VERSION ""

NS_ :

BS_:

BU_: Turbocharger OnBoardDataLogger OffBoardDiagnosticTool2 OffBoardDiagnosticTool1 FileServer ParkingBrakeController SeatControl2 FanDriveController SteeringColumnUnit CommunicationUnitRadio CommunicationUnitSatellite CommunicationUnitCellular PropulsionBatteryCharger ChassisController2 ChassisController1 EngineValveControl AuxiliaryHeater2 AuxiliaryHeater1 ClutchUnit RampControl InformationSystem1 SuspensionSystemController2 OilSensor VehicleDynamicStability ExhaustEmissionController TransmissionDisplay2 TransmissionDisplay1 ClimateControl2 WaterPumpController RearAxleSteeringController LightingOperatorControl SeatController1 IgnitionController2 IgnitionController1 TirePressureController CabController2 CabController1 PneumaticSystemController SuspensionSystemController1 HydraulicPumpController EnduranceBrakingSystem RetarderExhaustEngine2 OnBoardDiagnosticUnit HeadwayController RetarderExhaustEngine1 CabDisplay1 ManagementComputer VirtualTerminal OffVehicleGateway PowerTakeOffFront HitchControl AuxiliaryValveControl BodyController TractorTrailerBridge1 StarterSystem ElectricalSystem VehicleSecurity VehicleNavigation AerodynamicControl ElectricalChargingSystem ClimateControl1 TripRecorder InstrumentCluster SuspensionDriveAxle2 SuspensionDriveAxle1 SuspensionSteerAxle SteeringController FuelSystem CruiseControl RetarderDriveline RetarderEngine BrakesDriveAxle2 BrakesDriveAxle1 BrakesSystemController BrakesSteerAxle AxleDrive2 AxleDrive1 AxleSteering PowerTakeOff ShiftConsoleSecondary ShiftConsolePrimary Transmission2 Transmission1 Engine2 Engine1

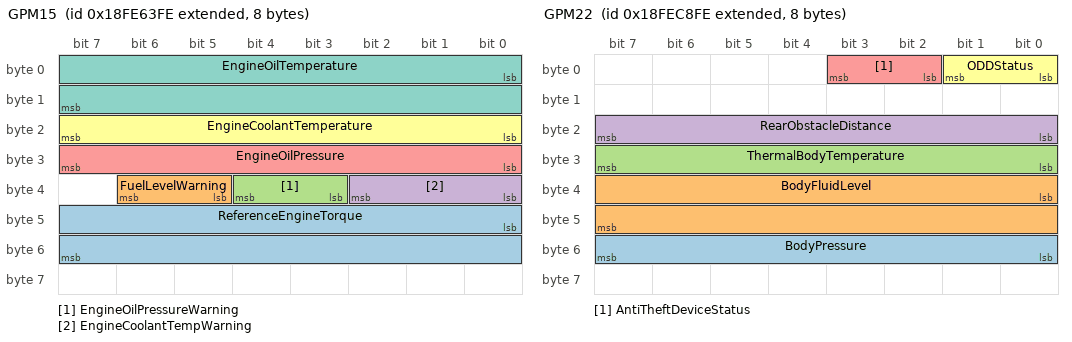
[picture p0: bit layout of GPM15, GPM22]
BO_ 2566808574 GPM15: 8 Vector__XXX
 SG_ ReferenceEngineTorque : 40|16@1+ (1,0) [0|64255] "Nm" Vector__XXX
 SG_ FuelLevelWarning : 37|2@1+ (1,0) [0|1] "" Vector__XXX
 SG_ EngineOilPressureWarning : 35|2@1+ (1,0) [0|1] "" Vector__XXX
 SG_ EngineCoolantTempWarning : 32|3@1+ (1,0) [0|2] "" Vector__XXX
 SG_ EngineOilPressure : 24|8@1+ (4,0) [0|1000] "kPa" Vector__XXX
 SG_ EngineCoolantTemperature : 16|8@1+ (1,-40) [-40|210] "�C" Vector__XXX
 SG_ EngineOilTemperature : 0|16@1+ (0.03125,-273) [-273|1735] "�C" Vector__XXX

BO_ 2566809086 GPM16: 8 Vector__XXX
 SG_ AmbientAirTemperature : 0|16@1+ (0.03125,-273) [-273|1735] "�C" Vector__XXX

BO_ 2564947710 GPM21: 8 Vector__XXX
 SG_ VehicleType : 0|2@1+ (1,0) [0|3] "" Vector__XXX

BO_ 2566834430 GPM22: 8 Vector__XXX
 SG_ BodyPressure : 48|8@1+ (0.1,0) [0|25] "bar" Vector__XXX
 SG_ BodyFluidLevel : 32|16@1+ (2,0) [0|128510] "L" Vector__XXX
 SG_ ThermalBodyTemperature : 24|8@1+ (1,-125) [-125|125] "�C" Vector__XXX
 SG_ RearObstacleDistance : 16|8@1+ (2,0) [0|500] "cm" Vector__XXX
 SG_ AntiTheftDeviceStatus : 2|2@1+ (1,0) [0|1] "" Vector__XXX
 SG_ ODDStatus : 0|2@1+ (1,0) [0|1] "" Vector__XXX

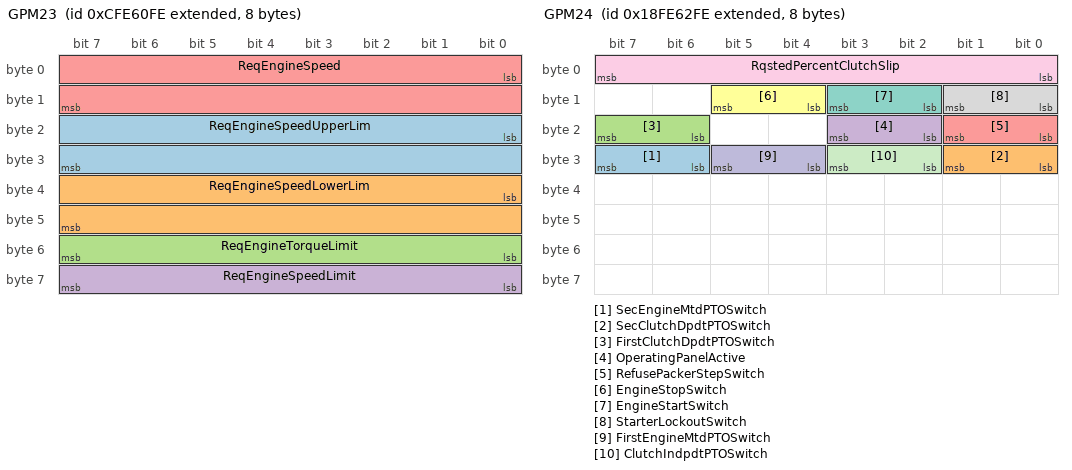
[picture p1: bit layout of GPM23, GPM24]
BO_ 2365481214 GPM23: 8 Vector__XXX
 SG_ ReqEngineSpeedUpperLim : 16|16@1+ (0.125,0) [0|8031.875] "rpm" Vector__XXX
 SG_ ReqEngineSpeedLowerLim : 32|16@1+ (0.125,0) [0|8031.875] "rpm" Vector__XXX
 SG_ ReqEngineTorqueLimit : 48|8@1+ (1,-125) [-125|125] "%" Vector__XXX
 SG_ ReqEngineSpeedLimit : 56|8@1+ (1,0) [0|250] "km/hr" Vector__XXX
 SG_ ReqEngineSpeed : 0|16@1+ (0.125,0) [0|8031.875] "rpm" Vector__XXX

BO_ 2566808318 GPM24: 8 Vector__XXX
 SG_ SecEngineMtdPTOSwitch : 30|2@1+ (1,0) [0|1] "" Vector__XXX
 SG_ SecClutchDpdtPTOSwitch : 24|2@1+ (1,0) [0|1] "" Vector__XXX
 SG_ FirstClutchDpdtPTOSwitch : 22|2@1+ (1,0) [0|1] "" Vector__XXX
 SG_ OperatingPanelActive : 18|2@1+ (1,0) [0|1] "" Vector__XXX
 SG_ RefusePackerStepSwitch : 16|2@1+ (1,0) [0|1] "" Vector__XXX
 SG_ EngineStopSwitch : 12|2@1+ (1,0) [0|1] "" Vector__XXX
 SG_ EngineStartSwitch : 10|2@1+ (1,0) [0|3] "" Vector__XXX
 SG_ StarterLockoutSwitch : 8|2@1+ (1,0) [0|1] "" Vector__XXX
 SG_ RqstedPercentClutchSlip : 0|8@1+ (0.4,0) [0|100] "%" Vector__XXX
 SG_ FirstEngineMtdPTOSwitch : 28|2@1+ (1,0) [0|1] "" Vector__XXX
 SG_ ClutchIndpdtPTOSwitch : 26|2@1+ (1,0) [0|1] "" Vector__XXX

BO_ 2566808830 GPM25: 8 Vector__XXX
 SG_ TrailerLeftSideMarkerLight : 20|2@1+ (1,0) [0|3] "" Vector__XXX
 SG_ TrailerLeftReversingLight : 16|2@1+ (1,0) [0|3] "" Vector__XXX
 SG_ TrailerLeftRearWidIndLight : 24|2@1+ (1,0) [0|3] "" Vector__XXX
 SG_ TrailerLeftRearRegPltLight : 32|2@1+ (1,0) [0|3] "" Vector__XXX
 SG_ TrailerLeftRearLight : 8|2@1+ (1,0) [0|3] "" Vector__XXX
 SG_ TrailerLeftRearFogLight : 12|2@1+ (1,0) [0|3] "" Vector__XXX
 SG_ TrailerLeftDirIndLight : 4|2@1+ (1,0) [0|3] "" Vector__XXX
 SG_ TrailerLeftCrnMarkerLight : 28|2@1+ (1,0) [0|3] "" Vector__XXX
 SG_ TrailerInteriorLight : 40|2@1+ (1,0) [0|3] "" Vector__XXX
 SG_ TrailerWorkLamp : 42|2@1+ (1,0) [0|3] "" Vector__XXX
 SG_ TrailerRotatingIdentLight : 38|2@1+ (1,0) [0|3] "" Vector__XXX
 SG_ TrailerRightStopLight : 2|2@1+ (1,0) [0|3] "" Vector__XXX
 SG_ TrailerRightSideMrkLight : 22|2@1+ (1,0) [0|3] "" Vector__XXX
 SG_ TrailerRightReversingLight : 18|2@1+ (1,0) [0|3] "" Vector__XXX
 SG_ TrailRightRearWidIndLight : 26|2@1+ (1,0) [0|3] "" Vector__XXX
 SG_ TrailerRightRearRegPltLight : 34|2@1+ (1,0) [0|3] "" Vector__XXX
 SG_ TrailerRightRearLight : 10|2@1+ (1,0) [0|3] "" Vector__XXX
 SG_ TrailerRightRearFogLight : 14|2@1+ (1,0) [0|3] "" Vector__XXX
 SG_ TrailerRightDirIndLight : 6|2@1+ (1,0) [0|3] "" Vector__XXX
 SG_ TrailerRightCrnMarkerLight : 30|2@1+ (1,0) [0|3] "" Vector__XXX
 SG_ TrailerRearWarningLight : 36|2@1+ (1,0) [0|3] "" Vector__XXX
 SG_ TrailerLeftStopLight : 0|2@1+ (1,0) [0|3] "" Vector__XXX

BO_ 2564554494 ISO15765_Funct: 8 Vector__XXX
 SG_ SN m2 : 0|4@1+ (1,0) [0|15] "" Vector__XXX
 SG_ SeparationTime m3 : 16|8@1+ (1,0) [0|255] "ms" Vector__XXX
 SG_ BlockSize m3 : 8|8@1+ (1,0) [0|255] "" Vector__XXX
 SG_ FlowStatus m3 : 0|4@1+ (1,0) [0|3] "" Vector__XXX
 SG_ FirstFrameDataLength m1 : 3|12@0+ (1,0) [0|4095] "Byte" Vector__XXX
 SG_ SingleFrameDataLength m0 : 0|4@1+ (1,0) [0|7] "Byte" Vector__XXX
 SG_ ProtocolCtrlInformation M : 4|4@1+ (1,0) [0|3] "" Vector__XXX

BO_ 2564488958 ISO15765_Phys: 8 Vector__XXX
 SG_ SN m2 : 0|4@1+ (1,0) [0|15] "" Vector__XXX
 SG_ SeparationTime m3 : 16|8@1+ (1,0) [0|255] "ms" Vector__XXX
 SG_ BlockSize m3 : 8|8@1+ (1,0) [0|255] "" Vector__XXX
 SG_ FlowStatus m3 : 0|4@1+ (1,0) [0|3] "" Vector__XXX
 SG_ FirstFrameDataLength m1 : 3|12@0+ (1,0) [0|4095] "Byte" Vector__XXX
 SG_ SingleFrameDataLength m0 : 0|4@1+ (1,0) [0|7] "Byte" Vector__XXX
 SG_ ProtocolCtrlInformation M : 4|4@1+ (1,0) [0|3] "" Vector__XXX

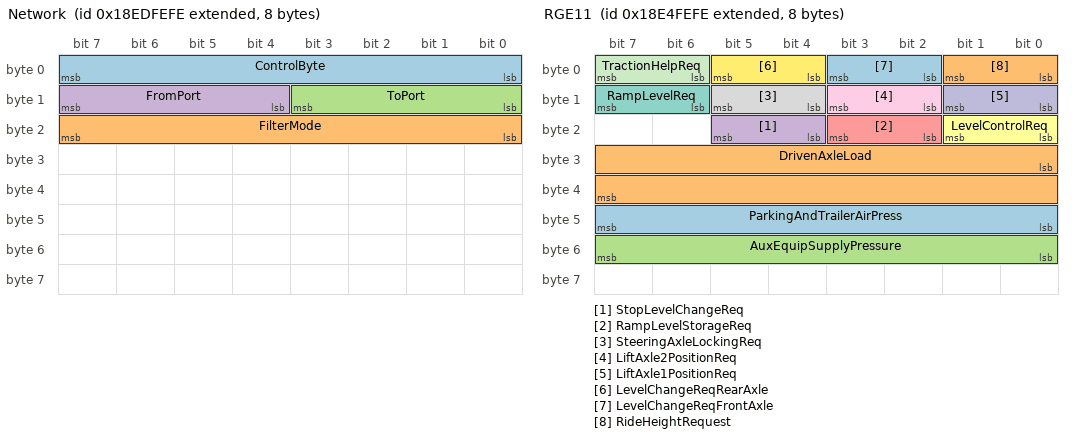
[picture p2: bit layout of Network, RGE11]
BO_ 2565734142 Network: 8 Vector__XXX
 SG_ ControlByte : 0|8@1+ (1,0) [0|255] "" Vector__XXX
 SG_ FilterMode : 16|8@1+ (1,0) [0|255] "" Vector__XXX
 SG_ ToPort : 8|4@1+ (1,0) [0|15] "" Vector__XXX
 SG_ FromPort : 12|4@1+ (1,0) [0|15] "" Vector__XXX

BO_ 2565144318 RGE11: 8 Vector__XXX
 SG_ ParkingAndTrailerAirPress : 40|8@1+ (8,0) [0|2000] "kPa" Vector__XXX
 SG_ DrivenAxleLoad : 24|16@1+ (2,0) [0|128510] "kg" Vector__XXX
 SG_ AuxEquipSupplyPressure : 48|8@1+ (8,0) [0|2000] "kPa" Vector__XXX
 SG_ StopLevelChangeReq : 20|2@1+ (1,0) [0|3] "" Vector__XXX
 SG_ RampLevelStorageReq : 18|2@1+ (1,0) [0|3] "" Vector__XXX
 SG_ LevelControlReq : 16|2@1+ (1,0) [0|3] "" Vector__XXX
 SG_ RampLevelReq : 14|2@1+ (1,0) [0|3] "" Vector__XXX
 SG_ SteeringAxleLockingReq : 12|2@1+ (1,0) [0|3] "" Vector__XXX
 SG_ LiftAxle2PositionReq : 10|2@1+ (1,0) [0|3] "" Vector__XXX
 SG_ LiftAxle1PositionReq : 8|2@1+ (1,0) [0|3] "" Vector__XXX
 SG_ TractionHelpReq : 6|2@1+ (1,0) [0|3] "" Vector__XXX
 SG_ LevelChangeReqRearAxle : 4|2@1+ (1,0) [0|3] "" Vector__XXX
 SG_ LevelChangeReqFrontAxle : 2|2@1+ (1,0) [0|3] "" Vector__XXX
 SG_ RideHeightRequest : 0|2@1+ (1,0) [0|3] "" Vector__XXX

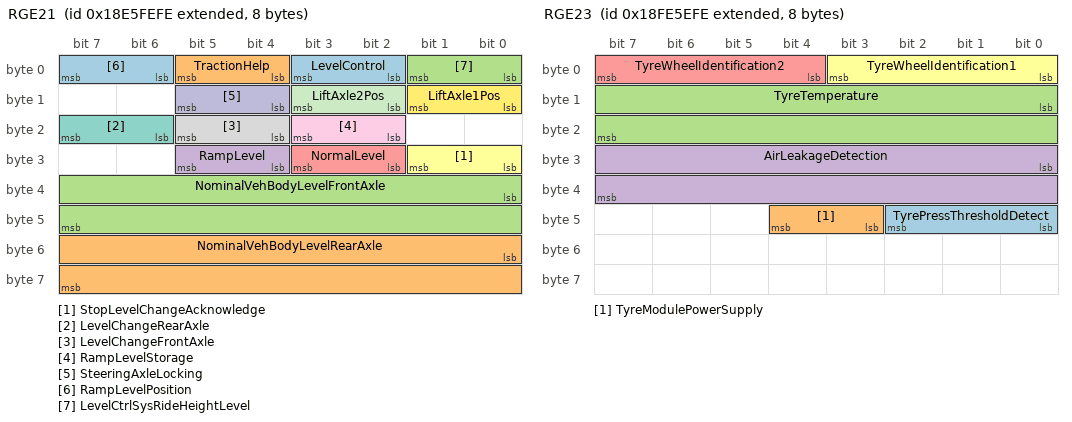
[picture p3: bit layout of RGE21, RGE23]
BO_ 2565209854 RGE21: 8 Vector__XXX
 SG_ LevelControl : 2|2@1+ (1,0) [0|1] "" Vector__XXX
 SG_ NominalVehBodyLevelRearAxle : 48|16@1+ (1,0) [0|64255] "mm" Vector__XXX
 SG_ NominalVehBodyLevelFrontAxle : 32|16@1+ (1,0) [0|64255] "mm" Vector__XXX
 SG_ RampLevel : 28|2@1+ (1,0) [0|1] "" Vector__XXX
 SG_ NormalLevel : 26|2@1+ (1,0) [0|3] "" Vector__XXX
 SG_ StopLevelChangeAcknowledge : 24|2@1+ (1,0) [0|1] "" Vector__XXX
 SG_ LevelChangeRearAxle : 22|2@1+ (1,0) [0|1] "" Vector__XXX
 SG_ LevelChangeFrontAxle : 20|2@1+ (1,0) [0|1] "" Vector__XXX
 SG_ RampLevelStorage : 18|2@1+ (1,0) [0|1] "" Vector__XXX
 SG_ SteeringAxleLocking : 12|2@1+ (1,0) [0|3] "" Vector__XXX
 SG_ LiftAxle2Pos : 10|2@1+ (1,0) [0|3] "" Vector__XXX
 SG_ LiftAxle1Pos : 8|2@1+ (1,0) [0|3] "" Vector__XXX
 SG_ RampLevelPosition : 6|2@1+ (1,0) [0|3] "" Vector__XXX
 SG_ TractionHelp : 4|2@1+ (1,0) [0|1] "" Vector__XXX
 SG_ LevelCtrlSysRideHeightLevel : 0|2@1+ (1,0) [0|1] "" Vector__XXX

BO_ 2566806782 RGE22: 8 Vector__XXX
 SG_ RelVehBodyLevelRearAxle : 16|16@1+ (1,0) [0|64255] "mm" Vector__XXX
 SG_ RelVehBodyLevelFrontAxle : 0|16@1+ (1,-32000) [-32000|32255] "mm" Vector__XXX

BO_ 2566807294 RGE23: 8 Vector__XXX
 SG_ TyrePressThresholdDetect : 40|3@1+ (1,0) [0|7] "" Vector__XXX
 SG_ TyreModulePowerSupply : 43|2@1+ (1,0) [0|1] "" Vector__XXX
 SG_ TyreTemperature : 8|16@1+ (0.03125,-273) [-273|1735] "�C" Vector__XXX
 SG_ AirLeakageDetection : 24|16@1+ (0.1,0) [0|6425.5] "Pa/s" Vector__XXX
 SG_ TyreWheelIdentification2 : 4|4@1+ (1,0) [0|15] "" Vector__XXX
 SG_ TyreWheelIdentification1 : 0|4@1+ (1,0) [0|15] "" Vector__XXX

BO_ 2566764798 DM26: 8 Vector__XXX
 SG_ NMHCConvertingCatalystCompleted : 60|1@1+ (1,0) [0|1] "" Vector__XXX
 SG_ NMHCConvertingCatalystEnabled : 44|1@1+ (1,0) [0|1] "" Vector__XXX
 SG_ NOxConvertingCatalystAdsorberCom : 59|1@1+ (1,0) [0|1] "" Vector__XXX
 SG_ NOxConvertingCatalystAdsorberEna : 43|1@1+ (1,0) [0|1] "" Vector__XXX
 SG_ DieselParticulateFilterCompleted : 58|1@1+ (1,0) [0|1] "" Vector__XXX
 SG_ DieselParticulateFilterEnabled : 42|1@1+ (1,0) [0|1] "" Vector__XXX
 SG_ BoostPressureControlSystemComple : 57|1@1+ (1,0) [0|1] "" Vector__XXX
 SG_ BoostPressureCtrlSystemEnabled : 41|1@1+ (1,0) [0|1] "" Vector__XXX
 SG_ MisfireMonitoringComplete : 28|1@1+ (1,0) [0|1] "" Vector__XXX
 SG_ MisfireMonitoringEnabled : 24|1@1+ (1,0) [0|0] "" Vector__XXX
 SG_ FuelSystemMonitoringEnabled : 25|1@1+ (1,0) [0|1] "" Vector__XXX
 SG_ ComprehensiveComptMonComplete : 30|1@1+ (1,0) [0|1] "" Vector__XXX
 SG_ ComprehensiveCompMonEnabled : 26|1@1+ (1,0) [0|1] "" Vector__XXX
 SG_ SecondAirSystemMonComplete : 51|1@1+ (1,0) [0|1] "" Vector__XXX
 SG_ SecondAirSystemMonEnabled : 35|1@1+ (1,0) [0|1] "" Vector__XXX
 SG_ OxygenSensorMonComplete : 53|1@1+ (1,0) [0|1] "" Vector__XXX
 SG_ OxygenSensorMonEnabled : 37|1@1+ (1,0) [0|1] "" Vector__XXX
 SG_ OxygenSensorHeaterMonComplete : 54|1@1+ (1,0) [0|1] "" Vector__XXX
 SG_ OxygenSensorHeaterMonEnabled : 38|1@1+ (1,0) [0|1] "" Vector__XXX
 SG_ HeatedCatalystMonComplete : 49|1@1+ (1,0) [0|1] "" Vector__XXX
 SG_ HeatedCatalystMonEnabled : 33|1@1+ (1,0) [0|1] "" Vector__XXX
 SG_ EvaporativeSystemMonComplete : 50|1@1+ (1,0) [0|1] "" Vector__XXX
 SG_ EvaporativeSystemMonEnabled : 34|1@1+ (1,0) [0|1] "" Vector__XXX
 SG_ EGRSystemMonitoringComplete : 55|1@1+ (1,0) [0|1] "" Vector__XXX
 SG_ EGRSystemMonitoringEnabled : 39|1@1+ (1,0) [0|1] "" Vector__XXX
 SG_ ColdStartAidSystemMonComplete : 56|1@1+ (1,0) [0|1] "" Vector__XXX
 SG_ ColdStartAidSystemMonEnabled : 40|1@1+ (1,0) [0|1] "" Vector__XXX
 SG_ CatalystMonComplete : 48|1@1+ (1,0) [0|1] "" Vector__XXX
 SG_ CatalystMonEnabled : 32|1@1+ (1,0) [0|1] "" Vector__XXX
 SG_ ACSystemRefrigerantMonComplete : 52|1@1+ (1,0) [0|1] "" Vector__XXX
 SG_ ACSystemRefrigerantMonEnabled : 36|1@1+ (1,0) [0|1] "" Vector__XXX
 SG_ FuelSystemMonitoringComplete : 29|1@1+ (1,0) [0|1] "" Vector__XXX
 SG_ NumOfWarmUpsSinceDTCsCleared : 16|8@1+ (1,0) [0|250] "" Vector__XXX
 SG_ TimeSinceEngineStart : 0|16@1+ (1,0) [0|64255] "sec" Vector__XXX

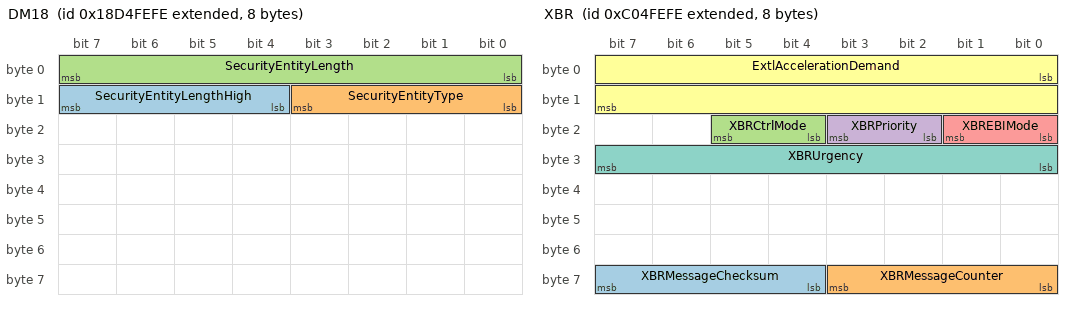
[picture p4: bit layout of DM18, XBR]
BO_ 2564095742 DM18: 8 Vector__XXX
 SG_ SecurityEntityLengthHigh : 12|4@1+ (1,0) [0|255] "Byte" Vector__XXX
 SG_ SecurityEntityType : 8|4@1+ (1,0) [0|15] "" Vector__XXX
 SG_ SecurityEntityLength : 0|8@1+ (1,0) [0|1785] "Byte" Vector__XXX

BO_ 2349137662 XBR: 8 Vector__XXX
 SG_ XBRMessageChecksum : 60|4@1+ (1,0) [0|15] "" Vector__XXX
 SG_ XBRMessageCounter : 56|4@1+ (1,0) [0|15] "" Vector__XXX
 SG_ XBRCtrlMode : 20|2@1+ (1,0) [0|3] "" Vector__XXX
 SG_ XBRPriority : 18|2@1+ (1,0) [0|3] "" Vector__XXX
 SG_ XBREBIMode : 16|2@1+ (1,0) [0|3] "" Vector__XXX
 SG_ ExtlAccelerationDemand : 0|16@1+ (0.00048828125,-15.687) [-15.687|15.687] "m/s�" Vector__XXX
 SG_ XBRUrgency : 24|8@1+ (0.4,0) [0|100] "%" Vector__XXX

BO_ 2566848510 WFI: 8 Vector__XXX
 SG_ WaterInFuelIndicator : 0|2@1+ (1,0) [0|3] "" Vector__XXX

BO_ 2566843134 VW: 8 Vector__XXX
 SG_ AxleLocation M : 0|8@1+ (1,0) [0|255] "" Vector__XXX
 SG_ CargoWeight_30 m48 : 40|16@1+ (2,0) [0|128510] "kg" Vector__XXX
 SG_ CargoWeight_20 m32 : 40|16@1+ (2,0) [0|128510] "kg" Vector__XXX
 SG_ CargoWeight_10 m16 : 40|16@1+ (2,0) [0|128510] "kg" Vector__XXX
 SG_ CargoWeight_00 m0 : 40|16@1+ (2,0) [0|128510] "kg" Vector__XXX
 SG_ TrailerWeight_30 m48 : 24|16@1+ (2,0) [0|128510] "kg" Vector__XXX
 SG_ TrailerWeight_20 m32 : 24|16@1+ (2,0) [0|128510] "kg" Vector__XXX
 SG_ TrailerWeight_10 m16 : 24|16@1+ (2,0) [0|128510] "kg" Vector__XXX
 SG_ TrailerWeight_00 m0 : 24|16@1+ (2,0) [0|128510] "kg" Vector__XXX
 SG_ AxleWeight_30 m48 : 8|16@1+ (0.5,0) [0|32127.5] "kg" Vector__XXX
 SG_ AxleWeight_20 m32 : 8|16@1+ (0.5,0) [0|32127.5] "kg" Vector__XXX
 SG_ AxleWeight_10 m16 : 8|16@1+ (0.5,0) [0|32127.5] "kg" Vector__XXX
 SG_ AxleWeight_00 m0 : 8|16@1+ (0.5,0) [0|32127.5] "kg" Vector__XXX

BO_ 2566804222 VEP3: 8 Vector__XXX
 SG_ NetBatteryCurrentHiRes : 16|16@1+ (0.05,-1600) [-1600|1612.75] "A" Vector__XXX
 SG_ AltCurrentHiRes : 0|16@1+ (0.05,-1600) [-1600|1676.75] "A" Vector__XXX

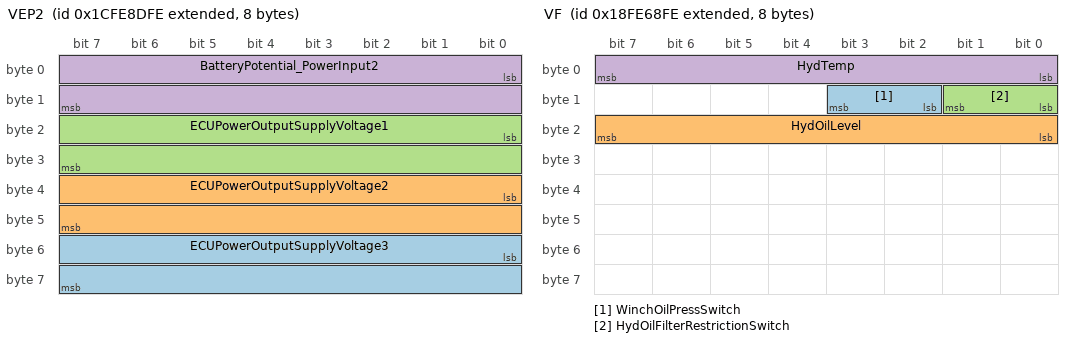
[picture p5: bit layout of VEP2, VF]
BO_ 2633928190 VEP2: 8 Vector__XXX
 SG_ ECUPowerOutputSupplyVoltage3 : 48|16@1+ (0.05,0) [0|3212.75] "V" Vector__XXX
 SG_ ECUPowerOutputSupplyVoltage2 : 32|16@1+ (0.05,0) [0|3212.75] "V" Vector__XXX
 SG_ ECUPowerOutputSupplyVoltage1 : 16|16@1+ (0.05,0) [0|3212.75] "V" Vector__XXX
 SG_ BatteryPotential_PowerInput2 : 0|16@1+ (0.05,0) [0|3212.75] "V" Vector__XXX

BO_ 2566845438 VP: 8 Vector__XXX
 SG_ Longitude : 32|32@1+ (10,-210) [-210|211.1008122] "deg" Vector__XXX
 SG_ Latitude : 0|32@1+ (10,-210) [-210|211.1008122] "deg" Vector__XXX

BO_ 2566843646 VI: 8 Vector__XXX
 SG_ VehicleIdentificationNumber : 0|8@1+ (1,0) [0|255] "" Vector__XXX

BO_ 2566842366 VH: 8 Vector__XXX
 SG_ TotalPowerTakeoffHours : 32|32@1+ (0.05,0) [0|210554060.75] "hr" Vector__XXX
 SG_ TotalVehicleHours : 0|32@1+ (0.05,0) [0|210554060.75] "hr" Vector__XXX

BO_ 2566809854 VF: 8 Vector__XXX
 SG_ WinchOilPressSwitch : 10|2@1+ (1,0) [0|3] "" Vector__XXX
 SG_ HydOilLevel : 16|8@1+ (0.4,0) [0|100] "%" Vector__XXX
 SG_ HydOilFilterRestrictionSwitch : 8|2@1+ (1,0) [0|3] "" Vector__XXX
 SG_ HydTemp : 0|8@1+ (1,-40) [-40|210] "deg C" Vector__XXX

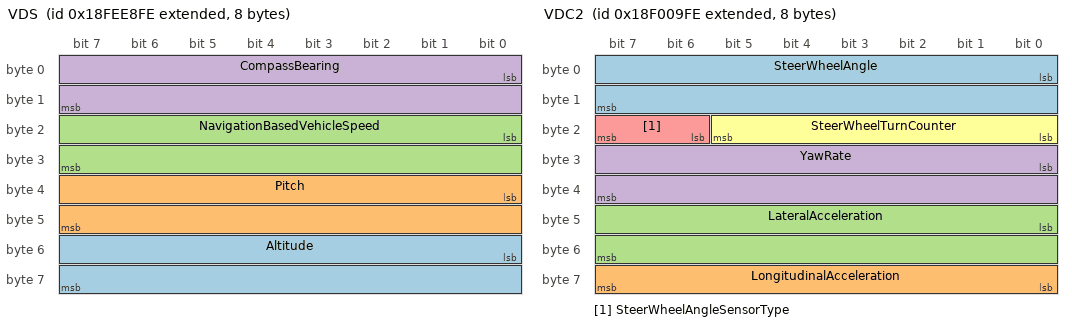
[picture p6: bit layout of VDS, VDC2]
BO_ 2566842622 VDS: 8 Vector__XXX
 SG_ Altitude : 48|16@1+ (0.125,-2500) [-2500|5531.875] "m" Vector__XXX
 SG_ Pitch : 32|16@1+ (0.0078125,-200) [-200|301.99] "deg" Vector__XXX
 SG_ NavigationBasedVehicleSpeed : 16|16@1+ (0.00390625,0) [0|250.996] "km/h" Vector__XXX
 SG_ CompassBearing : 0|16@1+ (0.0078125,0) [0|501.99] "deg" Vector__XXX

BO_ 2566832638 VDHR: 8 Vector__XXX
 SG_ HighResolutionTripDistance : 32|32@1+ (5,0) [0|21055406] "km" Vector__XXX
 SG_ HghRslutionTotalVehicleDistance : 0|32@1+ (5,0) [0|21055406] "km" Vector__XXX

BO_ 2565868030 VDC2: 8 Vector__XXX
 SG_ SteerWheelAngle : 0|16@1+ (0.0009765625,-31.374) [-31.374|31.374] "rad" Vector__XXX
 SG_ LongitudinalAcceleration : 56|8@1+ (0.1,-12.5) [-12.5|12.5] "m/s�" Vector__XXX
 SG_ LateralAcceleration : 40|16@1+ (0.00048828125,-15.687) [-15.687|15.687] "m/s�" Vector__XXX
 SG_ YawRate : 24|16@1+ (0.0001220703125,-3.92) [-3.92|3.92] "rad/s" Vector__XXX
 SG_ SteerWheelAngleSensorType : 22|2@1+ (1,0) [0|3] "" Vector__XXX
 SG_ SteerWheelTurnCounter : 16|6@1+ (1,-32) [-32|29] "turns" Vector__XXX

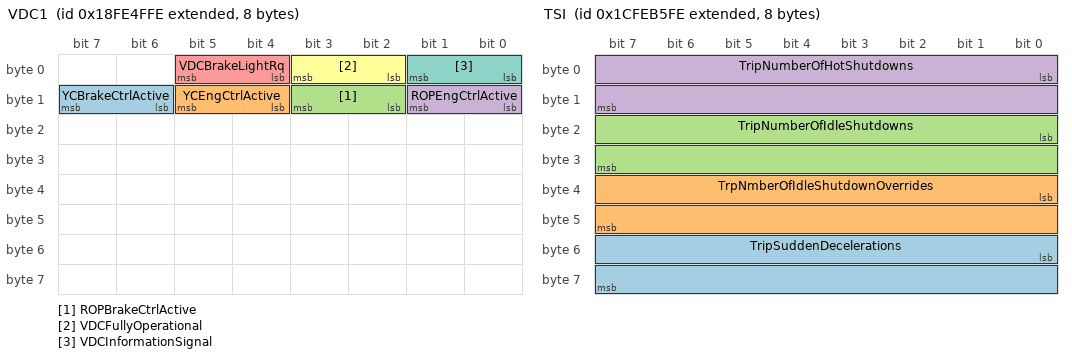
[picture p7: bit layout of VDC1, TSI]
BO_ 2566803454 VDC1: 8 Vector__XXX
 SG_ YCBrakeCtrlActive : 14|2@1+ (1,0) [0|3] "" Vector__XXX
 SG_ YCEngCtrlActive : 12|2@1+ (1,0) [0|3] "" Vector__XXX
 SG_ ROPBrakeCtrlActive : 10|2@1+ (1,0) [0|3] "" Vector__XXX
 SG_ ROPEngCtrlActive : 8|2@1+ (1,0) [0|3] "" Vector__XXX
 SG_ VDCBrakeLightRq : 4|2@1+ (1,0) [0|3] "" Vector__XXX
 SG_ VDCFullyOperational : 2|2@1+ (1,0) [0|3] "" Vector__XXX
 SG_ VDCInformationSignal : 0|2@1+ (1,0) [0|3] "" Vector__XXX

BO_ 2566840574 VD: 8 Vector__XXX
 SG_ TotalVehicleDistance : 32|32@1+ (0.125,0) [0|526385151.9] "km" Vector__XXX
 SG_ TripDistance : 0|32@1+ (0.125,0) [0|526385151.9] "km" Vector__XXX

BO_ 2633938686 TVI: 8 Vector__XXX
 SG_ TripCruiseDistance : 16|32@1+ (0.125,0) [0|526385151.9] "km" Vector__XXX
 SG_ TripMaxVehicleSpeed : 0|16@1+ (0.00390625,0) [0|250.996] "km/h" Vector__XXX

BO_ 2633937150 TTI2: 20 Vector__XXX
 SG_ TripAirCompressorOnTime : 128|32@1+ (0.05,0) [0|210554060.75] "hr" Vector__XXX
 SG_ TripIdleTime : 96|32@1+ (0.05,0) [0|210554060.75] "hr" Vector__XXX
 SG_ TripEngRunningTime : 64|32@1+ (0.05,0) [0|210554060.75] "hr" Vector__XXX
 SG_ TripCruiseTime : 0|32@1+ (0.05,0) [0|210554060.75] "hr" Vector__XXX
 SG_ TripPTOGovernorTime : 32|32@1+ (0.05,0) [0|210554060.75] "hr" Vector__XXX

BO_ 2633938174 TTI1: 16 Vector__XXX
 SG_ TripTimeInDerateByEng : 96|32@1+ (0.05,0) [0|210554060.75] "hr" Vector__XXX
 SG_ TripTimeInGearDown : 64|32@1+ (0.05,0) [0|210554060.75] "hr" Vector__XXX
 SG_ TripTimeInTopGear : 32|32@1+ (0.05,0) [0|210554060.75] "hr" Vector__XXX
 SG_ TripTimeInVSL : 0|32@1+ (0.05,0) [0|210554060.75] "hr" Vector__XXX

BO_ 2633938430 TSI: 8 Vector__XXX
 SG_ TripSuddenDecelerations : 48|16@1+ (1,0) [0|64255] "counts" Vector__XXX
 SG_ TrpNmberOfIdleShutdownOverrides : 32|16@1+ (1,0) [0|64255] "counts" Vector__XXX
 SG_ TripNumberOfIdleShutdowns : 16|16@1+ (1,0) [0|64255] "counts" Vector__XXX
 SG_ TripNumberOfHotShutdowns : 0|16@1+ (1,0) [0|64255] "counts" Vector__XXX

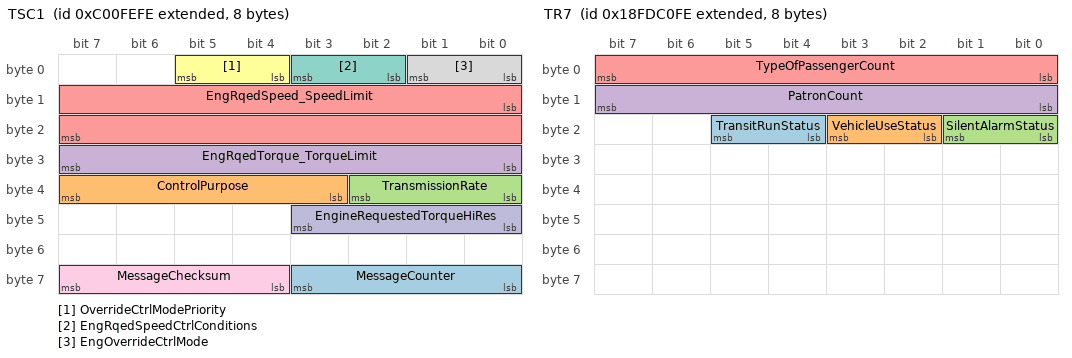
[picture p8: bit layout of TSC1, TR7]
BO_ 2348875518 TSC1: 8 Vector__XXX
 SG_ MessageCounter : 56|4@1+ (1,0) [0|15] "" Vector__XXX
 SG_ ControlPurpose : 35|5@1+ (1,0) [0|31] "" Vector__XXX
 SG_ TransmissionRate : 32|3@1+ (1,0) [0|7] "" Vector__XXX
 SG_ EngRqedTorque_TorqueLimit : 24|8@1+ (1,-125) [-125|125] "%" Vector__XXX
 SG_ EngRqedSpeed_SpeedLimit : 8|16@1+ (0.125,0) [0|8031.875] "rpm" Vector__XXX
 SG_ OverrideCtrlModePriority : 4|2@1+ (1,0) [0|3] "" Vector__XXX
 SG_ EngRqedSpeedCtrlConditions : 2|2@1+ (1,0) [0|3] "" Vector__XXX
 SG_ EngOverrideCtrlMode : 0|2@1+ (1,0) [0|3] "" Vector__XXX
 SG_ MessageChecksum : 60|4@1+ (1,0) [0|15] "" Vector__XXX
 SG_ EngineRequestedTorqueHiRes : 40|4@1+ (0.125,0) [0|0.875] "%" Vector__XXX

BO_ 2566766846 TR7: 8 Vector__XXX
 SG_ TransitRunStatus : 20|2@1+ (1,0) [0|3] "" Vector__XXX
 SG_ VehicleUseStatus : 18|2@1+ (1,0) [0|3] "" Vector__XXX
 SG_ SilentAlarmStatus : 16|2@1+ (1,0) [0|3] "" Vector__XXX
 SG_ PatronCount : 8|8@1+ (1,0) [0|250] "" Vector__XXX
 SG_ TypeOfPassengerCount : 0|8@1+ (1,0) [0|255] "" Vector__XXX

BO_ 2566765310 TR6: 8 Vector__XXX
 SG_ FareboxAlarmIdentifier : 8|7@1+ (1,0) [0|127] "" Vector__XXX
 SG_ FareboxEmergencyStatus : 0|2@1+ (1,0) [0|3] "" Vector__XXX

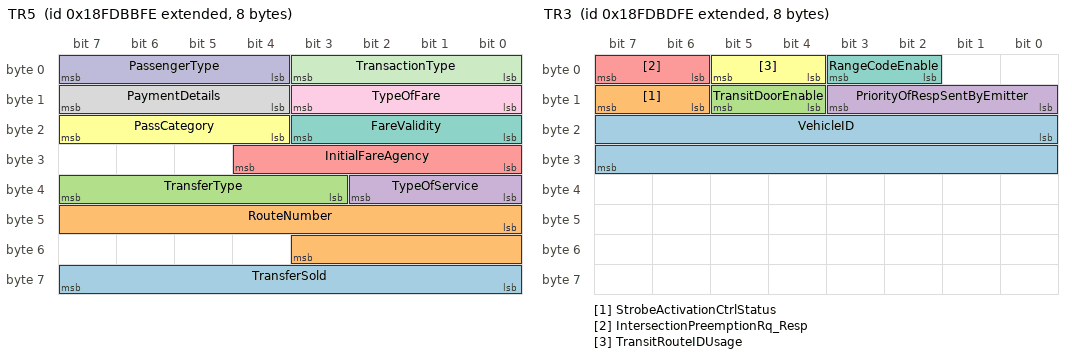
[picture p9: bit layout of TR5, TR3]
BO_ 2566765566 TR5: 8 Vector__XXX
 SG_ TransferSold : 56|8@1+ (1,0) [0|255] "" Vector__XXX
 SG_ RouteNumber : 40|12@1+ (1,0) [0|4095] "" Vector__XXX
 SG_ TransferType : 35|5@1+ (1,0) [0|31] "" Vector__XXX
 SG_ TypeOfService : 32|3@1+ (1,0) [0|7] "" Vector__XXX
 SG_ InitialFareAgency : 24|5@1+ (1,0) [0|31] "" Vector__XXX
 SG_ PassCategory : 20|4@1+ (1,0) [0|15] "" Vector__XXX
 SG_ FareValidity : 16|4@1+ (1,0) [0|15] "" Vector__XXX
 SG_ PaymentDetails : 12|4@1+ (1,0) [0|15] "" Vector__XXX
 SG_ TypeOfFare : 8|4@1+ (1,0) [0|15] "" Vector__XXX
 SG_ PassengerType : 4|4@1+ (1,0) [0|15] "" Vector__XXX
 SG_ TransactionType : 0|4@1+ (1,0) [0|15] "" Vector__XXX

BO_ 2566765822 TR4: 15 Vector__XXX
 SG_ DriversFareboxSecurityCode : 104|16@1+ (1,0) [0|65535] "counts" Vector__XXX
 SG_ AssignedBlock : 88|16@1+ (1,0) [0|65535] "counts" Vector__XXX
 SG_ AssignedRun : 72|16@1+ (1,0) [0|65535] "counts" Vector__XXX
 SG_ AssignedRoute : 56|16@1+ (1,0) [0|65535] "counts" Vector__XXX
 SG_ PatternNumber : 40|16@1+ (1,0) [0|65535] "counts" Vector__XXX
 SG_ TripNumber : 24|16@1+ (1,0) [0|65535] "counts" Vector__XXX
 SG_ FarePresets : 16|8@1+ (1,0) [0|255] "" Vector__XXX
 SG_ TripDirection : 8|4@1+ (1,0) [0|15] "" Vector__XXX
 SG_ TripStatus : 2|3@1+ (1,0) [0|7] "" Vector__XXX
 SG_ FareboxServiceStatus : 0|2@1+ (1,0) [0|3] "" Vector__XXX

BO_ 2566766078 TR3: 8 Vector__XXX
 SG_ VehicleID : 16|16@1+ (1,0) [0|65535] "counts" Vector__XXX
 SG_ StrobeActivationCtrlStatus : 14|2@1+ (1,0) [0|3] "" Vector__XXX
 SG_ TransitDoorEnable : 12|2@1+ (1,0) [0|3] "" Vector__XXX
 SG_ PriorityOfRespSentByEmitter : 8|4@1+ (1,0) [0|15] "" Vector__XXX
 SG_ IntersectionPreemptionRq_Resp : 6|2@1+ (1,0) [0|3] "" Vector__XXX
 SG_ TransitRouteIDUsage : 4|2@1+ (1,0) [0|3] "" Vector__XXX
 SG_ RangeCodeEnable : 2|2@1+ (1,0) [0|3] "" Vector__XXX

BO_ 2566766590 TR2: 8 Vector__XXX
 SG_ NmbrOfBytsInMlpstIdentification : 0|8@1+ (1,0) [0|250] "" Vector__XXX

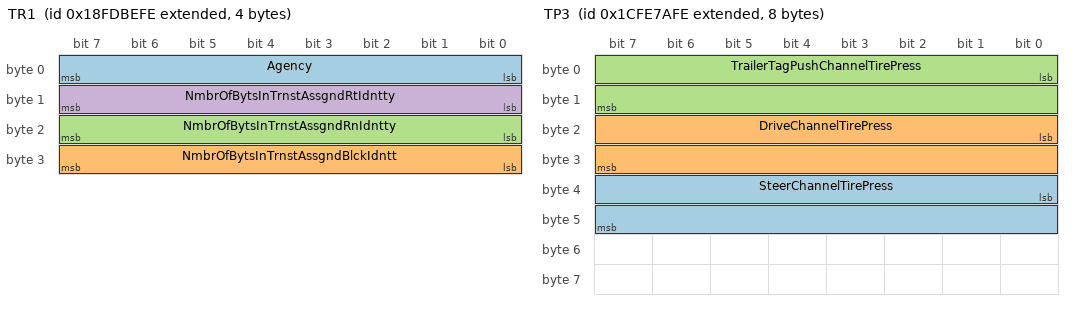
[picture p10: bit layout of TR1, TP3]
BO_ 2566766334 TR1: 4 Vector__XXX
 SG_ Agency : 0|8@1+ (1,0) [0|255] "" Vector__XXX
 SG_ NmbrOfBytsInTrnstAssgndBlckIdntt : 24|8@1+ (1,0) [0|250] "" Vector__XXX
 SG_ NmbrOfBytsInTrnstAssgndRnIdntty : 16|8@1+ (1,0) [0|250] "" Vector__XXX
 SG_ NmbrOfBytsInTrnstAssgndRtIdntty : 8|8@1+ (1,0) [0|250] "" Vector__XXX

BO_ 2561605374 TPRS: 8 Vector__XXX
 SG_ ReferenceTirePressSetting_33 m51 : 8|8@1+ (8,0) [0|2000] "kPa" Vector__XXX
 SG_ ReferenceTirePressSetting_32 m50 : 8|8@1+ (8,0) [0|2000] "kPa" Vector__XXX
 SG_ ReferenceTirePressSetting_31 m49 : 8|8@1+ (8,0) [0|2000] "kPa" Vector__XXX
 SG_ ReferenceTirePressSetting_30 m48 : 8|8@1+ (8,0) [0|2000] "kPa" Vector__XXX
 SG_ ReferenceTirePressSetting_23 m35 : 8|8@1+ (8,0) [0|2000] "kPa" Vector__XXX
 SG_ ReferenceTirePressSetting_22 m34 : 8|8@1+ (8,0) [0|2000] "kPa" Vector__XXX
 SG_ ReferenceTirePressSetting_21 m33 : 8|8@1+ (8,0) [0|2000] "kPa" Vector__XXX
 SG_ ReferenceTirePressSetting_20 m32 : 8|8@1+ (8,0) [0|2000] "kPa" Vector__XXX
 SG_ ReferenceTirePressSetting_13 m19 : 8|8@1+ (8,0) [0|2000] "kPa" Vector__XXX
 SG_ ReferenceTirePressSetting_12 m18 : 8|8@1+ (8,0) [0|2000] "kPa" Vector__XXX
 SG_ ReferenceTirePressSetting_11 m17 : 8|8@1+ (8,0) [0|2000] "kPa" Vector__XXX
 SG_ ReferenceTirePressSetting_10 m16 : 8|8@1+ (8,0) [0|2000] "kPa" Vector__XXX
 SG_ ReferenceTirePressSetting_01 m1 : 8|8@1+ (8,0) [0|2000] "kPa" Vector__XXX
 SG_ ReferenceTirePressSetting_00 m0 : 8|8@1+ (8,0) [0|2000] "kPa" Vector__XXX
 SG_ TireLocation M : 0|8@1+ (1,0) [0|255] "" Vector__XXX

BO_ 2566765054 TPRI: 8 Vector__XXX
 SG_ ReferenceTirePress_33 m51 : 8|8@1+ (8,0) [0|2000] "kPa" Vector__XXX
 SG_ ReferenceTirePress_32 m50 : 8|8@1+ (8,0) [0|2000] "kPa" Vector__XXX
 SG_ ReferenceTirePress_31 m49 : 8|8@1+ (8,0) [0|2000] "kPa" Vector__XXX
 SG_ ReferenceTirePress_30 m48 : 8|8@1+ (8,0) [0|2000] "kPa" Vector__XXX
 SG_ ReferenceTirePress_23 m35 : 8|8@1+ (8,0) [0|2000] "kPa" Vector__XXX
 SG_ ReferenceTirePress_22 m34 : 8|8@1+ (8,0) [0|2000] "kPa" Vector__XXX
 SG_ ReferenceTirePress_21 m33 : 8|8@1+ (8,0) [0|2000] "kPa" Vector__XXX
 SG_ ReferenceTirePress_20 m32 : 8|8@1+ (8,0) [0|2000] "kPa" Vector__XXX
 SG_ ReferenceTirePress_13 m19 : 8|8@1+ (8,0) [0|2000] "kPa" Vector__XXX
 SG_ ReferenceTirePress_12 m18 : 8|8@1+ (8,0) [0|2000] "kPa" Vector__XXX
 SG_ ReferenceTirePress_11 m17 : 8|8@1+ (8,0) [0|2000] "kPa" Vector__XXX
 SG_ ReferenceTirePress_10 m16 : 8|8@1+ (8,0) [0|2000] "kPa" Vector__XXX
 SG_ ReferenceTirePress_01 m1 : 8|8@1+ (8,0) [0|2000] "kPa" Vector__XXX
 SG_ ReferenceTirePress_00 m0 : 8|8@1+ (8,0) [0|2000] "kPa" Vector__XXX
 SG_ TireLocation M : 0|8@1+ (1,0) [0|255] "" Vector__XXX

BO_ 2633923326 TP3: 8 Vector__XXX
 SG_ SteerChannelTirePress : 32|16@1+ (0.5,0) [0|32127.5] "kPa" Vector__XXX
 SG_ DriveChannelTirePress : 16|16@1+ (0.5,0) [0|32127.5] "kPa" Vector__XXX
 SG_ TrailerTagPushChannelTirePress : 0|16@1+ (0.5,0) [0|32127.5] "kPa" Vector__XXX

BO_ 2633923070 TP2: 8 Vector__XXX
 SG_ SteerChannelTirePressTarget : 32|16@1+ (0.5,0) [0|32127.5] "kPa" Vector__XXX
 SG_ DriveChannelTirePressTarget : 16|16@1+ (0.5,0) [0|32127.5] "kPa" Vector__XXX
 SG_ TrlrTgPshChannelTirePressTarget : 0|16@1+ (0.5,0) [0|32127.5] "kPa" Vector__XXX

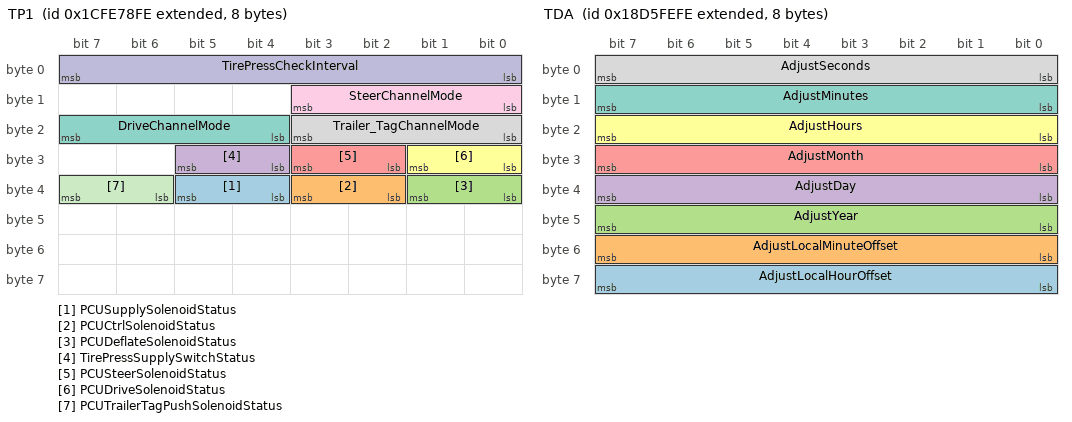
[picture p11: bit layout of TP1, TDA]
BO_ 2633922814 TP1: 8 Vector__XXX
 SG_ PCUSupplySolenoidStatus : 36|2@1+ (1,0) [0|3] "" Vector__XXX
 SG_ PCUCtrlSolenoidStatus : 34|2@1+ (1,0) [0|3] "" Vector__XXX
 SG_ PCUDeflateSolenoidStatus : 32|2@1+ (1,0) [0|3] "" Vector__XXX
 SG_ TirePressSupplySwitchStatus : 28|2@1+ (1,0) [0|3] "" Vector__XXX
 SG_ PCUSteerSolenoidStatus : 26|2@1+ (1,0) [0|3] "" Vector__XXX
 SG_ PCUDriveSolenoidStatus : 24|2@1+ (1,0) [0|3] "" Vector__XXX
 SG_ DriveChannelMode : 20|4@1+ (1,0) [0|15] "" Vector__XXX
 SG_ Trailer_TagChannelMode : 16|4@1+ (1,0) [0|15] "" Vector__XXX
 SG_ SteerChannelMode : 8|4@1+ (1,0) [0|15] "" Vector__XXX
 SG_ TirePressCheckInterval : 0|8@1+ (1,0) [0|250] "mins" Vector__XXX
 SG_ PCUTrailerTagPushSolenoidStatus : 38|2@1+ (1,0) [0|3] "" Vector__XXX

BO_ 2566845694 TIRE: 8 Vector__XXX
 SG_ TirePressThresholdDetection_13 m19 : 61|3@1+ (1,0) [0|7] "" Vector__XXX
 SG_ TirePressThresholdDetection_12 m18 : 61|3@1+ (1,0) [0|7] "" Vector__XXX
 SG_ TirePressThresholdDetection_11 m17 : 61|3@1+ (1,0) [0|7] "" Vector__XXX
 SG_ TirePressThresholdDetection_10 m16 : 61|3@1+ (1,0) [0|7] "" Vector__XXX
 SG_ TirePressThresholdDetection_01 m1 : 61|3@1+ (1,0) [0|7] "" Vector__XXX
 SG_ TirePress_33 m51 : 8|8@1+ (4,0) [0|1000] "kPa" Vector__XXX
 SG_ TirePress_32 m50 : 8|8@1+ (4,0) [0|1000] "kPa" Vector__XXX
 SG_ TirePress_31 m49 : 8|8@1+ (4,0) [0|1000] "kPa" Vector__XXX
 SG_ TirePress_30 m48 : 8|8@1+ (4,0) [0|1000] "kPa" Vector__XXX
 SG_ TirePress_23 m35 : 8|8@1+ (4,0) [0|1000] "kPa" Vector__XXX
 SG_ TirePress_22 m34 : 8|8@1+ (4,0) [0|1000] "kPa" Vector__XXX
 SG_ TirePress_21 m33 : 8|8@1+ (4,0) [0|1000] "kPa" Vector__XXX
 SG_ TirePress_20 m32 : 8|8@1+ (4,0) [0|1000] "kPa" Vector__XXX
 SG_ TirePress_13 m19 : 8|8@1+ (4,0) [0|1000] "kPa" Vector__XXX
 SG_ TirePress_12 m18 : 8|8@1+ (4,0) [0|1000] "kPa" Vector__XXX
 SG_ TirePress_11 m17 : 8|8@1+ (4,0) [0|1000] "kPa" Vector__XXX
 SG_ TirePress_10 m16 : 8|8@1+ (4,0) [0|1000] "kPa" Vector__XXX
 SG_ TireAirLeakageRate_33 m51 : 40|16@1+ (0.1,0) [0|6425.5] "Pa/s" Vector__XXX
 SG_ TireAirLeakageRate_32 m50 : 40|16@1+ (0.1,0) [0|6425.5] "Pa/s" Vector__XXX
 SG_ TireAirLeakageRate_31 m49 : 40|16@1+ (0.1,0) [0|6425.5] "Pa/s" Vector__XXX
 SG_ TireAirLeakageRate_30 m48 : 40|16@1+ (0.1,0) [0|6425.5] "Pa/s" Vector__XXX
 SG_ TireAirLeakageRate_23 m35 : 40|16@1+ (0.1,0) [0|6425.5] "Pa/s" Vector__XXX
 SG_ TireAirLeakageRate_22 m34 : 40|16@1+ (0.1,0) [0|6425.5] "Pa/s" Vector__XXX
 SG_ TireAirLeakageRate_21 m33 : 40|16@1+ (0.1,0) [0|6425.5] "Pa/s" Vector__XXX
 SG_ TireAirLeakageRate_20 m32 : 40|16@1+ (0.1,0) [0|6425.5] "Pa/s" Vector__XXX
 SG_ TireAirLeakageRate_13 m19 : 40|16@1+ (0.1,0) [0|6425.5] "Pa/s" Vector__XXX
 SG_ TireAirLeakageRate_12 m18 : 40|16@1+ (0.1,0) [0|6425.5] "Pa/s" Vector__XXX
 SG_ TireAirLeakageRate_11 m17 : 40|16@1+ (0.1,0) [0|6425.5] "Pa/s" Vector__XXX
 SG_ TireAirLeakageRate_10 m16 : 40|16@1+ (0.1,0) [0|6425.5] "Pa/s" Vector__XXX
 SG_ TireAirLeakageRate_01 m1 : 40|16@1+ (0.1,0) [0|6425.5] "Pa/s" Vector__XXX
 SG_ TireAirLeakageRate_00 m0 : 40|16@1+ (0.1,0) [0|6425.5] "Pa/s" Vector__XXX
 SG_ CTIWheelSensorStatus_33 m51 : 32|2@1+ (1,0) [0|3] "" Vector__XXX
 SG_ CTIWheelSensorStatus_32 m50 : 32|2@1+ (1,0) [0|3] "" Vector__XXX
 SG_ CTIWheelSensorStatus_31 m49 : 32|2@1+ (1,0) [0|3] "" Vector__XXX
 SG_ CTIWheelSensorStatus_30 m48 : 32|2@1+ (1,0) [0|3] "" Vector__XXX
 SG_ CTIWheelSensorStatus_23 m35 : 32|2@1+ (1,0) [0|3] "" Vector__XXX
 SG_ CTIWheelSensorStatus_22 m34 : 32|2@1+ (1,0) [0|3] "" Vector__XXX
 SG_ CTIWheelSensorStatus_21 m33 : 32|2@1+ (1,0) [0|3] "" Vector__XXX
 SG_ CTIWheelSensorStatus_20 m32 : 32|2@1+ (1,0) [0|3] "" Vector__XXX
 SG_ CTIWheelSensorStatus_13 m19 : 32|2@1+ (1,0) [0|3] "" Vector__XXX
 SG_ CTIWheelSensorStatus_12 m18 : 32|2@1+ (1,0) [0|3] "" Vector__XXX
 SG_ CTIWheelSensorStatus_11 m17 : 32|2@1+ (1,0) [0|3] "" Vector__XXX
 SG_ CTIWheelSensorStatus_10 m16 : 32|2@1+ (1,0) [0|3] "" Vector__XXX
 SG_ CTIWheelSensorStatus_01 m1 : 32|2@1+ (1,0) [0|3] "" Vector__XXX
 SG_ CTIWheelEndElectricalFault_33 m51 : 36|2@1+ (1,0) [0|3] "" Vector__XXX
 SG_ CTIWheelEndElectricalFault_32 m50 : 36|2@1+ (1,0) [0|3] "" Vector__XXX
 SG_ CTIWheelEndElectricalFault_31 m49 : 36|2@1+ (1,0) [0|3] "" Vector__XXX
 SG_ CTIWheelEndElectricalFault_30 m48 : 36|2@1+ (1,0) [0|3] "" Vector__XXX
 SG_ CTIWheelEndElectricalFault_23 m35 : 36|2@1+ (1,0) [0|3] "" Vector__XXX
 SG_ CTIWheelEndElectricalFault_22 m34 : 36|2@1+ (1,0) [0|3] "" Vector__XXX
 SG_ CTIWheelEndElectricalFault_21 m33 : 36|2@1+ (1,0) [0|3] "" Vector__XXX
 SG_ CTIWheelEndElectricalFault_20 m32 : 36|2@1+ (1,0) [0|3] "" Vector__XXX
 SG_ CTIWheelEndElectricalFault_13 m19 : 36|2@1+ (1,0) [0|3] "" Vector__XXX
 SG_ CTIWheelEndElectricalFault_12 m18 : 36|2@1+ (1,0) [0|3] "" Vector__XXX
 SG_ CTIWheelEndElectricalFault_11 m17 : 36|2@1+ (1,0) [0|3] "" Vector__XXX
 SG_ CTIWheelEndElectricalFault_10 m16 : 36|2@1+ (1,0) [0|3] "" Vector__XXX
 SG_ CTIWheelEndElectricalFault_01 m1 : 36|2@1+ (1,0) [0|3] "" Vector__XXX
 SG_ CTITireStatus_33 m51 : 34|2@1+ (1,0) [0|3] "" Vector__XXX
 SG_ CTITireStatus_32 m50 : 34|2@1+ (1,0) [0|3] "" Vector__XXX
 SG_ CTITireStatus_31 m49 : 34|2@1+ (1,0) [0|3] "" Vector__XXX
 SG_ CTITireStatus_30 m48 : 34|2@1+ (1,0) [0|3] "" Vector__XXX
 SG_ CTITireStatus_23 m35 : 34|2@1+ (1,0) [0|3] "" Vector__XXX
 SG_ CTITireStatus_22 m34 : 34|2@1+ (1,0) [0|3] "" Vector__XXX
 SG_ CTITireStatus_21 m33 : 34|2@1+ (1,0) [0|3] "" Vector__XXX
 SG_ CTITireStatus_20 m32 : 34|2@1+ (1,0) [0|3] "" Vector__XXX
 SG_ CTITireStatus_13 m19 : 34|2@1+ (1,0) [0|3] "" Vector__XXX
 SG_ CTITireStatus_12 m18 : 34|2@1+ (1,0) [0|3] "" Vector__XXX
 SG_ CTITireStatus_11 m17 : 34|2@1+ (1,0) [0|3] "" Vector__XXX
 SG_ CTITireStatus_10 m16 : 34|2@1+ (1,0) [0|3] "" Vector__XXX
 SG_ CTITireStatus_01 m1 : 34|2@1+ (1,0) [0|3] "" Vector__XXX
 SG_ TireTemp_11 m17 : 16|16@1+ (0.03125,-273) [-273|1735] "�C" Vector__XXX
 SG_ TireTemp_33 m51 : 16|16@1+ (0.03125,-273) [-273|1735] "�C" Vector__XXX
 SG_ TireTemp_32 m50 : 16|16@1+ (0.03125,-273) [-273|1735] "�C" Vector__XXX
 SG_ TireTemp_31 m49 : 16|16@1+ (0.03125,-273) [-273|1735] "�C" Vector__XXX
 SG_ TireTemp_30 m48 : 16|16@1+ (0.03125,-273) [-273|1735] "�C" Vector__XXX
 SG_ TireTemp_23 m35 : 16|16@1+ (0.03125,-273) [-273|1735] "�C" Vector__XXX
 SG_ TireTemp_22 m34 : 16|16@1+ (0.03125,-273) [-273|1735] "�C" Vector__XXX
 SG_ TireTemp_21 m33 : 16|16@1+ (0.03125,-273) [-273|1735] "�C" Vector__XXX
 SG_ TireTemp_20 m32 : 16|16@1+ (0.03125,-273) [-273|1735] "�C" Vector__XXX
 SG_ TireTemp_13 m19 : 16|16@1+ (0.03125,-273) [-273|1735] "�C" Vector__XXX
 SG_ TireTemp_12 m18 : 16|16@1+ (0.03125,-273) [-273|1735] "�C" Vector__XXX
 SG_ TireTemp_10 m16 : 16|16@1+ (0.03125,-273) [-273|1735] "�C" Vector__XXX
 SG_ TireTemp_01 m1 : 16|16@1+ (0.03125,-273) [-273|1735] "�C" Vector__XXX
 SG_ TireTemp_00 m0 : 16|16@1+ (0.03125,-273) [-273|1735] "�C" Vector__XXX
 SG_ TirePressThresholdDetection_33 m51 : 61|3@1+ (1,0) [0|7] "" Vector__XXX
 SG_ TirePressThresholdDetection_32 m50 : 61|3@1+ (1,0) [0|7] "" Vector__XXX
 SG_ TirePressThresholdDetection_31 m49 : 61|3@1+ (1,0) [0|7] "" Vector__XXX
 SG_ TirePressThresholdDetection_30 m48 : 61|3@1+ (1,0) [0|7] "" Vector__XXX
 SG_ TirePressThresholdDetection_23 m35 : 61|3@1+ (1,0) [0|7] "" Vector__XXX
 SG_ TirePressThresholdDetection_22 m34 : 61|3@1+ (1,0) [0|7] "" Vector__XXX
 SG_ TirePressThresholdDetection_21 m33 : 61|3@1+ (1,0) [0|7] "" Vector__XXX
 SG_ TirePressThresholdDetection_20 m32 : 61|3@1+ (1,0) [0|7] "" Vector__XXX
 SG_ TirePressThresholdDetection_00 m0 : 61|3@1+ (1,0) [0|7] "" Vector__XXX
 SG_ TirePress_01 m1 : 8|8@1+ (4,0) [0|1000] "kPa" Vector__XXX
 SG_ TirePress_00 m0 : 8|8@1+ (4,0) [0|1000] "kPa" Vector__XXX
 SG_ CTIWheelSensorStatus_00 m0 : 32|2@1+ (1,0) [0|3] "" Vector__XXX
 SG_ CTIWheelEndElectricalFault_00 m0 : 36|2@1+ (1,0) [0|3] "" Vector__XXX
 SG_ CTITireStatus_00 m0 : 34|2@1+ (1,0) [0|3] "" Vector__XXX
 SG_ TireLocation M : 0|8@1+ (1,0) [0|255] "" Vector__XXX

BO_ 2633939966 TFI: 16 Vector__XXX
 SG_ TripFanOnTimeDueToAManualSwitch : 64|32@1+ (0.05,0) [0|210554060.75] "hr" Vector__XXX
 SG_ TripFanOnTime : 0|32@1+ (0.05,0) [0|210554060.75] "hr" Vector__XXX
 SG_ TripFanOnTimeDueToA_CSystem : 96|32@1+ (0.05,0) [0|210554060.75] "hr" Vector__XXX
 SG_ TripFanOnTimeDueToEngSystem : 32|32@1+ (0.05,0) [0|210554060.75] "hr" Vector__XXX

BO_ 2633939710 TDI: 12 Vector__XXX
 SG_ TripDistanceInTopGear : 64|32@1+ (0.125,0) [0|526385151.9] "km" Vector__XXX
 SG_ TripGearDownDistance : 32|32@1+ (0.125,0) [0|526385151.9] "km" Vector__XXX
 SG_ TripDistanceOnVSL : 0|32@1+ (0.125,0) [0|526385151.9] "km" Vector__XXX

BO_ 2564161278 TDA: 8 Vector__XXX
 SG_ AdjustLocalHourOffset : 56|8@1+ (1,-125) [-125|125] "hr" Vector__XXX
 SG_ AdjustLocalMinuteOffset : 48|8@1+ (1,-125) [-125|125] "mins" Vector__XXX
 SG_ AdjustYear : 40|8@1+ (1,1985) [1985|2235] "years" Vector__XXX
 SG_ AdjustDay : 32|8@1+ (0.25,0) [0|62.5] "days" Vector__XXX
 SG_ AdjustMonth : 24|8@1+ (1,0) [0|250] "months" Vector__XXX
 SG_ AdjustHours : 16|8@1+ (1,0) [0|250] "hr" Vector__XXX
 SG_ AdjustMinutes : 8|8@1+ (1,0) [0|250] "mins" Vector__XXX
 SG_ AdjustSeconds : 0|8@1+ (0.25,0) [0|62.5] "s" Vector__XXX

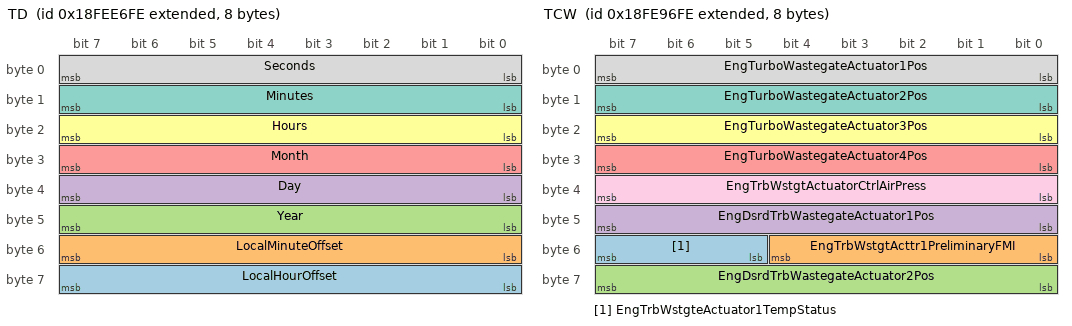
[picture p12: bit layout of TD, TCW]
BO_ 2566842110 TD: 8 Vector__XXX
 SG_ LocalHourOffset : 56|8@1+ (1,-125) [-125|125] "hr" Vector__XXX
 SG_ LocalMinuteOffset : 48|8@1+ (1,-125) [-125|125] "mins" Vector__XXX
 SG_ Year : 40|8@1+ (1,1985) [1985|2235] "years" Vector__XXX
 SG_ Day : 32|8@1+ (0.25,0) [0|62.5] "days" Vector__XXX
 SG_ Month : 24|8@1+ (1,0) [0|250] "months" Vector__XXX
 SG_ Hours : 16|8@1+ (1,0) [0|250] "hr" Vector__XXX
 SG_ Minutes : 8|8@1+ (1,0) [0|250] "mins" Vector__XXX
 SG_ Seconds : 0|8@1+ (0.25,0) [0|62.5] "s" Vector__XXX

BO_ 2566821630 TCW: 8 Vector__XXX
 SG_ EngTrbWstgteActuator1TempStatus : 53|3@1+ (1,0) [0|7] "" Vector__XXX
 SG_ EngTrbWstgtActtr1PreliminaryFMI : 48|5@1+ (1,0) [0|31] "" Vector__XXX
 SG_ EngDsrdTrbWastegateActuator2Pos : 56|8@1+ (0.4,0) [0|100] "%" Vector__XXX
 SG_ EngDsrdTrbWastegateActuator1Pos : 40|8@1+ (0.4,0) [0|100] "%" Vector__XXX
 SG_ EngTurboWastegateActuator4Pos : 24|8@1+ (0.4,0) [0|100] "%" Vector__XXX
 SG_ EngTurboWastegateActuator3Pos : 16|8@1+ (0.4,0) [0|100] "%" Vector__XXX
 SG_ EngTurboWastegateActuator2Pos : 8|8@1+ (0.4,0) [0|100] "%" Vector__XXX
 SG_ EngTurboWastegateActuator1Pos : 0|8@1+ (0.4,0) [0|100] "%" Vector__XXX
 SG_ EngTrbWstgtActuatorCtrlAirPress : 32|8@1+ (4,0) [0|1000] "kPa" Vector__XXX

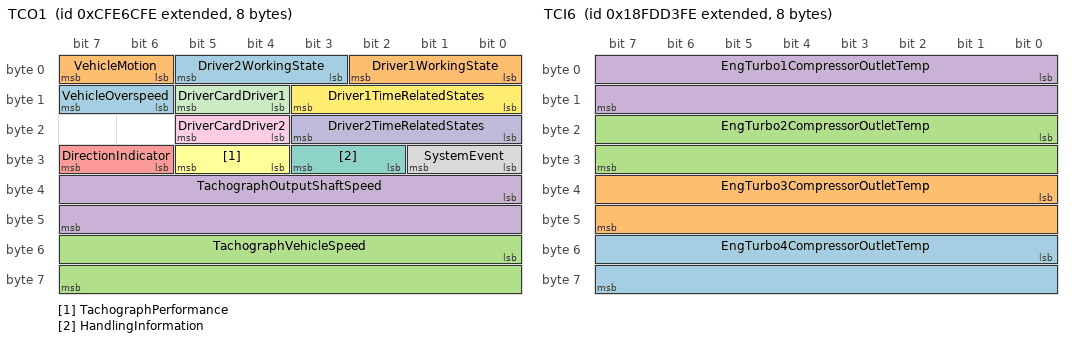
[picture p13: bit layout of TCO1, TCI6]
BO_ 2365484286 TCO1: 8 Vector__XXX
 SG_ VehicleOverspeed : 14|2@1+ (1,0) [0|3] "" Vector__XXX
 SG_ VehicleMotion : 6|2@1+ (1,0) [0|3] "" Vector__XXX
 SG_ TachographVehicleSpeed : 48|16@1+ (0.00390625,0) [0|250.996] "km/h" Vector__XXX
 SG_ TachographOutputShaftSpeed : 32|16@1+ (0.125,0) [0|8031.875] "rpm" Vector__XXX
 SG_ DirectionIndicator : 30|2@1+ (1,0) [0|3] "" Vector__XXX
 SG_ TachographPerformance : 28|2@1+ (1,0) [0|3] "" Vector__XXX
 SG_ HandlingInformation : 26|2@1+ (1,0) [0|3] "" Vector__XXX
 SG_ SystemEvent : 24|2@1+ (1,0) [0|3] "" Vector__XXX
 SG_ DriverCardDriver2 : 20|2@1+ (1,0) [0|3] "" Vector__XXX
 SG_ Driver2TimeRelatedStates : 16|4@1+ (1,0) [0|15] "" Vector__XXX
 SG_ DriverCardDriver1 : 12|2@1+ (1,0) [0|3] "" Vector__XXX
 SG_ Driver1TimeRelatedStates : 8|4@1+ (1,0) [0|15] "" Vector__XXX
 SG_ Driver2WorkingState : 3|3@1+ (1,0) [0|7] "" Vector__XXX
 SG_ Driver1WorkingState : 0|3@1+ (1,0) [0|7] "" Vector__XXX

BO_ 2566771710 TCI6: 8 Vector__XXX
 SG_ EngTurbo4CompressorOutletTemp : 48|16@1+ (0.03125,-273) [-273|1734.96875] "deg C" Vector__XXX
 SG_ EngTurbo3CompressorOutletTemp : 32|16@1+ (0.03125,-273) [-273|1734.96875] "deg C" Vector__XXX
 SG_ EngTurbo2CompressorOutletTemp : 16|16@1+ (0.03125,-273) [-273|1734.96875] "deg C" Vector__XXX
 SG_ EngTurbo1CompressorOutletTemp : 0|16@1+ (0.03125,-273) [-273|1734.96875] "deg C" Vector__XXX

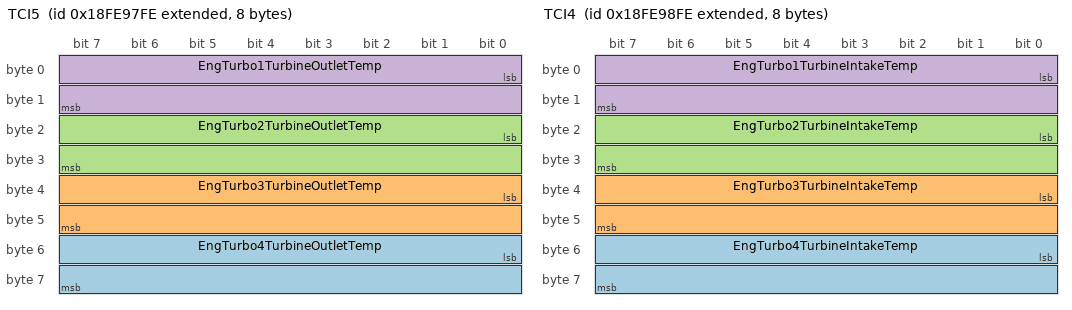
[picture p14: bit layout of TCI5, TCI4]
BO_ 2566821886 TCI5: 8 Vector__XXX
 SG_ EngTurbo4TurbineOutletTemp : 48|16@1+ (0.03125,-273) [-273|1734.96875] "deg C" Vector__XXX
 SG_ EngTurbo3TurbineOutletTemp : 32|16@1+ (0.03125,-273) [-273|1734.96875] "deg C" Vector__XXX
 SG_ EngTurbo2TurbineOutletTemp : 16|16@1+ (0.03125,-273) [-273|1734.96875] "deg C" Vector__XXX
 SG_ EngTurbo1TurbineOutletTemp : 0|16@1+ (0.03125,-273) [-273|1734.96875] "deg C" Vector__XXX

BO_ 2566822142 TCI4: 8 Vector__XXX
 SG_ EngTurbo4TurbineIntakeTemp : 48|16@1+ (0.03125,-273) [-273|1734.96875] "deg C" Vector__XXX
 SG_ EngTurbo3TurbineIntakeTemp : 32|16@1+ (0.03125,-273) [-273|1734.96875] "deg C" Vector__XXX
 SG_ EngTurbo2TurbineIntakeTemp : 16|16@1+ (0.03125,-273) [-273|1734.96875] "deg C" Vector__XXX
 SG_ EngTurbo1TurbineIntakeTemp : 0|16@1+ (0.03125,-273) [-273|1734.96875] "deg C" Vector__XXX

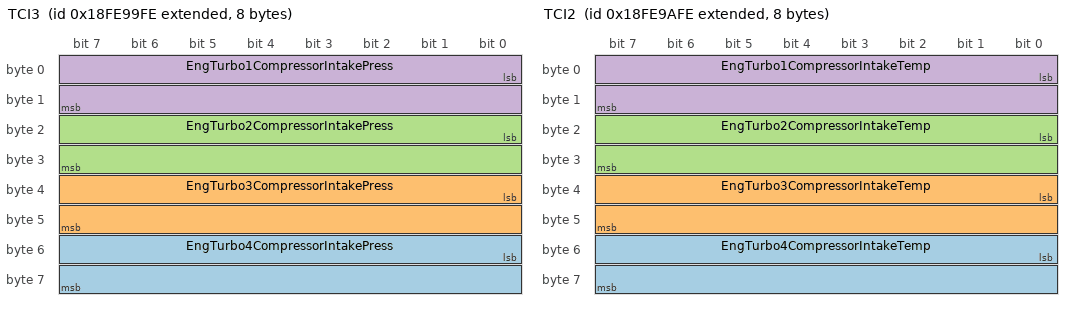
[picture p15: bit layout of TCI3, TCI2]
BO_ 2566822398 TCI3: 8 Vector__XXX
 SG_ EngTurbo4CompressorIntakePress : 48|16@1+ (0.0078125,-250) [-250|251.99] "kPa" Vector__XXX
 SG_ EngTurbo3CompressorIntakePress : 32|16@1+ (0.0078125,-250) [-250|251.99] "kPa" Vector__XXX
 SG_ EngTurbo2CompressorIntakePress : 16|16@1+ (0.0078125,-250) [-250|251.99] "kPa" Vector__XXX
 SG_ EngTurbo1CompressorIntakePress : 0|16@1+ (0.0078125,-250) [-250|251.99] "kPa" Vector__XXX

BO_ 2566822654 TCI2: 8 Vector__XXX
 SG_ EngTurbo4CompressorIntakeTemp : 48|16@1+ (0.03125,-273) [-273|1734.96875] "deg C" Vector__XXX
 SG_ EngTurbo3CompressorIntakeTemp : 32|16@1+ (0.03125,-273) [-273|1734.96875] "deg C" Vector__XXX
 SG_ EngTurbo2CompressorIntakeTemp : 16|16@1+ (0.03125,-273) [-273|1734.96875] "deg C" Vector__XXX
 SG_ EngTurbo1CompressorIntakeTemp : 0|16@1+ (0.03125,-273) [-273|1734.96875] "deg C" Vector__XXX

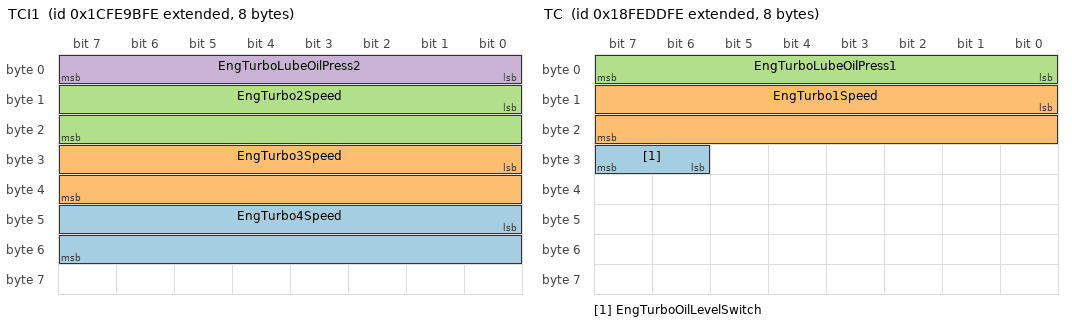
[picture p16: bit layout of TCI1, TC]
BO_ 2633931774 TCI1: 8 Vector__XXX
 SG_ EngTurbo4Speed : 40|16@1+ (4,0) [0|257020] "rpm" Vector__XXX
 SG_ EngTurbo3Speed : 24|16@1+ (4,0) [0|257020] "rpm" Vector__XXX
 SG_ EngTurbo2Speed : 8|16@1+ (4,0) [0|257020] "rpm" Vector__XXX
 SG_ EngTurboLubeOilPress2 : 0|8@1+ (4,0) [0|1000] "kPa" Vector__XXX

BO_ 2566802430 TCFG2: 8 Vector__XXX
 SG_ TransTorqueLimit : 0|16@1+ (1,0) [0|64255] "Nm" Vector__XXX

BO_ 2566841086 TCFG: 8 Vector__XXX
 SG_ TransGearRatio : 16|16@1+ (0.001,0) [0|64.255] "" Vector__XXX
 SG_ NumberOfForwardGearRatios : 8|8@1+ (1,0) [0|250] "" Vector__XXX
 SG_ NumberOfReverseGearRatios : 0|8@1+ (1,0) [0|250] "" Vector__XXX

BO_ 2348941054 TC1: 8 Vector__XXX
 SG_ TrnsShftSlctorDisplayModeSwitch : 54|2@1+ (1,0) [0|3] "" Vector__XXX
 SG_ TransMode4 : 46|2@1+ (1,0) [0|3] "" Vector__XXX
 SG_ TransMode3 : 44|2@1+ (1,0) [0|3] "" Vector__XXX
 SG_ TransMode2 : 42|2@1+ (1,0) [0|3] "" Vector__XXX
 SG_ TransMode1 : 40|2@1+ (1,0) [0|3] "" Vector__XXX
 SG_ DisengageDiffLockRqCentralRear : 36|2@1+ (1,0) [0|3] "" Vector__XXX
 SG_ DisengageDiffLockRqCentralFront : 34|2@1+ (1,0) [0|3] "" Vector__XXX
 SG_ DisengageDiffLockRqCentral : 32|2@1+ (1,0) [0|3] "" Vector__XXX
 SG_ DisengageDiffLockRqRearAxle2 : 30|2@1+ (1,0) [0|3] "" Vector__XXX
 SG_ DisengageDiffLockRqRearAxle1 : 28|2@1+ (1,0) [0|3] "" Vector__XXX
 SG_ DisengageDiffLockRqFrontAxle2 : 26|2@1+ (1,0) [0|3] "" Vector__XXX
 SG_ DisengageDiffLockRqFrontAxle1 : 24|2@1+ (1,0) [0|3] "" Vector__XXX
 SG_ TransRqedGear : 16|8@1+ (1,-125) [-125|125] "" Vector__XXX
 SG_ RqedPercentClutchSlip : 8|8@1+ (0.4,0) [0|100] "%" Vector__XXX
 SG_ DisengageDrivelineRq : 4|2@1+ (1,0) [0|3] "" Vector__XXX
 SG_ TransGearShiftInhibitRq : 0|2@1+ (1,0) [0|3] "" Vector__XXX
 SG_ TrnsTrqConverterLockupDisableRq : 2|2@1+ (1,0) [0|3] "" Vector__XXX
 SG_ TransRqedLaunchGear : 50|4@1+ (1,0) [0|15] "" Vector__XXX
 SG_ TransReverseGearShiftInhibitRq : 6|2@1+ (1,0) [0|3] "" Vector__XXX
 SG_ TransMode8 : 62|2@1+ (1,0) [0|3] "" Vector__XXX
 SG_ TransMode7 : 60|2@1+ (1,0) [0|3] "" Vector__XXX
 SG_ TransMode6 : 58|2@1+ (1,0) [0|3] "" Vector__XXX
 SG_ TransMode5 : 56|2@1+ (1,0) [0|3] "" Vector__XXX

BO_ 2566839806 TC: 8 Vector__XXX
 SG_ EngTurboOilLevelSwitch : 30|2@1+ (1,0) [0|3] "" Vector__XXX
 SG_ EngTurbo1Speed : 8|16@1+ (4,0) [0|257020] "rpm" Vector__XXX
 SG_ EngTurboLubeOilPress1 : 0|8@1+ (4,0) [0|1000] "kPa" Vector__XXX

BO_ 2633911806 TAVG: 8 Vector__XXX
 SG_ EngTotalAverageFuelEconomy : 16|16@1+ (0.001953125,0) [0|125.5] "km/L" Vector__XXX
 SG_ EngTotalAverageFuelRate : 0|16@1+ (0.05,0) [0|3212.75] "L/h" Vector__XXX

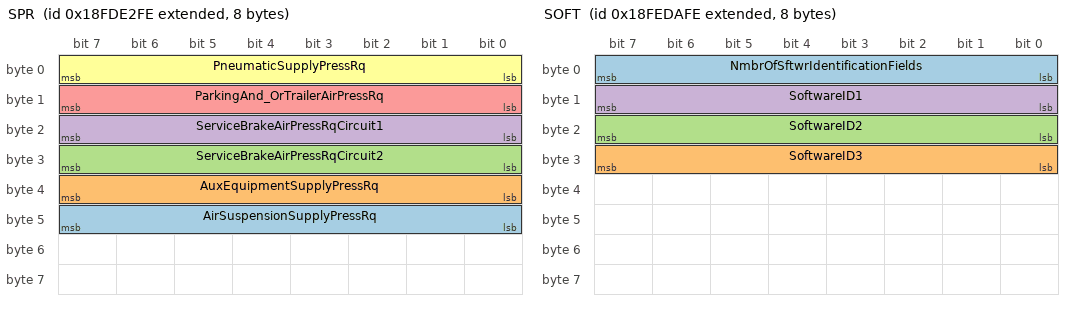
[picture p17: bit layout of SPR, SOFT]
BO_ 2566775550 SPR: 8 Vector__XXX
 SG_ AirSuspensionSupplyPressRq : 40|8@1+ (8,0) [0|2000] "kPa" Vector__XXX
 SG_ AuxEquipmentSupplyPressRq : 32|8@1+ (8,0) [0|2000] "kPa" Vector__XXX
 SG_ ServiceBrakeAirPressRqCircuit2 : 24|8@1+ (8,0) [0|2000] "kPa" Vector__XXX
 SG_ ServiceBrakeAirPressRqCircuit1 : 16|8@1+ (8,0) [0|2000] "kPa" Vector__XXX
 SG_ ParkingAnd_OrTrailerAirPressRq : 8|8@1+ (8,0) [0|2000] "kPa" Vector__XXX
 SG_ PneumaticSupplyPressRq : 0|8@1+ (8,0) [0|2000] "kPa" Vector__XXX

BO_ 2566819838 SP2: 8 Vector__XXX
 SG_ EngExtlShutdownAirSupplyPress : 0|16@1+ (0.5,0) [0|32127.5] "kPa" Vector__XXX

BO_ 2566839038 SOFT: 8 Vector__XXX
 SG_ NmbrOfSftwrIdentificationFields : 0|8@1+ (1,0) [0|250] "steps" Vector__XXX
 SG_ SoftwareID3 : 24|8@1+ (1,0) [0|255] "" Vector__XXX
 SG_ SoftwareID2 : 16|8@1+ (1,0) [0|255] "" Vector__XXX
 SG_ SoftwareID1 : 8|8@1+ (1,0) [0|255] "" Vector__XXX

BO_ 2566841598 SHUTDN: 8 Vector__XXX
 SG_ EngOverspeedTest : 54|2@1+ (1,0) [0|3] "" Vector__XXX
 SG_ EngAirShutoffCmdStatus : 52|2@1+ (1,0) [0|3] "" Vector__XXX
 SG_ EngAlarmOutputCmdStatus : 50|2@1+ (1,0) [0|3] "" Vector__XXX
 SG_ EngAlarmAcknowledge : 48|2@1+ (1,0) [0|3] "" Vector__XXX
 SG_ EngProtectionSystemConfig : 46|2@1+ (1,0) [0|3] "" Vector__XXX
 SG_ EngProtectionSystemTimerState : 38|2@1+ (1,0) [0|3] "" Vector__XXX
 SG_ EngPrtectionSystemTimerOverride : 36|2@1+ (1,0) [0|3] "" Vector__XXX
 SG_ EngPrtctnSystmApprchingShutdown : 34|2@1+ (1,0) [0|3] "" Vector__XXX
 SG_ EngWaitToStartLamp : 24|2@1+ (1,0) [0|3] "" Vector__XXX
 SG_ RefrigerantHighPressSwitch : 20|2@1+ (1,0) [0|3] "" Vector__XXX
 SG_ RefrigerantLowPressSwitch : 18|2@1+ (1,0) [0|3] "" Vector__XXX
 SG_ A_CHighPressFanSwitch : 16|2@1+ (1,0) [0|3] "" Vector__XXX
 SG_ EngIdleShutdownTimerFunction : 14|2@1+ (1,0) [0|3] "" Vector__XXX
 SG_ EngIdleShutdownTimerState : 6|2@1+ (1,0) [0|3] "" Vector__XXX
 SG_ EngIdleShutdownTimerOverride : 4|2@1+ (1,0) [0|3] "" Vector__XXX
 SG_ EngIdleShutdownDriverAlertMode : 2|2@1+ (1,0) [0|3] "" Vector__XXX
 SG_ PTOShutdownHasShutdownEng : 58|2@1+ (1,0) [0|3] "" Vector__XXX
 SG_ EngPrtctnSystmHasShutdownEngine : 32|2@1+ (1,0) [0|3] "" Vector__XXX
 SG_ EngIdlShutdownHasShutdownEngine : 0|2@1+ (1,0) [0|3] "" Vector__XXX
 SG_ EngAirShutoffStatus : 56|2@1+ (1,0) [0|3] "" Vector__XXX

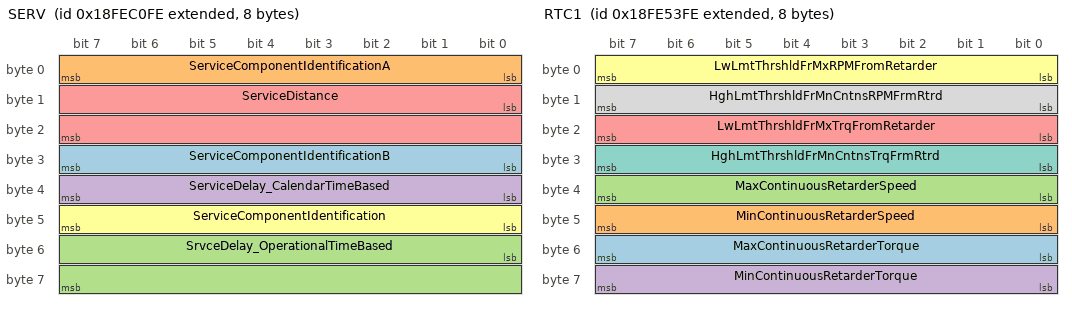
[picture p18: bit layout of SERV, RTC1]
BO_ 2566832382 SERV: 8 Vector__XXX
 SG_ ServiceComponentIdentificationB : 24|8@1+ (1,0) [0|250] "ID" Vector__XXX
 SG_ ServiceComponentIdentificationA : 0|8@1+ (1,0) [0|250] "ID" Vector__XXX
 SG_ SrvceDelay_OperationalTimeBased : 48|16@1+ (1,-32127) [-32127|32128] "hr" Vector__XXX
 SG_ ServiceDelay_CalendarTimeBased : 32|8@1+ (1,-125) [-125|125] "weeks" Vector__XXX
 SG_ ServiceDistance : 8|16@1+ (5,-160635) [-160635|160640] "km" Vector__XXX
 SG_ ServiceComponentIdentification : 40|8@1+ (1,0) [0|250] "ID" Vector__XXX

BO_ 2633928446 S2: 8 Vector__XXX
 SG_ TimeSinceLastService : 8|16@1+ (1,-32127) [-32127|32128] "hr" Vector__XXX
 SG_ ServiceComponentIdentification : 0|8@1+ (1,0) [0|250] "ID" Vector__XXX

BO_ 2566804478 RTC1: 8 Vector__XXX
 SG_ MaxContinuousRetarderTorque : 48|8@1+ (1,-125) [-125|125] "%" Vector__XXX
 SG_ MinContinuousRetarderSpeed : 40|8@1+ (32,0) [0|8000] "rpm" Vector__XXX
 SG_ MaxContinuousRetarderSpeed : 32|8@1+ (32,0) [0|8000] "rpm" Vector__XXX
 SG_ MinContinuousRetarderTorque : 56|8@1+ (1,-125) [-125|125] "%" Vector__XXX
 SG_ LwLmtThrshldFrMxTrqFromRetarder : 16|8@1+ (1,-125) [-125|125] "%" Vector__XXX
 SG_ LwLmtThrshldFrMxRPMFromRetarder : 0|8@1+ (32,0) [0|8000] "rpm" Vector__XXX
 SG_ HghLmtThrshldFrMnCntnsTrqFrmRtrd : 24|8@1+ (1,-125) [-125|125] "%" Vector__XXX
 SG_ HghLmtThrshldFrMnCntnsRPMFrmRtrd : 8|8@1+ (32,0) [0|8000] "rpm" Vector__XXX

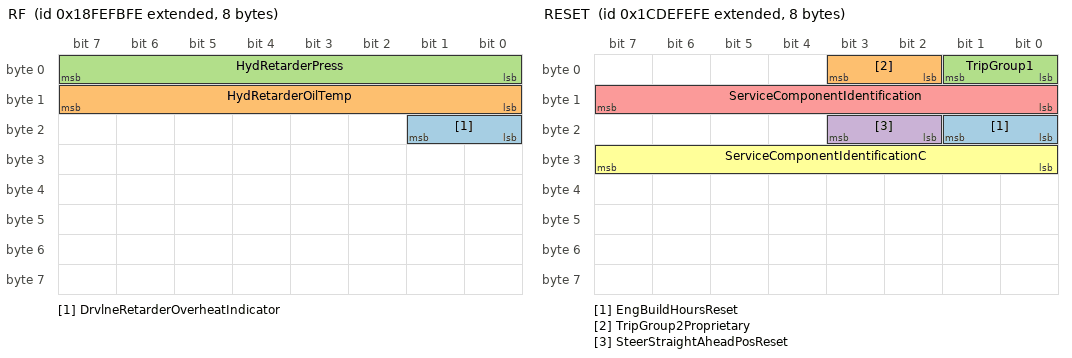
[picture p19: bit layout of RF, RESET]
BO_ 2566847486 RF: 8 Vector__XXX
 SG_ DrvlneRetarderOverheatIndicator : 16|2@1+ (1,0) [0|3] "" Vector__XXX
 SG_ HydRetarderOilTemp : 8|8@1+ (1,-40) [-40|210] "deg C" Vector__XXX
 SG_ HydRetarderPress : 0|8@1+ (16,0) [0|4000] "kPa" Vector__XXX

BO_ 2631859966 RESET: 8 Vector__XXX
 SG_ EngBuildHoursReset : 16|2@1+ (1,0) [0|3] "" Vector__XXX
 SG_ TripGroup2Proprietary : 2|2@1+ (1,0) [0|3] "" Vector__XXX
 SG_ TripGroup1 : 0|2@1+ (1,0) [0|3] "" Vector__XXX
 SG_ SteerStraightAheadPosReset : 18|2@1+ (1,0) [0|3] "" Vector__XXX
 SG_ ServiceComponentIdentification : 8|8@1+ (1,0) [0|250] "ID" Vector__XXX
 SG_ ServiceComponentIdentificationC : 24|8@1+ (1,0) [0|250] "ID" Vector__XXX

CM_ BO_ 2566808574 "ISO 11992: Towing vehicle message, general purpose message #1/5";
CM_ SG_ 2566808574 ReferenceEngineTorque "The 100 % reference value for all defined indicated engine torque parameters.";
CM_ SG_ 2566808574 FuelLevelWarning "This signal indicates the decrease of the fuel level to a certain minimum.";
CM_ SG_ 2566808574 EngineOilPressureWarning "Signal which indicates that the engine oil pressure has reached its warning level.";
CM_ SG_ 2566808574 EngineCoolantTempWarning "Signal which indicates that the engine coolant temperature has reached its warning level.";
CM_ SG_ 2566808574 EngineOilPressure "Gauge pressure of the oil in the engine lubrication system as provided by the oil pump.";
CM_ SG_ 2566808574 EngineOilTemperature "Temperature of the engine lubricant.";
CM_ BO_ 2566809086 "ISO 11992: Towing vehicle message, general purpose message #1/6";
CM_ SG_ 2566809086 AmbientAirTemperature "Temperature of air surrounding vehicle.";
CM_ BO_ 2564947710 "ISO 11992: Towed vehicle message, general purpose message #2/1

GPM 21 replaces GFM 21 in ISO 11992:1998 part 3";
CM_ SG_ 2564947710 VehicleType "Information to identify a dolly axle within the road train.";
CM_ BO_ 2566834430 "ISO 11992: Towed vehicle message, general purpose message #2/2

GPM22 replaces GFM 24 in ISO 11992:1998 part 3";
CM_ SG_ 2566834430 BodyPressure "The actual pressure in a body on the towed vehicle.";
CM_ SG_ 2566834430 BodyFluidLevel "The actual fluid level in a body on the towed vehicle.";
CM_ SG_ 2566834430 ThermalBodyTemperature "The actual temperature in a thermal body on the towed vehicle.";
CM_ SG_ 2566834430 RearObstacleDistance "The actual distance between the back of the towed vehicle and any obstacle.";
CM_ SG_ 2566834430 AntiTheftDeviceStatus "Signal which indicates that the anti-theft device is switched on or off.";
CM_ SG_ 2566834430 ODDStatus "Signal which indicates that an obstacle detection device (ODD) is active/inactive.";
CM_ BO_ 2365481214 "ISO 11992: Towed vehicle message, general purpose message #2/3";
CM_ SG_ 2365481214 ReqEngineSpeedUpperLim "The requested engine speed which is not to be exceeded.";
CM_ SG_ 2365481214 ReqEngineSpeedLowerLim "The requested minimum engine speed which the engine is to allow.";
CM_ SG_ 2365481214 ReqEngineTorqueLimit "The requested engine torque that the engine is not allowed to exceed, indicated as a ratio of the reference engine torque.";
CM_ SG_ 2365481214 ReqEngineSpeedLimit "The requested vehicle speed which the vehicle is not allowed to exceed.";
CM_ SG_ 2365481214 ReqEngineSpeed "This is the engine speed which the engine is expected to operate at.";
CM_ BO_ 2566808318 "ISO 11992: Towed vehicle message, general purpose message #2/4";
CM_ SG_ 2566808318 SecEngineMtdPTOSwitch "Signal which indicates the state of the second engine mounted power take off switch.";
CM_ SG_ 2566808318 SecClutchDpdtPTOSwitch "Signal which indicates the state of the second clutch dependent power take off switch.";
CM_ SG_ 2566808318 FirstClutchDpdtPTOSwitch "Signal which indicates the state of the first clutch dependent power take off switch.";
CM_ SG_ 2566808318 OperatingPanelActive "Signal which indicates that the operating panel is active.";
CM_ SG_ 2566808318 RefusePackerStepSwitch "Signal which indicates the state of the refuse packer step switch.";
CM_ SG_ 2566808318 EngineStopSwitch "Signal which indicates the state of the engine stop switch.";
CM_ SG_ 2566808318 EngineStartSwitch "Signal which indicates the state of the engine start switch.";
CM_ SG_ 2566808318 StarterLockoutSwitch "Signal which indicates the state of the starter lockout switch.";
CM_ SG_ 2566808318 RqstedPercentClutchSlip "Command signal to influence the clutch.";
CM_ SG_ 2566808318 FirstEngineMtdPTOSwitch "Signal which indicates the state of the first engine mounted power take off switch.";
CM_ SG_ 2566808318 ClutchIndpdtPTOSwitch "Signal which indicates the state of the clutch independent power take off switch.";
CM_ BO_ 2566808830 "ISO 11992: Towed vehicle message, general purpose message #2/5";
CM_ SG_ 2566808830 TrailerLeftSideMarkerLight "This signal indicates the state of the trailer left-hand side marker light(s).";
CM_ SG_ 2566808830 TrailerLeftReversingLight "This signal indicates the state of the trailer left-hand reversing light(s).";
CM_ SG_ 2566808830 TrailerLeftRearWidIndLight "This signal indicates the state of the trailer left-hand rear width indicator light(s).";
CM_ SG_ 2566808830 TrailerLeftRearRegPltLight "This signal indicates the state of the trailer left-hand rear registration-plate light(s).";
CM_ SG_ 2566808830 TrailerLeftRearLight "This signal indicates the state of the trailer left-hand rear light(s).";
CM_ SG_ 2566808830 TrailerLeftRearFogLight "This signal indicates the state of the trailer left-hand rear fog light(s).";
CM_ SG_ 2566808830 TrailerLeftDirIndLight "This signal indicates the state of the trailer left-hand direction indicator light(s).";
CM_ SG_ 2566808830 TrailerLeftCrnMarkerLight "This signal indicates the state of the trailer left-hand corner marker light(s).";
CM_ SG_ 2566808830 TrailerInteriorLight "This signal indicates the state of the trailer interior light(s).";
CM_ SG_ 2566808830 TrailerWorkLamp "This signal indicates the state of the trailer work lamp(s).";
CM_ SG_ 2566808830 TrailerRotatingIdentLight "This signal indicates the state of the trailer rotating identification light(s).";
CM_ SG_ 2566808830 TrailerRightStopLight "This signal indicates the state of the trailer right-hand stop light(s).";
CM_ SG_ 2566808830 TrailerRightSideMrkLight "This signal indicates the state of the trailer right-hand side marker light(s).";
CM_ SG_ 2566808830 TrailerRightReversingLight "This signal indicates the state of the trailer right-hand reversing light(s).";
CM_ SG_ 2566808830 TrailRightRearWidIndLight "This signal indicates the state of the trailer right-hand rear width indicator light(s).";
CM_ SG_ 2566808830 TrailerRightRearRegPltLight "This signal indicates the state of the trailer right-hand rear registration-plate light(s).";
CM_ SG_ 2566808830 TrailerRightRearLight "This signal indicates the state of the trailer right-hand rear light(s).";
CM_ SG_ 2566808830 TrailerRightRearFogLight "This signal indicates the state of the trailer right-hand rear fog light(s).";
CM_ SG_ 2566808830 TrailerRightDirIndLight "This signal indicates the state of the trailer right-hand direction indicator light(s).";
CM_ SG_ 2566808830 TrailerRightCrnMarkerLight "This signal indicates the state of the trailer right-hand corner marker light(s).";
CM_ SG_ 2566808830 TrailerRearWarningLight "This signal indicates the state of the trailer rear warning light(s).";
CM_ SG_ 2566808830 TrailerLeftStopLight "This signal indicates the state of the trailer left-hand stop light(s).";
CM_ BO_ 2564554494 "Reserved for ISO 15765";
CM_ SG_ 2564554494 ProtocolCtrlInformation "Part of Network Protocol Control Information (N_PCI) of a ISO 15765 message.";
CM_ BO_ 2564488958 "Reserved for ISO 15765";
CM_ SG_ 2564488958 ProtocolCtrlInformation "Part of Network Protocol Control Information (N_PCI) of a ISO 15765 message.";
CM_ BO_ 2565734142 "Used to access network interconnection ECU parametrics and database";
CM_ SG_ 2565734142 FilterMode "Filter mode for Network PG";
CM_ SG_ 2565734142 ToPort "Destination port for network PG";
CM_ SG_ 2565734142 FromPort "Source port for Network PG";
CM_ BO_ 2565144318 "ISO 11992: Towing vehicle message, running gear equipment #1/1

RGE11 replaces GFM 12 in ISO 11992:1998 part 3";
CM_ SG_ 2565144318 ParkingAndTrailerAirPress "The pneumatic pressure in the circuit or reservoir for the parking brake and the trailer supply.";
CM_ SG_ 2565144318 DrivenAxleLoad "Actual static vertical load on driven axle of the commercial vehicle. In case of more than one driven axle the value of the axle with the highest vertical load is transmitted.";
CM_ SG_ 2565144318 AuxEquipSupplyPressure "The pneumatic pressure in the auxiliary circuit.";
CM_ SG_ 2565144318 StopLevelChangeReq "Command signal to stop immediately any change of the actual body height level.";
CM_ SG_ 2565144318 RampLevelStorageReq "Command signal to store the actual body height level as new programmed and memorised ramp levels 1 or 2 in the ECU";
CM_ SG_ 2565144318 LevelControlReq "Command signal to enable or disable the automatic level control.";
CM_ SG_ 2565144318 RampLevelReq "Command signal to control the body height to a level programmed and memorised in the ECU.";
CM_ SG_ 2565144318 SteeringAxleLockingReq "Command signal to lock the steering axle.";
CM_ SG_ 2565144318 LiftAxle2PositionReq "Command signal to control the lift axle position / tag axle load condition.";
CM_ SG_ 2565144318 LiftAxle1PositionReq "Command signal to control the lift axle position / tag axle load condition.";
CM_ SG_ 2565144318 TractionHelpReq "Command signal to control the lift axle position / tag axle load condition to transfer more load on the driven axle of the commercial vehicle.";
CM_ SG_ 2565144318 LevelChangeReqRearAxle "Command signal to control the body height [up (lifting)/down (lowering)] for the rear axle.";
CM_ SG_ 2565144318 LevelChangeReqFrontAxle "Command signal to control the body height [up (lifting)/down (lowering)] for the front axle.";
CM_ SG_ 2565144318 RideHeightRequest "Command signal to activate a normal ride body height. The normal levels 1 and 2 are trailer specific body heights.";
CM_ BO_ 2565209854 "ISO 11992: Towed vehicle message, running gear equipment #2/1

RGE21 replaces GFM 22 in ISO 11992:1998 part 3";
CM_ SG_ 2565209854 LevelControl "Signal which indicates that the automatic level control is enabled or disabled.";
CM_ SG_ 2565209854 NominalVehBodyLevelRearAxle "Actual nominal vehicle body height.";
CM_ SG_ 2565209854 NominalVehBodyLevelFrontAxle "Actual nominal vehicle body height.";
CM_ SG_ 2565209854 RampLevel "Signal which indicates the level of the body height as an anser to 'ramp level request'.";
CM_ SG_ 2565209854 NormalLevel "Signal which indicates the normal levels of the vehicle independently of a specific request.";
CM_ SG_ 2565209854 StopLevelChangeAcknowledge "Signal which indicates the stop of any level change due to a 'stop request'.";
CM_ SG_ 2565209854 LevelChangeRearAxle "Signal which indicates the level change of the body height at the rear axle due to any external requests.";
CM_ SG_ 2565209854 LevelChangeFrontAxle "Signal which indicates the level change of the body height at the front axle due to any external requests.";
CM_ SG_ 2565209854 RampLevelStorage "Signal which indicates the storage of a new ramp level in the ECU.";
CM_ SG_ 2565209854 SteeringAxleLocking "Signal which indicates the actual steering axle locking status.";
CM_ SG_ 2565209854 LiftAxle2Pos "Signal which indicates the position / load condition of lift axle / tag axle #2.";
CM_ SG_ 2565209854 LiftAxle1Pos "Signal which indicates the position / load condition of lift axle / tag axle #1.";
CM_ SG_ 2565209854 RampLevelPosition "Signal which indicates the ramp level positions of the vehicle independently of a specific request.";
CM_ SG_ 2565209854 TractionHelp "Signal which indicates that a load transfer is active.";
CM_ SG_ 2565209854 LevelCtrlSysRideHeightLevel "Signal which indicates the body height position of the vehicle as an answer to 'ride height request'.";
CM_ BO_ 2566806782 "ISO 11992: Towed vehicle message, running gear equipment #2/2";
CM_ SG_ 2566806782 RelVehBodyLevelRearAxle "Actual relative vehicle body height.";
CM_ SG_ 2566806782 RelVehBodyLevelFrontAxle "Actual relative vehicle body height.";
CM_ BO_ 2566807294 "ISO 11992: Towed vehicle message, running gear equipment #2/3";
CM_ SG_ 2566807294 TyrePressThresholdDetect "Signal indicating the pressure level of the tyre.";
CM_ SG_ 2566807294 TyreModulePowerSupply "Signal indicating the power supply of the tyre module is sufficient to achieve the specified performance of the module.";
CM_ SG_ 2566807294 TyreTemperature "The temperature measured by the tyre module.";
CM_ SG_ 2566807294 AirLeakageDetection "The pressure loss of a tyre.";
CM_ SG_ 2566807294 TyreWheelIdentification2 "First part of the identification number of the tyre or whee (number of axles).";
CM_ SG_ 2566807294 TyreWheelIdentification1 "First part of the identification number of the tyre or whee (position on each axle).";
CM_ BO_ 2566764798 "Diagnostic readiness 3";
CM_ BO_ 2564095742 "Data security";
CM_ BO_ 2349137662 "External Brake Request";
CM_ SG_ 2349137662 XBRMessageChecksum "The XBR message checksum is used to verify the signal path from the demanding device to the brake controller on";
CM_ SG_ 2349137662 XBRMessageCounter "The XBR message counter is to verify the signal path from the demanding device to the brake controller on electronic";
CM_ SG_ 2349137662 XBRCtrlMode "The XBR Control Mode is used as an input to the brake system and defines how the external acceleration demand has to";
CM_ SG_ 2349137662 XBRPriority "The XBR Priority is used as an input to the brake system to manage the priority of overlapping external and internal requests.";
CM_ SG_ 2349137662 XBREBIMode "The XBR EBI (Endurance Brake Integration) Mode is used as an input for the brake system to prescribe the use of";
CM_ SG_ 2349137662 ExtlAccelerationDemand "Parameter provided to the brake system from external sources.";
CM_ SG_ 2349137662 XBRUrgency "The idea of the urgency value is to adjust the endurance brake integration behavior in the EBS system according to the";
CM_ BO_ 2566848510 "Water in Fuel Indicator";
CM_ SG_ 2566848510 WaterInFuelIndicator "Signal which indicates the presence of water in the fuel.";
CM_ BO_ 2566843134 "Vehicle Weight";
CM_ SG_ 2566843134 AxleLocation "To identify to which of several similar devices (such as tires or fuel tanks) the information applies.";
CM_ SG_ 2566843134 CargoWeight_30 "The mass of freight carried.";
CM_ SG_ 2566843134 CargoWeight_20 "The mass of freight carried.";
CM_ SG_ 2566843134 CargoWeight_10 "The mass of freight carried.";
CM_ SG_ 2566843134 CargoWeight_00 "The mass of freight carried.";
CM_ SG_ 2566843134 TrailerWeight_30 "Total mass of freight-carrying vehicle designed to be pulled by truck, including the weight of the contents.";
CM_ SG_ 2566843134 TrailerWeight_20 "Total mass of freight-carrying vehicle designed to be pulled by truck, including the weight of the contents.";
CM_ SG_ 2566843134 TrailerWeight_10 "Total mass of freight-carrying vehicle designed to be pulled by truck, including the weight of the contents.";
CM_ SG_ 2566843134 TrailerWeight_00 "Total mass of freight-carrying vehicle designed to be pulled by truck, including the weight of the contents.";
CM_ SG_ 2566843134 AxleWeight_30 "Total mass imposed by the tires on the road surface at the specified axle.";
CM_ SG_ 2566843134 AxleWeight_20 "Total mass imposed by the tires on the road surface at the specified axle.";
CM_ SG_ 2566843134 AxleWeight_10 "Total mass imposed by the tires on the road surface at the specified axle.";
CM_ SG_ 2566843134 AxleWeight_00 "Total mass imposed by the tires on the road surface at the specified axle.";
CM_ BO_ 2566804222 "Vehicle Electrical Power #3";
CM_ SG_ 2566804222 NetBatteryCurrentHiRes "Net flow of electrical current into/out-of the battery or batteries.";
CM_ SG_ 2566804222 AltCurrentHiRes "This parameter indicates the amount of electrical current output from the alternator of the main vehicle.";
CM_ BO_ 2633928190 "Vehicle Electrical Power 2";
CM_ SG_ 2633928190 ECUPowerOutputSupplyVoltage3 "The third power output from an ECM.";
CM_ SG_ 2633928190 ECUPowerOutputSupplyVoltage2 "The second power output from an ECM.";
CM_ SG_ 2633928190 ECUPowerOutputSupplyVoltage1 "The first power output from an ECM";
CM_ SG_ 2633928190 BatteryPotential_PowerInput2 "This parameter measures the second source of battery potential as measured at the input of the ECM/actuator etc.";
CM_ BO_ 2566845438 "Vehicle Position";
CM_ SG_ 2566845438 Longitude "Longitude position of the vehicle.";
CM_ SG_ 2566845438 Latitude "Latitude position of the vehicle.";
CM_ BO_ 2566843646 "Vehicle Identification";
CM_ SG_ 2566843646 VehicleIdentificationNumber "Vehicle Identification Number";
CM_ BO_ 2566842366 "Vehicle Hours";
CM_ SG_ 2566842366 TotalPowerTakeoffHours "Accumulated time of operation of power takeoff device.";
CM_ SG_ 2566842366 TotalVehicleHours "Accumulated time of operation of vehicle.";
CM_ BO_ 2566809854 "Vehicle Fluids";
CM_ SG_ 2566809854 WinchOilPressSwitch "State of switch used to determine if Winch Oil Pressure is above desired minimum";
CM_ SG_ 2566809854 HydOilLevel "This parameter indicates the level of the hydraulic fluid in tank as a ratio of current volume to total tank volume.";
CM_ SG_ 2566809854 HydOilFilterRestrictionSwitch "This switch indicates whether hydraulic oil filter is clogged.";
CM_ SG_ 2566809854 HydTemp "Temperature of hydraulic fluid.";
CM_ BO_ 2566842622 "Vehicle Direction/Speed";
CM_ SG_ 2566842622 Altitude "Altitude of the vehicle referenced to sea level at standard atmospheric pressure and temperature.";
CM_ SG_ 2566842622 Pitch "Pitch of the vehicle as calculated by the navigation device(s).";
CM_ SG_ 2566842622 NavigationBasedVehicleSpeed "Speed of the vehicle as calculated from a device such as a Global Positioning System (GPS).";
CM_ SG_ 2566842622 CompassBearing "Present compass bearing of vehicle.";
CM_ BO_ 2566832638 "High Resolution Vehicle Distance";
CM_ SG_ 2566832638 HighResolutionTripDistance "Distance traveled during all or part of a journey.";
CM_ SG_ 2566832638 HghRslutionTotalVehicleDistance "Accumulated distance traveled by the vehicle during its operation.";
CM_ BO_ 2565868030 "Vehicle Dynamic Stability Control 2";
CM_ SG_ 2565868030 SteerWheelAngle "The main operator`s steering wheel angle (on the steering column, not the actual wheel angle).";
CM_ SG_ 2565868030 LongitudinalAcceleration "Indicates the longitudinal acceleration of the vehicle.";
CM_ SG_ 2565868030 LateralAcceleration "Indicates a lateral acceleration of the vehicle.";
CM_ SG_ 2565868030 YawRate "Indicates the rotation about the vertical axis.";
CM_ SG_ 2565868030 SteerWheelAngleSensorType "Indicates whether the steering wheel angle sensor is capable of absolute measuring of the number of steering wheel";
CM_ SG_ 2565868030 SteerWheelTurnCounter "Indicates number of steering wheel turns, absolute position or relative position at ignition on.";
CM_ BO_ 2566803454 "Vehicle Dynamic Stability Control 1";
CM_ SG_ 2566803454 YCBrakeCtrlActive "State signal which indicates that Yaw Control (YC) has activated brake control.";
CM_ SG_ 2566803454 YCEngCtrlActive "State Signal which indicates that the Yaw Control (YC) has commanded engine control to be active.";
CM_ SG_ 2566803454 ROPBrakeCtrlActive "State signal which indicates that Roll over Prevention (ROP) has activated brake control.";
CM_ SG_ 2566803454 ROPEngCtrlActive "State Signal which indicates that the Roll Over Prevention (ROP) has commanded engine control to be active.";
CM_ SG_ 2566803454 VDCBrakeLightRq "Indicates whether VDC requests to turn the vehicle brake lights on";
CM_ SG_ 2566803454 VDCFullyOperational "Signal that indicates whether VDC is fully operational or whether its functionality is reduced by a permanent or temporary";
CM_ SG_ 2566803454 VDCInformationSignal "This parameter commands the VDC information signal, for example a dash lamp.";
CM_ BO_ 2566840574 "Vehicle Distance";
CM_ SG_ 2566840574 TotalVehicleDistance "Accumulated distance traveled by vehicle during its operation.";
CM_ SG_ 2566840574 TripDistance "Distance traveled during all or part of a journey.";
CM_ BO_ 2633938686 "Trip Vehicle Speed/Cruise Distance Information";
CM_ SG_ 2633938686 TripCruiseDistance "Total distance that the engine has operated in the cruise hold state, excluding time in accelerator override, since the last";
CM_ SG_ 2633938686 TripMaxVehicleSpeed "Maximum vehicle speed achieved while the engine speed is greater than zero and the accelerator pedal position (APS) is";
CM_ BO_ 2633937150 "Trip Time Information 2";
CM_ SG_ 2633937150 TripAirCompressorOnTime "Total time that the air compressor is on and compressing air since the last trip reset.";
CM_ SG_ 2633937150 TripIdleTime "Total time accumulated while the engine speed is greater than zero, both the PTO and remote PTO governors are";
CM_ SG_ 2633937150 TripEngRunningTime "Total time accumulated while the engine speed is greater than zero since the last trip reset.";
CM_ SG_ 2633937150 TripCruiseTime "Total time accumulated while the engine is in the cruise hold state, excluding time in accelerator override, since the last trip reset.";
CM_ SG_ 2633937150 TripPTOGovernorTime "Total time accumulated while the engine is in the PTO or remote PTO governor hold state since the last trip reset.";
CM_ BO_ 2633938174 "Trip Time Information 1";
CM_ SG_ 2633938174 TripTimeInDerateByEng "Total time accumulated when the engine final fueling has been derated due to an engine protection algorithm, since the last reset.";
CM_ SG_ 2633938174 TripTimeInGearDown "Total time accumulated when the vehicle has operated in one gear down from the top gear for a calibrated minimum time,";
CM_ SG_ 2633938174 TripTimeInTopGear "Total time accumulated when the vehicle has operated in top gear for a calibrated minimum time, since the last trip reset.";
CM_ SG_ 2633938174 TripTimeInVSL "Total time accumulated when the engine has operated on the vehicle speed limiter (VSL) while not in the cruise hold";
CM_ BO_ 2633938430 "Trip Shutdown Information";
CM_ SG_ 2633938430 TripSuddenDecelerations "Total number of decelerations whenever the vehicle deceleration is more than XYZ km/h/sec (where XYZ is a calibratible";
CM_ SG_ 2633938430 TrpNmberOfIdleShutdownOverrides "Total number of times an operator disables idle shutdown to prevent an engine shutdown, since the last trip reset.";
CM_ SG_ 2633938430 TripNumberOfIdleShutdowns "Total number of times the engine has been shutdown due to idling too long (at normal idle or fast idle) since the last trip reset.";
CM_ SG_ 2633938430 TripNumberOfHotShutdowns "Total number of hot shutdowns since the last trip reset.";
CM_ BO_ 2348875518 "Torque/Speed Control 1";
CM_ SG_ 2348875518 MessageCounter "The message counter is used to detect situations where the transmitting ECU malfunction repeats the same frame all the time.";
CM_ SG_ 2348875518 ControlPurpose "State signal which indicates which control mode the sending device is using to generate the TSC1 command.";
CM_ SG_ 2348875518 TransmissionRate "This parameter indicates the transmission rate at which the sending device will transmit the TSC1 message.";
CM_ SG_ 2348875518 EngRqedTorque_TorqueLimit "Parameter provided to the engine or retarder in the torque/speed control message for controlling or limiting the output torque.";
CM_ SG_ 2348875518 EngRqedSpeed_SpeedLimit "Parameter provided to the engine from external sources in the torque/speed control message.";
CM_ SG_ 2348875518 EngRqedSpeedCtrlConditions "This mode tells the engine control system the governor characteristics that are desired during speed control.";
CM_ SG_ 2348875518 MessageChecksum "The checksum is used to verify the signal path from the transmitting device to the receiving device.";
CM_ SG_ 2348875518 EngineRequestedTorqueHiRes "This parameter displays an additional torque in percent of the reference engine torque.";
CM_ BO_ 2566766846 "Passenger Counter";
CM_ SG_ 2566766846 TransitRunStatus "Status of the run switch for the vehicle.";
CM_ SG_ 2566766846 VehicleUseStatus "Used to indicate the proper or unauthorized use of the vehicle.";
CM_ SG_ 2566766846 SilentAlarmStatus "Used to report silent alarm push button status.";
CM_ SG_ 2566766846 PatronCount "Count of the number of passengers on a transit vehicle.";
CM_ SG_ 2566766846 TypeOfPassengerCount "Used to notify transit link devices of the type of passenger counting system used in the vehicle.";
CM_ BO_ 2566765310 "Farebox Status";
CM_ SG_ 2566765310 FareboxAlarmIdentifier "Indicates the nature of the farebox alarm condition.";
CM_ SG_ 2566765310 FareboxEmergencyStatus "Indicates if a farebox emergency condition exists.";
CM_ BO_ 2566765566 "Farebox Point of Sale";
CM_ SG_ 2566765566 TransferSold "Indicates that a transfer was sold or issued on this transaction including its type and/or restrictions.";
CM_ SG_ 2566765566 RouteNumber "The route number issuing the transfer.";
CM_ SG_ 2566765566 TransferType "The kind of transfer used";
CM_ SG_ 2566765566 TypeOfService "The type of service provided";
CM_ SG_ 2566765566 InitialFareAgency "Identifies where the initial fare is paid";
CM_ SG_ 2566765566 PassCategory "Agency defined value indicating the category of the passenger associated with this fare";
CM_ SG_ 2566765566 FareValidity "Agency defined value indicating validity of this fare";
CM_ SG_ 2566765566 PaymentDetails "Payment details.";
CM_ SG_ 2566765566 TypeOfFare "Type of Fare";
CM_ SG_ 2566765566 PassengerType "Enumerated value representing the type/class of passenger, as defined by the agency.";
CM_ SG_ 2566765566 TransactionType "Enumerated value representing the type of transaction completed";
CM_ BO_ 2566765822 "Farebox Service Detail";
CM_ SG_ 2566765822 DriversFareboxSecurityCode "Security code for the farebox, numerical only.";
CM_ SG_ 2566765822 AssignedBlock "The agency defined block number for this trip";
CM_ SG_ 2566765822 AssignedRun "The agency defined run number for this trip";
CM_ SG_ 2566765822 AssignedRoute "The identity number assigned to this route.";
CM_ SG_ 2566765822 PatternNumber "The agency defined pattern number for this trip";
CM_ SG_ 2566765822 TripNumber "The identity number assigned to this trip.";
CM_ SG_ 2566765822 FarePresets "Fare Presets";
CM_ SG_ 2566765822 TripDirection "The general direction of travel for this trip.";
CM_ SG_ 2566765822 TripStatus "Trip Status";
CM_ SG_ 2566765822 FareboxServiceStatus "Indicates if the farebox is in or out of service.";
CM_ BO_ 2566766078 "Signal Preemption";
CM_ SG_ 2566766078 VehicleID "Numerical designation of the vehicle.";
CM_ SG_ 2566766078 StrobeActivationCtrlStatus "Strobe activation control status";
CM_ SG_ 2566766078 TransitDoorEnable "Transit door enable";
CM_ SG_ 2566766078 PriorityOfRespSentByEmitter "Priority of response sent by emitter";
CM_ SG_ 2566766078 IntersectionPreemptionRq_Resp "Status of the intersection signal preemption";
CM_ SG_ 2566766078 TransitRouteIDUsage "Transit route ID usage";
CM_ SG_ 2566766078 RangeCodeEnable "Range code enable";
CM_ BO_ 2566766590 "Transit Milepost";
CM_ SG_ 2566766590 NmbrOfBytsInMlpstIdentification "Number of bytes in the Milepost Identification.";
CM_ BO_ 2566766334 "Transit Route";
CM_ SG_ 2566766334 Agency "The identity of the agency involved in this transaction";
CM_ SG_ 2566766334 NmbrOfBytsInTrnstAssgndBlckIdntt "Number of bytes in the Transit Assigned Block Identity.";
CM_ SG_ 2566766334 NmbrOfBytsInTrnstAssgndRnIdntty "Number of bytes in the Transit Assigned Run Identity.";
CM_ SG_ 2566766334 NmbrOfBytsInTrnstAssgndRtIdntty "Number of bytes in the Transit Assigned Route Identity.";
CM_ BO_ 2561605374 "Tire Pressure Reference Setting";
CM_ SG_ 2561605374 TireLocation "Identifies which tire is associated with the parametric data in this PGN.";
CM_ BO_ 2566765054 "Tire Pressure Reference Information";
CM_ SG_ 2566765054 TireLocation "Identifies which tire is associated with the parametric data in this PGN.";
CM_ BO_ 2633923326 "Tire Pressure Control Unit Current Pressures";
CM_ SG_ 2633923326 SteerChannelTirePress "The latest gage pressure reading of the steer group of tires, as opposed to the pressure in each tire.";
CM_ SG_ 2633923326 DriveChannelTirePress "The latest gage pressure reading of the drive group of tires, as opposed to the pressure in each tire.";
CM_ SG_ 2633923326 TrailerTagPushChannelTirePress "The latest gage pressure reading of the trailer, tag, or push group of tires, as opposed to the pressure in each tire.";
CM_ BO_ 2633923070 "Tire Pressure Control Unit Target Pressures";
CM_ SG_ 2633923070 SteerChannelTirePressTarget "The tire pressure control system's target gage pressure for the steer group of tires.";
CM_ SG_ 2633923070 DriveChannelTirePressTarget "The tire pressure control system's target gage pressure for the drive group of tires.";
CM_ SG_ 2633923070 TrlrTgPshChannelTirePressTarget "The tire pressure control system's target gage pressure for the trailer, tag, or push group of tires.";
CM_ BO_ 2633922814 "Tire Pressure Control Unit Mode and Status";
CM_ SG_ 2633922814 PCUSupplySolenoidStatus "Current state of the supply solenoid used to implement a tire pressure control system in its pneumatic control unit (PCU).";
CM_ SG_ 2633922814 PCUCtrlSolenoidStatus "Current state of the control solenoid used to implement a tire pressure control system in its pneumatic control unit (PCU).";
CM_ SG_ 2633922814 PCUDeflateSolenoidStatus "Current state of the deflate solenoid used to implement a tire pressure control system in its pneumatic control unit (PCU).";
CM_ SG_ 2633922814 TirePressSupplySwitchStatus "Current state of an open/closed type switch used to determine if adequate pressure exists for system implementation.";
CM_ SG_ 2633922814 PCUSteerSolenoidStatus "Current state of the steer solenoid used to implement a tire pressure control system in its pneumatic control unit (PCU).";
CM_ SG_ 2633922814 PCUDriveSolenoidStatus "Current state of the drive solenoid used to implement a tire pressure control system in its pneumatic control unit (PCU).";
CM_ SG_ 2633922814 DriveChannelMode "Indicates the functional mode of trailer/tag channel of the tire pressure control system.";
CM_ SG_ 2633922814 Trailer_TagChannelMode "Indicates the functional mode of trailer/tag channel of the tire pressure control system.";
CM_ SG_ 2633922814 SteerChannelMode "Indicates the functional mode of steer channel of the tire pressure control system.";
CM_ SG_ 2633922814 TirePressCheckInterval "The interval at which the system will check the tire pressures (e.";
CM_ SG_ 2633922814 PCUTrailerTagPushSolenoidStatus "Current state of the trailer, tag, or push solenoid used to implement a tire pressure control system in its pneumatic control";
CM_ BO_ 2566845694 "Tire Condition";
CM_ SG_ 2566845694 TirePressThresholdDetection_13 "Signal indicating the pressure level of the tire.";
CM_ SG_ 2566845694 TirePressThresholdDetection_12 "Signal indicating the pressure level of the tire.";
CM_ SG_ 2566845694 TirePressThresholdDetection_11 "Signal indicating the pressure level of the tire.";
CM_ SG_ 2566845694 TirePressThresholdDetection_10 "Signal indicating the pressure level of the tire.";
CM_ SG_ 2566845694 TirePressThresholdDetection_01 "Signal indicating the pressure level of the tire.";
CM_ SG_ 2566845694 TirePress_33 "Pressure at which air is contained in cavity formed by tire and rim.";
CM_ SG_ 2566845694 TirePress_32 "Pressure at which air is contained in cavity formed by tire and rim.";
CM_ SG_ 2566845694 TirePress_31 "Pressure at which air is contained in cavity formed by tire and rim.";
CM_ SG_ 2566845694 TirePress_30 "Pressure at which air is contained in cavity formed by tire and rim.";
CM_ SG_ 2566845694 TirePress_23 "Pressure at which air is contained in cavity formed by tire and rim.";
CM_ SG_ 2566845694 TirePress_22 "Pressure at which air is contained in cavity formed by tire and rim.";
CM_ SG_ 2566845694 TirePress_21 "Pressure at which air is contained in cavity formed by tire and rim.";
CM_ SG_ 2566845694 TirePress_20 "Pressure at which air is contained in cavity formed by tire and rim.";
CM_ SG_ 2566845694 TirePress_13 "Pressure at which air is contained in cavity formed by tire and rim.";
CM_ SG_ 2566845694 TirePress_12 "Pressure at which air is contained in cavity formed by tire and rim.";
CM_ SG_ 2566845694 TirePress_11 "Pressure at which air is contained in cavity formed by tire and rim.";
CM_ SG_ 2566845694 TirePress_10 "Pressure at which air is contained in cavity formed by tire and rim.";
CM_ SG_ 2566845694 TireAirLeakageRate_33 "The pressure loss rate of a tire.";
CM_ SG_ 2566845694 TireAirLeakageRate_32 "The pressure loss rate of a tire.";
CM_ SG_ 2566845694 TireAirLeakageRate_31 "The pressure loss rate of a tire.";
CM_ SG_ 2566845694 TireAirLeakageRate_30 "The pressure loss rate of a tire.";
CM_ SG_ 2566845694 TireAirLeakageRate_23 "The pressure loss rate of a tire.";
CM_ SG_ 2566845694 TireAirLeakageRate_22 "The pressure loss rate of a tire.";
CM_ SG_ 2566845694 TireAirLeakageRate_21 "The pressure loss rate of a tire.";
CM_ SG_ 2566845694 TireAirLeakageRate_20 "The pressure loss rate of a tire.";
CM_ SG_ 2566845694 TireAirLeakageRate_13 "The pressure loss rate of a tire.";
CM_ SG_ 2566845694 TireAirLeakageRate_12 "The pressure loss rate of a tire.";
CM_ SG_ 2566845694 TireAirLeakageRate_11 "The pressure loss rate of a tire.";
CM_ SG_ 2566845694 TireAirLeakageRate_10 "The pressure loss rate of a tire.";
CM_ SG_ 2566845694 TireAirLeakageRate_01 "The pressure loss rate of a tire.";
CM_ SG_ 2566845694 TireAirLeakageRate_00 "The pressure loss rate of a tire.";
CM_ SG_ 2566845694 CTIWheelSensorStatus_33 "Indicates whether the wheel is being monitored by the CTI controller.";
CM_ SG_ 2566845694 CTIWheelSensorStatus_32 "Indicates whether the wheel is being monitored by the CTI controller.";
CM_ SG_ 2566845694 CTIWheelSensorStatus_31 "Indicates whether the wheel is being monitored by the CTI controller.";
CM_ SG_ 2566845694 CTIWheelSensorStatus_30 "Indicates whether the wheel is being monitored by the CTI controller.";
CM_ SG_ 2566845694 CTIWheelSensorStatus_23 "Indicates whether the wheel is being monitored by the CTI controller.";
CM_ SG_ 2566845694 CTIWheelSensorStatus_22 "Indicates whether the wheel is being monitored by the CTI controller.";
CM_ SG_ 2566845694 CTIWheelSensorStatus_21 "Indicates whether the wheel is being monitored by the CTI controller.";
CM_ SG_ 2566845694 CTIWheelSensorStatus_20 "Indicates whether the wheel is being monitored by the CTI controller.";
CM_ SG_ 2566845694 CTIWheelSensorStatus_13 "Indicates whether the wheel is being monitored by the CTI controller.";
CM_ SG_ 2566845694 CTIWheelSensorStatus_12 "Indicates whether the wheel is being monitored by the CTI controller.";
CM_ SG_ 2566845694 CTIWheelSensorStatus_11 "Indicates whether the wheel is being monitored by the CTI controller.";
CM_ SG_ 2566845694 CTIWheelSensorStatus_10 "Indicates whether the wheel is being monitored by the CTI controller.";
CM_ SG_ 2566845694 CTIWheelSensorStatus_01 "Indicates whether the wheel is being monitored by the CTI controller.";
CM_ SG_ 2566845694 CTIWheelEndElectricalFault_33 "Indicates the status of electrical fault on CTI wheel interface.";
CM_ SG_ 2566845694 CTIWheelEndElectricalFault_32 "Indicates the status of electrical fault on CTI wheel interface.";
CM_ SG_ 2566845694 CTIWheelEndElectricalFault_31 "Indicates the status of electrical fault on CTI wheel interface.";
CM_ SG_ 2566845694 CTIWheelEndElectricalFault_30 "Indicates the status of electrical fault on CTI wheel interface.";
CM_ SG_ 2566845694 CTIWheelEndElectricalFault_23 "Indicates the status of electrical fault on CTI wheel interface.";
CM_ SG_ 2566845694 CTIWheelEndElectricalFault_22 "Indicates the status of electrical fault on CTI wheel interface.";
CM_ SG_ 2566845694 CTIWheelEndElectricalFault_21 "Indicates the status of electrical fault on CTI wheel interface.";
CM_ SG_ 2566845694 CTIWheelEndElectricalFault_20 "Indicates the status of electrical fault on CTI wheel interface.";
CM_ SG_ 2566845694 CTIWheelEndElectricalFault_13 "Indicates the status of electrical fault on CTI wheel interface.";
CM_ SG_ 2566845694 CTIWheelEndElectricalFault_12 "Indicates the status of electrical fault on CTI wheel interface.";
CM_ SG_ 2566845694 CTIWheelEndElectricalFault_11 "Indicates the status of electrical fault on CTI wheel interface.";
CM_ SG_ 2566845694 CTIWheelEndElectricalFault_10 "Indicates the status of electrical fault on CTI wheel interface.";
CM_ SG_ 2566845694 CTIWheelEndElectricalFault_01 "Indicates the status of electrical fault on CTI wheel interface.";
CM_ SG_ 2566845694 CTITireStatus_33 "Indicates the status of the tire.";
CM_ SG_ 2566845694 CTITireStatus_32 "Indicates the status of the tire.";
CM_ SG_ 2566845694 CTITireStatus_31 "Indicates the status of the tire.";
CM_ SG_ 2566845694 CTITireStatus_30 "Indicates the status of the tire.";
CM_ SG_ 2566845694 CTITireStatus_23 "Indicates the status of the tire.";
CM_ SG_ 2566845694 CTITireStatus_22 "Indicates the status of the tire.";
CM_ SG_ 2566845694 CTITireStatus_21 "Indicates the status of the tire.";
CM_ SG_ 2566845694 CTITireStatus_20 "Indicates the status of the tire.";
CM_ SG_ 2566845694 CTITireStatus_13 "Indicates the status of the tire.";
CM_ SG_ 2566845694 CTITireStatus_12 "Indicates the status of the tire.";
CM_ SG_ 2566845694 CTITireStatus_11 "Indicates the status of the tire.";
CM_ SG_ 2566845694 CTITireStatus_10 "Indicates the status of the tire.";
CM_ SG_ 2566845694 CTITireStatus_01 "Indicates the status of the tire.";
CM_ SG_ 2566845694 TireTemp_11 "Temperature at the surface of the tire sidewall.";
CM_ SG_ 2566845694 TireTemp_33 "Temperature at the surface of the tire sidewall.";
CM_ SG_ 2566845694 TireTemp_32 "Temperature at the surface of the tire sidewall.";
CM_ SG_ 2566845694 TireTemp_31 "Temperature at the surface of the tire sidewall.";
CM_ SG_ 2566845694 TireTemp_30 "Temperature at the surface of the tire sidewall.";
CM_ SG_ 2566845694 TireTemp_23 "Temperature at the surface of the tire sidewall.";
CM_ SG_ 2566845694 TireTemp_22 "Temperature at the surface of the tire sidewall.";
CM_ SG_ 2566845694 TireTemp_21 "Temperature at the surface of the tire sidewall.";
CM_ SG_ 2566845694 TireTemp_20 "Temperature at the surface of the tire sidewall.";
CM_ SG_ 2566845694 TireTemp_13 "Temperature at the surface of the tire sidewall.";
CM_ SG_ 2566845694 TireTemp_12 "Temperature at the surface of the tire sidewall.";
CM_ SG_ 2566845694 TireTemp_10 "Temperature at the surface of the tire sidewall.";
CM_ SG_ 2566845694 TireTemp_01 "Temperature at the surface of the tire sidewall.";
CM_ SG_ 2566845694 TireTemp_00 "Temperature at the surface of the tire sidewall.";
CM_ SG_ 2566845694 TirePressThresholdDetection_33 "Signal indicating the pressure level of the tire.";
CM_ SG_ 2566845694 TirePressThresholdDetection_32 "Signal indicating the pressure level of the tire.";
CM_ SG_ 2566845694 TirePressThresholdDetection_31 "Signal indicating the pressure level of the tire.";
CM_ SG_ 2566845694 TirePressThresholdDetection_30 "Signal indicating the pressure level of the tire.";
CM_ SG_ 2566845694 TirePressThresholdDetection_23 "Signal indicating the pressure level of the tire.";
CM_ SG_ 2566845694 TirePressThresholdDetection_22 "Signal indicating the pressure level of the tire.";
CM_ SG_ 2566845694 TirePressThresholdDetection_21 "Signal indicating the pressure level of the tire.";
CM_ SG_ 2566845694 TirePressThresholdDetection_20 "Signal indicating the pressure level of the tire.";
CM_ SG_ 2566845694 TirePressThresholdDetection_00 "Signal indicating the pressure level of the tire.";
CM_ SG_ 2566845694 TirePress_01 "Pressure at which air is contained in cavity formed by tire and rim.";
CM_ SG_ 2566845694 TirePress_00 "Pressure at which air is contained in cavity formed by tire and rim.";
CM_ SG_ 2566845694 CTIWheelSensorStatus_00 "Indicates whether the wheel is being monitored by the CTI controller.";
CM_ SG_ 2566845694 CTIWheelEndElectricalFault_00 "Indicates the status of electrical fault on CTI wheel interface.";
CM_ SG_ 2566845694 CTITireStatus_00 "Indicates the status of the tire.";
CM_ SG_ 2566845694 TireLocation "Identifies which tire is associated with the parametric data in this PGN.";
CM_ BO_ 2633939966 "Trip Fan Information";
CM_ SG_ 2633939966 TripFanOnTimeDueToAManualSwitch "Total time the fan has been on due to manual activation by the operator (i.";
CM_ SG_ 2633939966 TripFanOnTime "Total time the fan has been on (due to an automatic trigger or manual trigger) since the last trip reset.";
CM_ SG_ 2633939966 TripFanOnTimeDueToA_CSystem "Total time the fan has been on due to the A/C system since the last trip reset.";
CM_ SG_ 2633939966 TripFanOnTimeDueToEngSystem "Total time the fan has been on due to engine triggers (i.";
CM_ BO_ 2633939710 "Trip Distance Information";
CM_ SG_ 2633939710 TripDistanceInTopGear "Total distance accumulated while the vehicle has operated in top gear for a calibrated minimum time since the last trip reset.";
CM_ SG_ 2633939710 TripGearDownDistance "Total distance accumulated while the vehicle has operated in the gear which is one gear down from top gear and exceeds";
CM_ SG_ 2633939710 TripDistanceOnVSL "Total distance accumulated while the engine torque mode is road speed governing since the last trip reset.";
CM_ BO_ 2564161278 "Time/Date Adjust";
CM_ SG_ 2564161278 AdjustLocalHourOffset "The hour component for setting the offset between the UTC (Universal Time Coordinate) time and date and a the local";
CM_ SG_ 2564161278 AdjustLocalMinuteOffset "The minute component for setting the offset between the UTC (Universal Time Coordinate) time and date and a the local";
CM_ SG_ 2564161278 AdjustYear "The year component for setting the current calendar date.";
CM_ SG_ 2564161278 AdjustDay "The day component for setting the current calendar date.";
CM_ SG_ 2564161278 AdjustMonth "The month component for setting the current calendar date.";
CM_ SG_ 2564161278 AdjustHours "The hours component for setting the current time of day.";
CM_ SG_ 2564161278 AdjustMinutes "The minutes component for setting the current time of day.";
CM_ SG_ 2564161278 AdjustSeconds "The seconds component for setting the current time of day.";
CM_ BO_ 2566842110 "Time/Date";
CM_ SG_ 2566842110 LocalHourOffset "The hour component of the offset between the UTC (Universal Time Coordinate) time and date and a local time zone time";
CM_ SG_ 2566842110 LocalMinuteOffset "The minute component of the offset between the UTC time and date and a local time zone time and date.";
CM_ SG_ 2566842110 Year "The year component of the current calendar date.";
CM_ SG_ 2566842110 Day "The day component of the current calendar date.";
CM_ SG_ 2566842110 Month "The month component of the current calendar date.";
CM_ SG_ 2566842110 Hours "The hour component of the current time of day.";
CM_ SG_ 2566842110 Minutes "The minutes component of the current time of day.";
CM_ SG_ 2566842110 Seconds "The seconds component of the current time of day.";
CM_ BO_ 2566821630 "Turbocharger Wastegate";
CM_ SG_ 2566821630 EngTrbWstgteActuator1TempStatus "Used to identify the status of the Engine Turbocharger Wastegate Actuator 1 drive circuitry temperature.";
CM_ SG_ 2566821630 EngTrbWstgtActtr1PreliminaryFMI "Used to identify the applicable J1939-73 FMI detected in the Engine Turbocharger Wastegate Actuator 1 by the";
CM_ SG_ 2566821630 EngDsrdTrbWastegateActuator2Pos "The Requested Valve position of the Turbocharger Wastegate Valve 2, commanded by the engine ECM.";
CM_ SG_ 2566821630 EngDsrdTrbWastegateActuator1Pos "The Requested Valve position of the Turbocharger Wastegate Valve 1, commanded by the engine ECM.";
CM_ SG_ 2566821630 EngTurboWastegateActuator4Pos "Position of the wastegate drive.";
CM_ SG_ 2566821630 EngTurboWastegateActuator3Pos "Position of the wastegate drive.";
CM_ SG_ 2566821630 EngTurboWastegateActuator2Pos "Position of the wastegate drive.";
CM_ SG_ 2566821630 EngTurboWastegateActuator1Pos "Position of the wastegate drive.";
CM_ SG_ 2566821630 EngTrbWstgtActuatorCtrlAirPress "Gage pressure of the air used to control the actuator which opens and closes the wastegate valve.";
CM_ BO_ 2365484286 "Tachograph";
CM_ SG_ 2365484286 VehicleOverspeed "Indicates whether the vehicle is exceeding the legal speed limit set in the tachograph.";
CM_ SG_ 2365484286 VehicleMotion "Indicates whether motion of the vehicle is detected or not.";
CM_ SG_ 2365484286 TachographVehicleSpeed "Speed of the vehicle registered by the tachograph.";
CM_ SG_ 2365484286 TachographOutputShaftSpeed "Calculated speed of the transmission output shaft.";
CM_ SG_ 2365484286 DirectionIndicator "Indicates the direction of the vehicle.";
CM_ SG_ 2365484286 TachographPerformance "Indicates the tachograph performance; including electronic or mechanical analysis, instrument analysis, speed sensor";
CM_ SG_ 2365484286 HandlingInformation "Indicates that handling information is present.";
CM_ SG_ 2365484286 SystemEvent "Indicates that a tachograph event has occurred.";
CM_ SG_ 2365484286 DriverCardDriver2 "Indicates the presence of a driver card";
CM_ SG_ 2365484286 Driver2TimeRelatedStates "Indicates if the driver approaches or exceeds working time limits (or other limits).";
CM_ SG_ 2365484286 DriverCardDriver1 "Indicates the presence of a driver card";
CM_ SG_ 2365484286 Driver1TimeRelatedStates "Indicates if the driver approaches or exceeds working time limits (or other limits).";
CM_ SG_ 2365484286 Driver2WorkingState "State of work of the driver.";
CM_ SG_ 2365484286 Driver1WorkingState "State of work of the driver.";
CM_ BO_ 2566771710 "Turbocharger Information 6";
CM_ SG_ 2566771710 EngTurbo4CompressorOutletTemp "Temperature of the air exiting the turbocharger 4 compressor outlet";
CM_ SG_ 2566771710 EngTurbo3CompressorOutletTemp "Temperature of the air exiting the turbocharger 3 compressor outlet";
CM_ SG_ 2566771710 EngTurbo2CompressorOutletTemp "Temperature of the air exiting the turbocharger 2 compressor outlet";
CM_ SG_ 2566771710 EngTurbo1CompressorOutletTemp "Temperature of the air exiting the turbocharger 1 compressor outlet";
CM_ BO_ 2566821886 "Turbocharger Information 5";
CM_ SG_ 2566821886 EngTurbo4TurbineOutletTemp "Temperature of the combustion by-products exiting the turbine side of the turbocharger.";
CM_ SG_ 2566821886 EngTurbo3TurbineOutletTemp "Temperature of the combustion by-products exiting the turbine side of the turbocharger.";
CM_ SG_ 2566821886 EngTurbo2TurbineOutletTemp "Temperature of the combustion by-products exiting the turbine side of the turbocharger.";
CM_ SG_ 2566821886 EngTurbo1TurbineOutletTemp "Temperature of the combustion by-products exiting the turbine side of the turbocharger.";
CM_ BO_ 2566822142 "Turbocharger Information 4";
CM_ SG_ 2566822142 EngTurbo4TurbineIntakeTemp "Temperature of the combustion by-products entering the turbine side of the turbocharger.";
CM_ SG_ 2566822142 EngTurbo3TurbineIntakeTemp "Temperature of the combustion by-products entering the turbine side of the turbocharger.";
CM_ SG_ 2566822142 EngTurbo2TurbineIntakeTemp "Temperature of the combustion by-products entering the turbine side of the turbocharger.";
CM_ SG_ 2566822142 EngTurbo1TurbineIntakeTemp "Temperature of the combustion by-products entering the turbine side of the turbocharger.";
CM_ BO_ 2566822398 "Turbocharger Information 3";
CM_ SG_ 2566822398 EngTurbo4CompressorIntakePress "Gage pressure of the air entering the compressor side of the turbocharger.";
CM_ SG_ 2566822398 EngTurbo3CompressorIntakePress "Gage pressure of the air entering the compressor side of the turbocharger.";
CM_ SG_ 2566822398 EngTurbo2CompressorIntakePress "Gage pressure of the air entering the compressor side of the turbocharger.";
CM_ SG_ 2566822398 EngTurbo1CompressorIntakePress "Gage pressure of the air entering the compressor side of the turbocharger.";
CM_ BO_ 2566822654 "Turbocharger Information 2";
CM_ SG_ 2566822654 EngTurbo4CompressorIntakeTemp "Temperature of the air entering the compressor side of the turbocharger.";
CM_ SG_ 2566822654 EngTurbo3CompressorIntakeTemp "Temperature of the air entering the compressor side of the turbocharger.";
CM_ SG_ 2566822654 EngTurbo2CompressorIntakeTemp "Temperature of the air entering the compressor side of the turbocharger.";
CM_ SG_ 2566822654 EngTurbo1CompressorIntakeTemp "Temperature of the air entering the compressor side of the turbocharger.";
CM_ BO_ 2633931774 "Turbocharger Information 1";
CM_ SG_ 2633931774 EngTurbo4Speed "Rotational velocity of rotor in the turbocharger.";
CM_ SG_ 2633931774 EngTurbo3Speed "Rotational velocity of rotor in the turbocharger.";
CM_ SG_ 2633931774 EngTurbo2Speed "Rotational velocity of rotor in the turbocharger.";
CM_ SG_ 2633931774 EngTurboLubeOilPress2 "Gage pressure of oil in turbocharger lubrication system.";
CM_ BO_ 2566802430 "Transmission Configuration 2";
CM_ SG_ 2566802430 TransTorqueLimit "Parameter provided to the engine from the transmission as a torque limit to be invoked by the engine in the event that";
CM_ BO_ 2566841086 "Transmission Configuration";
CM_ SG_ 2566841086 TransGearRatio "The transmission configuration describes the number of forward gears, the number of reverse gears, and the ratio of each";
CM_ SG_ 2566841086 NumberOfForwardGearRatios "Number of forward gear ratios in the transmission, provided as part of the configuration.";
CM_ SG_ 2566841086 NumberOfReverseGearRatios "Number of reverse gear ratios in the transmission, provided as part of the transmission configuration.";
CM_ BO_ 2348941054 "Transmission Control 1";
CM_ SG_ 2348941054 TrnsShftSlctorDisplayModeSwitch "Status of the operator's switch used to `toggle' through multiple display modes of a shift selector display.";
CM_ SG_ 2348941054 TransMode4 "Indicates whether transmission mode 4 is enabled.";
CM_ SG_ 2348941054 TransMode3 "Indicates whether transmission mode 3 is enabled.";
CM_ SG_ 2348941054 TransMode2 "Indicates whether transmission mode 2 is enabled.";
CM_ SG_ 2348941054 TransMode1 "Indicates whether transmission mode 1 is enabled.";
CM_ SG_ 2348941054 DisengageDiffLockRqCentralRear "Command signal used to disengage the various differential locks, e.";
CM_ SG_ 2348941054 DisengageDiffLockRqCentralFront "Command signal used to disengage the various differential locks, e.";
CM_ SG_ 2348941054 DisengageDiffLockRqCentral "Command signal used to disengage the various differential locks, e.";
CM_ SG_ 2348941054 DisengageDiffLockRqRearAxle2 "Command signal used to disengage the various differential locks, e.";
CM_ SG_ 2348941054 DisengageDiffLockRqRearAxle1 "Command signal used to disengage the various differential locks, e.";
CM_ SG_ 2348941054 DisengageDiffLockRqFrontAxle2 "Command signal used to disengage the various differential locks, e.";
CM_ SG_ 2348941054 DisengageDiffLockRqFrontAxle1 "Command signal used to disengage the various differential locks, e.";
CM_ SG_ 2348941054 TransRqedGear "Gear requested by the operator, ABS, or engine.";
CM_ SG_ 2348941054 RqedPercentClutchSlip "Parameter which represents the percent clutch slip requested by a device.";
CM_ SG_ 2348941054 DisengageDrivelineRq "Command signal used to simply disengage the driveline, e.";
CM_ SG_ 2348941054 TransGearShiftInhibitRq "Command signal to inhibit gear shifts.";
CM_ SG_ 2348941054 TrnsTrqConverterLockupDisableRq "Command signal to prevent torque converter lockup, which may cause problems in certain circumstances for ASR.";
CM_ SG_ 2348941054 TransRqedLaunchGear "Initial gear for the transmission to start out in when the vehicle is launched from a standing stop, as specified by the";
CM_ SG_ 2348941054 TransReverseGearShiftInhibitRq "Allows devices external to the normal transmission shift selector system to request the transmission to inhibit shifts into";
CM_ SG_ 2348941054 TransMode8 "Indicates whether transmission mode 8 is enabled.";
CM_ SG_ 2348941054 TransMode7 "Indicates whether transmission mode 7 is enabled.";
CM_ SG_ 2348941054 TransMode6 "Indicates whether transmission mode 6 is enabled.";
CM_ SG_ 2348941054 TransMode5 "Indicates whether transmission mode 5 is enabled.";
CM_ BO_ 2566839806 "Turbocharger";
CM_ SG_ 2566839806 EngTurboOilLevelSwitch "Switch signal which indicates the presence of oil at the turbocharger";
CM_ SG_ 2566839806 EngTurbo1Speed "Rotational velocity of rotor in the turbocharger.";
CM_ SG_ 2566839806 EngTurboLubeOilPress1 "Gage pressure of oil in turbocharger lubrication system.";
CM_ BO_ 2633911806 "Total Averaged Information";
CM_ SG_ 2633911806 EngTotalAverageFuelEconomy "Average fuel economy, equal to total vehicle distance divided by total fuel used, over the life of the engine";
CM_ SG_ 2633911806 EngTotalAverageFuelRate "Average fuel rate, equal to total fuel used divided by total engine hours, over the life of the engine";
CM_ BO_ 2566775550 "Supply Pressure Demand";
CM_ SG_ 2566775550 AirSuspensionSupplyPressRq "Command signal to influence the pneumatic pressure in the circuit for the electronically controlled air suspension system.";
CM_ SG_ 2566775550 AuxEquipmentSupplyPressRq "Command signal to influence the pneumatic pressure in the auxiliary circuit.";
CM_ SG_ 2566775550 ServiceBrakeAirPressRqCircuit2 "Command signal to influence the pneumatic pressure in the service brake circuit or reservoir #2.";
CM_ SG_ 2566775550 ServiceBrakeAirPressRqCircuit1 "Command signal to influence the pneumatic pressure in the service brake circuit or reservoir #1.";
CM_ SG_ 2566775550 ParkingAnd_OrTrailerAirPressRq "Command signal to influence the pneumatic pressure in the circuit or reservoir for the parking brake and/or the trailer supply.";
CM_ SG_ 2566775550 PneumaticSupplyPressRq "Command signal to influence the pneumatic pressure in the main reservoir.";
CM_ BO_ 2566819838 "Supply Pressure 2";
CM_ SG_ 2566819838 EngExtlShutdownAirSupplyPress "Pressure of the air used to shut off the fuel supply to the engine.";
CM_ BO_ 2566839038 "Software Identification";
CM_ SG_ 2566839038 NmbrOfSftwrIdentificationFields "Number of software identification designators represented in the software identification parameter group.";
CM_ SG_ 2566839038 SoftwareID3 "Software ID";
CM_ SG_ 2566839038 SoftwareID2 "Software ID";
CM_ SG_ 2566839038 SoftwareID1 "Software ID";
CM_ BO_ 2566841598 "Shutdown";
CM_ SG_ 2566841598 EngOverspeedTest "The engine overspeed test signal as measured by the reporting ECM.";
CM_ SG_ 2566841598 EngAirShutoffCmdStatus "State signal which indicates when the Air Shutoff driver output is being driven.";
CM_ SG_ 2566841598 EngAlarmOutputCmdStatus "State signal which indicates when the Alarm driver output is being driven.";
CM_ SG_ 2566841598 EngAlarmAcknowledge "The Engine Alarm Acknowledge Input signal as measured by the reporting ECM.";
CM_ SG_ 2566841598 EngProtectionSystemConfig "Parameter which indicates the configuration of the engine shutdown system.";
CM_ SG_ 2566841598 EngProtectionSystemTimerState "Status signal which indicates the current mode of the engine protection system timer system.";
CM_ SG_ 2566841598 EngPrtectionSystemTimerOverride "Status signal which indicates the status of the override feature of the engine protection system timer.";
CM_ SG_ 2566841598 EngPrtctnSystmApprchingShutdown "Status signal which indicates that engine shutdown is imminent.";
CM_ SG_ 2566841598 EngWaitToStartLamp "Lamp signal which indicates that the engine is too cold to start and the operator should wait until the signal becomes";
CM_ SG_ 2566841598 RefrigerantHighPressSwitch "Switch signal which indicates the position of the high pressure switch in the coolant circuit of an air conditioning system.";
CM_ SG_ 2566841598 RefrigerantLowPressSwitch "Switch signal which indicates the position of the low pressure switch in the coolant circuit of an air conditioning system.";
CM_ SG_ 2566841598 A_CHighPressFanSwitch "Switch signal which indicates that the pressure in the coolant circuit of an air conditioning system is high and the fan may";
CM_ SG_ 2566841598 EngIdleShutdownTimerFunction "Parameter which indicates the configuration of the idle shutdown timer system.";
CM_ SG_ 2566841598 EngIdleShutdownTimerState "Status signal which indicates the current mode of operation of the idle shutdown timer system.";
CM_ SG_ 2566841598 EngIdleShutdownTimerOverride "Status signal which indicates the status of the override feature of the idle shutdown timer system.";
CM_ SG_ 2566841598 EngIdleShutdownDriverAlertMode "Status signal which indicates the status of the driver alert mode of the idle shutdown timer system.";
CM_ SG_ 2566841598 PTOShutdownHasShutdownEng "Status signal which identifies whether or not the engine has been shutdown by the PTO shutdown system.";
CM_ SG_ 2566841598 EngPrtctnSystmHasShutdownEngine "Status signal which indicates whether or not the engine protection system has shutdown the engine.";
CM_ SG_ 2566841598 EngIdlShutdownHasShutdownEngine "Status signal which identifies whether or not the engine has been shutdown by the idle shutdown timer system.";
CM_ SG_ 2566841598 EngAirShutoffStatus "State signal which indicates the actual measured position of the Air Shutoff.";
CM_ BO_ 2566832382 "Service Information";
CM_ SG_ 2566832382 ServiceComponentIdentificationB "Identification of component needing service.";
CM_ SG_ 2566832382 ServiceComponentIdentificationA "Identification of component needing service.";
CM_ SG_ 2566832382 SrvceDelay_OperationalTimeBased "The time in vehicle operational time until the next vehicle service inspection is required.";
CM_ SG_ 2566832382 ServiceDelay_CalendarTimeBased "The time in weeks until the next vehicle service inspection is required.";
CM_ SG_ 2566832382 ServiceDistance "The distance which can be traveled by the vehicle before the next service inspection is required.";
CM_ SG_ 2566832382 ServiceComponentIdentification "Identification of component needing service.";
CM_ BO_ 2633928446 "Service 2";
CM_ SG_ 2633928446 TimeSinceLastService "The vehicle operation time since the last service was performed.";
CM_ SG_ 2633928446 ServiceComponentIdentification "Identification of component needing service.";
CM_ BO_ 2566804478 "Retarder Continuous Torque & Speed Limit";
CM_ SG_ 2566804478 MaxContinuousRetarderTorque "Applied limit for maximum continuous retarder torque.";
CM_ SG_ 2566804478 MinContinuousRetarderSpeed "Applied limit for minimum continuous retarder RPM";
CM_ SG_ 2566804478 MaxContinuousRetarderSpeed "Applied limit for maximum continuous retarder RPM";
CM_ SG_ 2566804478 MinContinuousRetarderTorque "Applied limit for minimum continuous retarder torque";
CM_ SG_ 2566804478 LwLmtThrshldFrMxTrqFromRetarder "Minimum allowable value for maximum continuous retarder torque.";
CM_ SG_ 2566804478 LwLmtThrshldFrMxRPMFromRetarder "Minimum allowable value for maximum continuous retarder speed";
CM_ SG_ 2566804478 HghLmtThrshldFrMnCntnsTrqFrmRtrd "Maximum allowable value for minimum continuous retarder torque.";
CM_ SG_ 2566804478 HghLmtThrshldFrMnCntnsRPMFrmRtrd "Maximum allowable value for minimum continuous retarder speed";
CM_ BO_ 2566847486 "Retarder fluids";
CM_ SG_ 2566847486 DrvlneRetarderOverheatIndicator "Signal from the driveline retarder indicating that its fluid temperature is above normal acceptable limits, and as a result,";
CM_ SG_ 2566847486 HydRetarderOilTemp "Temperature of oil found in a hydraulic retarder.";
CM_ SG_ 2566847486 HydRetarderPress "Gage pressure of oil in hydraulic retarder system.";
CM_ BO_ 2631859966 "Reset";
CM_ SG_ 2631859966 EngBuildHoursReset "Command signal used to reset the engine rebuild hours.";
CM_ SG_ 2631859966 TripGroup2Proprietary "Command signal used to reset proprietary parameters associated with a trip but not defined within this document.";
CM_ SG_ 2631859966 TripGroup1 "Command signal used to reset the PGNs and parameters as defined in Table SPN988_A.";
CM_ SG_ 2631859966 SteerStraightAheadPosReset "Used to reset the straight ahead position for a steering sensor in the steering column or a steering controller's straight";
CM_ SG_ 2631859966 ServiceComponentIdentification "Identification of component needing service.";
CM_ SG_ 2631859966 ServiceComponentIdentificationC "Identification of component needing service.";
BA_DEF_ SG_  "SigType" ENUM  "Default","Range","RangeSigned","ASCII","Discrete","Control","ReferencePGN","DTC","StringDelimiter","StringLength","StringLengthControl";
BA_DEF_ SG_  "GenSigStartValue" INT 0 10000;
BA_DEF_ SG_  "GenSigSendType" ENUM  "Cyclic","OnWrite","reserved","OnChange","reserved","reserved","reserved","NoSigSendType";
BA_DEF_ SG_  "GenSigILSupport" ENUM  "Yes","No";
BA_DEF_ SG_  "GenSigEVName" STRING ;
BA_DEF_ SG_  "SPN" INT 0 524287;
BA_DEF_ BO_  "GenMsgStartDelayTime" INT 0 100000;
BA_DEF_ BO_  "GenMsgILSupport" ENUM  "Yes","No";
BA_DEF_ BO_  "GenMsgRequestable" INT 0 1;
BA_DEF_ BO_  "GenMsgSendType" ENUM  "cyclic","reserved","cyclicIfActive","reserved","reserved","reserved","reserved","reserved","noMsgSendType";
BA_DEF_ BO_  "VFrameFormat" ENUM  "StandardCAN","ExtendedCAN","reserved","J1939PG";
BA_DEF_ BO_  "GenMsgCycleTime" INT 0 3600000;
BA_DEF_ SG_  "SystemSignalLongSymbol" STRING ;
BA_DEF_DEF_  "SigType" "Default";
BA_DEF_DEF_  "GenSigStartValue" 0;
BA_DEF_DEF_  "GenSigSendType" "NoSigSendType";
BA_DEF_DEF_  "GenSigILSupport" "Yes";
BA_DEF_DEF_  "GenSigEVName" "Env@Nodename_@Signame";
BA_DEF_DEF_  "SPN" 0;
BA_DEF_DEF_  "GenMsgStartDelayTime" 0;
BA_DEF_DEF_  "GenMsgILSupport" "Yes";
BA_DEF_DEF_  "GenMsgRequestable" 1;
BA_DEF_DEF_  "GenMsgSendType" "noMsgSendType";
BA_DEF_DEF_  "VFrameFormat" "J1939PG";
BA_DEF_DEF_  "GenMsgCycleTime" 0;
BA_DEF_DEF_  "SystemSignalLongSymbol" "";
BA_ "GenMsgCycleTime" BO_ 2566808574 1000;
BA_ "GenMsgSendType" BO_ 2566808574 0;
BA_ "GenMsgCycleTime" BO_ 2566809086 100;
BA_ "GenMsgSendType" BO_ 2566809086 0;
BA_ "GenMsgCycleTime" BO_ 2564947710 100;
BA_ "GenMsgSendType" BO_ 2564947710 0;
BA_ "GenMsgCycleTime" BO_ 2566834430 100;
BA_ "GenMsgSendType" BO_ 2566834430 0;
BA_ "GenMsgCycleTime" BO_ 2365481214 100;
BA_ "GenMsgSendType" BO_ 2365481214 0;
BA_ "GenMsgCycleTime" BO_ 2566808318 100;
BA_ "GenMsgSendType" BO_ 2566808318 0;
BA_ "GenMsgCycleTime" BO_ 2566808830 100;
BA_ "GenMsgSendType" BO_ 2566808830 0;
BA_ "GenMsgCycleTime" BO_ 2565144318 100;
BA_ "GenMsgSendType" BO_ 2565144318 0;
BA_ "GenMsgCycleTime" BO_ 2565209854 100;
BA_ "GenMsgSendType" BO_ 2565209854 0;
BA_ "GenMsgCycleTime" BO_ 2566806782 100;
BA_ "GenMsgSendType" BO_ 2566806782 0;
BA_ "GenMsgCycleTime" BO_ 2566807294 1000;
BA_ "GenMsgSendType" BO_ 2566807294 0;
BA_ "GenMsgCycleTime" BO_ 2349137662 20;
BA_ "GenMsgSendType" BO_ 2349137662 2;
BA_ "GenMsgCycleTime" BO_ 2566848510 10000;
BA_ "GenMsgSendType" BO_ 2566848510 0;
BA_ "GenMsgCycleTime" BO_ 2566804222 1000;
BA_ "GenMsgSendType" BO_ 2566804222 0;
BA_ "GenMsgCycleTime" BO_ 2566845438 5000;
BA_ "GenMsgSendType" BO_ 2566845438 0;
BA_ "GenMsgCycleTime" BO_ 2566809854 1000;
BA_ "GenMsgSendType" BO_ 2566809854 0;
BA_ "GenMsgCycleTime" BO_ 2566832638 1000;
BA_ "GenMsgSendType" BO_ 2566832638 0;
BA_ "GenMsgCycleTime" BO_ 2565868030 10;
BA_ "GenMsgSendType" BO_ 2565868030 0;
BA_ "GenMsgCycleTime" BO_ 2566803454 100;
BA_ "GenMsgSendType" BO_ 2566803454 0;
BA_ "GenMsgCycleTime" BO_ 2566840574 100;
BA_ "GenMsgSendType" BO_ 2566840574 0;
BA_ "GenMsgCycleTime" BO_ 2566845694 10000;
BA_ "GenMsgSendType" BO_ 2566845694 0;
BA_ "GenMsgCycleTime" BO_ 2566821630 100;
BA_ "GenMsgSendType" BO_ 2566821630 0;
BA_ "GenMsgCycleTime" BO_ 2365484286 50;
BA_ "GenMsgSendType" BO_ 2365484286 0;
BA_ "GenMsgCycleTime" BO_ 2566771710 1000;
BA_ "GenMsgSendType" BO_ 2566771710 0;
BA_ "GenMsgCycleTime" BO_ 2566821886 1000;
BA_ "GenMsgSendType" BO_ 2566821886 0;
BA_ "GenMsgCycleTime" BO_ 2566822142 1000;
BA_ "GenMsgSendType" BO_ 2566822142 0;
BA_ "GenMsgCycleTime" BO_ 2566822398 1000;
BA_ "GenMsgSendType" BO_ 2566822398 0;
BA_ "GenMsgCycleTime" BO_ 2566822654 1000;
BA_ "GenMsgSendType" BO_ 2566822654 0;
BA_ "GenMsgCycleTime" BO_ 2633931774 1000;
BA_ "GenMsgSendType" BO_ 2633931774 0;
BA_ "GenMsgCycleTime" BO_ 2566839806 1000;
BA_ "GenMsgSendType" BO_ 2566839806 0;
BA_ "GenMsgCycleTime" BO_ 2566775550 1000;
BA_ "GenMsgSendType" BO_ 2566775550 2;
BA_ "GenMsgCycleTime" BO_ 2566819838 1000;
BA_ "GenMsgSendType" BO_ 2566819838 0;
BA_ "GenMsgCycleTime" BO_ 2566841598 1000;
BA_ "GenMsgSendType" BO_ 2566841598 0;
BA_ "GenMsgCycleTime" BO_ 2566804478 5000;
BA_ "GenMsgSendType" BO_ 2566804478 0;
BA_ "GenMsgCycleTime" BO_ 2566847486 1000;
BA_ "GenMsgSendType" BO_ 2566847486 0;
BA_ "SigType" SG_ 2566808574 ReferenceEngineTorque 1;
BA_ "SigType" SG_ 2566808574 FuelLevelWarning 4;
BA_ "SigType" SG_ 2566808574 EngineOilPressureWarning 4;
BA_ "SigType" SG_ 2566808574 EngineOilPressure 1;
BA_ "SPN" SG_ 2566808574 EngineCoolantTemperature 110;
BA_ "SigType" SG_ 2566808574 EngineCoolantTemperature 1;
BA_ "SigType" SG_ 2566808574 EngineOilTemperature 1;
BA_ "SigType" SG_ 2566809086 AmbientAirTemperature 1;
BA_ "SigType" SG_ 2566834430 AntiTheftDeviceStatus 4;
BA_ "SigType" SG_ 2566834430 ODDStatus 4;
BA_ "SigType" SG_ 2566808318 SecEngineMtdPTOSwitch 4;
BA_ "SigType" SG_ 2566808318 SecClutchDpdtPTOSwitch 4;
BA_ "SigType" SG_ 2566808318 FirstClutchDpdtPTOSwitch 4;
BA_ "SigType" SG_ 2566808318 OperatingPanelActive 4;
BA_ "SigType" SG_ 2566808318 RefusePackerStepSwitch 4;
BA_ "SigType" SG_ 2566808318 EngineStopSwitch 4;
BA_ "SigType" SG_ 2566808318 EngineStartSwitch 4;
BA_ "SigType" SG_ 2566808318 StarterLockoutSwitch 4;
BA_ "SigType" SG_ 2566808318 RqstedPercentClutchSlip 1;
BA_ "SigType" SG_ 2566808318 FirstEngineMtdPTOSwitch 4;
BA_ "SigType" SG_ 2566808318 ClutchIndpdtPTOSwitch 4;
BA_ "SigType" SG_ 2566808830 TrailerLeftSideMarkerLight 4;
BA_ "SigType" SG_ 2566808830 TrailerLeftReversingLight 4;
BA_ "SigType" SG_ 2566808830 TrailerLeftRearWidIndLight 4;
BA_ "SigType" SG_ 2566808830 TrailerLeftRearRegPltLight 4;
BA_ "SigType" SG_ 2566808830 TrailerLeftRearLight 4;
BA_ "SigType" SG_ 2566808830 TrailerLeftRearFogLight 4;
BA_ "SigType" SG_ 2566808830 TrailerLeftDirIndLight 4;
BA_ "SigType" SG_ 2566808830 TrailerLeftCrnMarkerLight 4;
BA_ "SigType" SG_ 2566808830 TrailerInteriorLight 4;
BA_ "SigType" SG_ 2566808830 TrailerWorkLamp 4;
BA_ "SigType" SG_ 2566808830 TrailerRotatingIdentLight 4;
BA_ "SigType" SG_ 2566808830 TrailerRightStopLight 4;
BA_ "SigType" SG_ 2566808830 TrailerRightSideMrkLight 4;
BA_ "SigType" SG_ 2566808830 TrailerRightReversingLight 4;
BA_ "SigType" SG_ 2566808830 TrailRightRearWidIndLight 4;
BA_ "SigType" SG_ 2566808830 TrailerRightRearRegPltLight 4;
BA_ "SigType" SG_ 2566808830 TrailerRightRearLight 4;
BA_ "SigType" SG_ 2566808830 TrailerRightRearFogLight 4;
BA_ "SigType" SG_ 2566808830 TrailerRightDirIndLight 4;
BA_ "SigType" SG_ 2566808830 TrailerRightCrnMarkerLight 4;
BA_ "SigType" SG_ 2566808830 TrailerRearWarningLight 4;
BA_ "SigType" SG_ 2566808830 TrailerLeftStopLight 4;
BA_ "SigType" SG_ 2565734142 ControlByte 1;
BA_ "SigType" SG_ 2565734142 FilterMode 1;
BA_ "SigType" SG_ 2565144318 ParkingAndTrailerAirPress 1;
BA_ "SigType" SG_ 2565144318 AuxEquipSupplyPressure 1;
BA_ "SigType" SG_ 2565144318 StopLevelChangeReq 4;
BA_ "SigType" SG_ 2565144318 RampLevelStorageReq 4;
BA_ "SigType" SG_ 2565144318 LevelControlReq 4;
BA_ "SigType" SG_ 2565144318 RampLevelReq 4;
BA_ "SigType" SG_ 2565144318 SteeringAxleLockingReq 4;
BA_ "SigType" SG_ 2565144318 LiftAxle2PositionReq 4;
BA_ "SigType" SG_ 2565144318 LiftAxle1PositionReq 4;
BA_ "SigType" SG_ 2565144318 TractionHelpReq 4;
BA_ "SigType" SG_ 2565144318 LevelChangeReqRearAxle 4;
BA_ "SigType" SG_ 2565144318 LevelChangeReqFrontAxle 4;
BA_ "SigType" SG_ 2565144318 RideHeightRequest 4;
BA_ "SigType" SG_ 2565209854 LevelControl 4;
BA_ "SigType" SG_ 2565209854 RampLevel 4;
BA_ "SigType" SG_ 2565209854 NormalLevel 4;
BA_ "SigType" SG_ 2565209854 StopLevelChangeAcknowledge 4;
BA_ "SigType" SG_ 2565209854 LevelChangeRearAxle 4;
BA_ "SigType" SG_ 2565209854 LevelChangeFrontAxle 4;
BA_ "SigType" SG_ 2565209854 RampLevelStorage 4;
BA_ "SigType" SG_ 2565209854 SteeringAxleLocking 4;
BA_ "SPN" SG_ 2565209854 LiftAxle2Pos 1822;
BA_ "SigType" SG_ 2565209854 LiftAxle2Pos 4;
BA_ "SPN" SG_ 2565209854 LiftAxle1Pos 1743;
BA_ "SigType" SG_ 2565209854 LiftAxle1Pos 4;
BA_ "SigType" SG_ 2565209854 RampLevelPosition 4;
BA_ "SigType" SG_ 2565209854 TractionHelp 4;
BA_ "SigType" SG_ 2565209854 LevelCtrlSysRideHeightLevel 4;
BA_ "SigType" SG_ 2566807294 TyreModulePowerSupply 4;
BA_ "SystemSignalLongSymbol" SG_ 2566764798 NOxConvertingCatalystAdsorberCom "NOxConvertingCatalystAdsorberCompleted";
BA_ "SystemSignalLongSymbol" SG_ 2566764798 NOxConvertingCatalystAdsorberEna "NOxConvertingCatalystAdsorberEnabled";
BA_ "SystemSignalLongSymbol" SG_ 2566764798 BoostPressureControlSystemComple "BoostPressureControlSystemCompleted";
BA_ "SPN" SG_ 2566764798 MisfireMonitoringComplete 3152;
BA_ "SPN" SG_ 2566764798 MisfireMonitoringEnabled 3152;
BA_ "SPN" SG_ 2566764798 FuelSystemMonitoringEnabled 3152;
BA_ "SPN" SG_ 2566764798 ComprehensiveComptMonComplete 3152;
BA_ "SPN" SG_ 2566764798 ComprehensiveCompMonEnabled 3152;
BA_ "SPN" SG_ 2566764798 SecondAirSystemMonComplete 3153;
BA_ "SPN" SG_ 2566764798 SecondAirSystemMonEnabled 3153;
BA_ "SPN" SG_ 2566764798 OxygenSensorMonComplete 3154;
BA_ "SPN" SG_ 2566764798 OxygenSensorMonEnabled 3153;
BA_ "SPN" SG_ 2566764798 OxygenSensorHeaterMonComplete 3154;
BA_ "SPN" SG_ 2566764798 OxygenSensorHeaterMonEnabled 3153;
BA_ "SPN" SG_ 2566764798 HeatedCatalystMonComplete 3154;
BA_ "SPN" SG_ 2566764798 HeatedCatalystMonEnabled 3153;
BA_ "SPN" SG_ 2566764798 EvaporativeSystemMonComplete 3154;
BA_ "SPN" SG_ 2566764798 EvaporativeSystemMonEnabled 3153;
BA_ "SPN" SG_ 2566764798 EGRSystemMonitoringComplete 3154;
BA_ "SPN" SG_ 2566764798 EGRSystemMonitoringEnabled 3153;
BA_ "SPN" SG_ 2566764798 ColdStartAidSystemMonComplete 3154;
BA_ "SPN" SG_ 2566764798 ColdStartAidSystemMonEnabled 3153;
BA_ "SPN" SG_ 2566764798 CatalystMonComplete 3153;
BA_ "SPN" SG_ 2566764798 CatalystMonEnabled 3153;
BA_ "SPN" SG_ 2566764798 ACSystemRefrigerantMonComplete 3153;
BA_ "SPN" SG_ 2566764798 ACSystemRefrigerantMonEnabled 3153;
BA_ "SPN" SG_ 2566764798 FuelSystemMonitoringComplete 3152;
BA_ "SPN" SG_ 2566764798 NumOfWarmUpsSinceDTCsCleared 3151;
BA_ "SPN" SG_ 2566764798 TimeSinceEngineStart 3150;
BA_ "SPN" SG_ 2564095742 SecurityEntityLengthHigh 1596;
BA_ "SPN" SG_ 2564095742 SecurityEntityType 1479;
BA_ "SPN" SG_ 2564095742 SecurityEntityLength 1596;
BA_ "SPN" SG_ 2349137662 XBRMessageChecksum 3188;
BA_ "SigType" SG_ 2349137662 XBRMessageChecksum 4;
BA_ "SPN" SG_ 2349137662 XBRMessageCounter 3189;
BA_ "SigType" SG_ 2349137662 XBRMessageCounter 4;
BA_ "SPN" SG_ 2349137662 XBRCtrlMode 2916;
BA_ "SigType" SG_ 2349137662 XBRCtrlMode 4;
BA_ "SPN" SG_ 2349137662 XBRPriority 2915;
BA_ "SigType" SG_ 2349137662 XBRPriority 4;
BA_ "SPN" SG_ 2349137662 XBREBIMode 2914;
BA_ "SigType" SG_ 2349137662 XBREBIMode 4;
BA_ "SPN" SG_ 2349137662 ExtlAccelerationDemand 2920;
BA_ "SigType" SG_ 2349137662 ExtlAccelerationDemand 1;
BA_ "SPN" SG_ 2349137662 XBRUrgency 4099;
BA_ "SigType" SG_ 2349137662 XBRUrgency 1;
BA_ "SPN" SG_ 2566848510 WaterInFuelIndicator 97;
BA_ "SigType" SG_ 2566848510 WaterInFuelIndicator 4;
BA_ "SPN" SG_ 2566843134 AxleLocation 928;
BA_ "SigType" SG_ 2566843134 AxleLocation 1;
BA_ "SPN" SG_ 2566843134 CargoWeight_30 522230;
BA_ "SigType" SG_ 2566843134 CargoWeight_30 1;
BA_ "SPN" SG_ 2566843134 CargoWeight_20 522220;
BA_ "SigType" SG_ 2566843134 CargoWeight_20 1;
BA_ "SPN" SG_ 2566843134 CargoWeight_10 522210;
BA_ "SigType" SG_ 2566843134 CargoWeight_10 1;
BA_ "SPN" SG_ 2566843134 CargoWeight_00 522200;
BA_ "SigType" SG_ 2566843134 CargoWeight_00 1;
BA_ "SPN" SG_ 2566843134 TrailerWeight_30 522130;
BA_ "SigType" SG_ 2566843134 TrailerWeight_30 1;
BA_ "SPN" SG_ 2566843134 TrailerWeight_20 522120;
BA_ "SigType" SG_ 2566843134 TrailerWeight_20 1;
BA_ "SPN" SG_ 2566843134 TrailerWeight_10 522110;
BA_ "SigType" SG_ 2566843134 TrailerWeight_10 1;
BA_ "SPN" SG_ 2566843134 TrailerWeight_00 522100;
BA_ "SigType" SG_ 2566843134 TrailerWeight_00 1;
BA_ "SPN" SG_ 2566843134 AxleWeight_30 522030;
BA_ "SigType" SG_ 2566843134 AxleWeight_30 1;
BA_ "SPN" SG_ 2566843134 AxleWeight_20 522020;
BA_ "SigType" SG_ 2566843134 AxleWeight_20 1;
BA_ "SPN" SG_ 2566843134 AxleWeight_10 522010;
BA_ "SigType" SG_ 2566843134 AxleWeight_10 1;
BA_ "SPN" SG_ 2566843134 AxleWeight_00 522000;
BA_ "SigType" SG_ 2566843134 AxleWeight_00 1;
BA_ "SPN" SG_ 2566804222 NetBatteryCurrentHiRes 2579;
BA_ "SigType" SG_ 2566804222 NetBatteryCurrentHiRes 1;
BA_ "SPN" SG_ 2566804222 AltCurrentHiRes 1795;
BA_ "SigType" SG_ 2566804222 AltCurrentHiRes 1;
BA_ "SPN" SG_ 2633928190 ECUPowerOutputSupplyVoltage3 3599;
BA_ "SigType" SG_ 2633928190 ECUPowerOutputSupplyVoltage3 1;
BA_ "SPN" SG_ 2633928190 ECUPowerOutputSupplyVoltage2 3598;
BA_ "SigType" SG_ 2633928190 ECUPowerOutputSupplyVoltage2 1;
BA_ "SPN" SG_ 2633928190 ECUPowerOutputSupplyVoltage1 3597;
BA_ "SigType" SG_ 2633928190 ECUPowerOutputSupplyVoltage1 1;
BA_ "SPN" SG_ 2633928190 BatteryPotential_PowerInput2 444;
BA_ "SigType" SG_ 2633928190 BatteryPotential_PowerInput2 1;
BA_ "SPN" SG_ 2566845438 Longitude 585;
BA_ "SigType" SG_ 2566845438 Longitude 1;
BA_ "SPN" SG_ 2566845438 Latitude 584;
BA_ "SigType" SG_ 2566845438 Latitude 1;
BA_ "SPN" SG_ 2566843646 VehicleIdentificationNumber 237;
BA_ "SigType" SG_ 2566843646 VehicleIdentificationNumber 8;
BA_ "SPN" SG_ 2566842366 TotalPowerTakeoffHours 248;
BA_ "SigType" SG_ 2566842366 TotalPowerTakeoffHours 1;
BA_ "SPN" SG_ 2566842366 TotalVehicleHours 246;
BA_ "SigType" SG_ 2566842366 TotalVehicleHours 1;
BA_ "SPN" SG_ 2566809854 WinchOilPressSwitch 1857;
BA_ "SigType" SG_ 2566809854 WinchOilPressSwitch 4;
BA_ "SPN" SG_ 2566809854 HydOilLevel 2602;
BA_ "SigType" SG_ 2566809854 HydOilLevel 1;
BA_ "SPN" SG_ 2566809854 HydOilFilterRestrictionSwitch 1713;
BA_ "SigType" SG_ 2566809854 HydOilFilterRestrictionSwitch 4;
BA_ "SPN" SG_ 2566809854 HydTemp 1638;
BA_ "SigType" SG_ 2566809854 HydTemp 1;
BA_ "SPN" SG_ 2566842622 Altitude 580;
BA_ "SigType" SG_ 2566842622 Altitude 1;
BA_ "SPN" SG_ 2566842622 Pitch 583;
BA_ "SigType" SG_ 2566842622 Pitch 1;
BA_ "SPN" SG_ 2566842622 NavigationBasedVehicleSpeed 517;
BA_ "SigType" SG_ 2566842622 NavigationBasedVehicleSpeed 1;
BA_ "SPN" SG_ 2566842622 CompassBearing 165;
BA_ "SigType" SG_ 2566842622 CompassBearing 1;
BA_ "SPN" SG_ 2566832638 HighResolutionTripDistance 918;
BA_ "SigType" SG_ 2566832638 HighResolutionTripDistance 1;
BA_ "SPN" SG_ 2566832638 HghRslutionTotalVehicleDistance 917;
BA_ "SigType" SG_ 2566832638 HghRslutionTotalVehicleDistance 1;
BA_ "SPN" SG_ 2565868030 SteerWheelAngle 1807;
BA_ "SigType" SG_ 2565868030 SteerWheelAngle 1;
BA_ "SPN" SG_ 2565868030 LongitudinalAcceleration 1810;
BA_ "SigType" SG_ 2565868030 LongitudinalAcceleration 1;
BA_ "SPN" SG_ 2565868030 LateralAcceleration 1809;
BA_ "SigType" SG_ 2565868030 LateralAcceleration 1;
BA_ "SPN" SG_ 2565868030 YawRate 1808;
BA_ "SigType" SG_ 2565868030 YawRate 1;
BA_ "SPN" SG_ 2565868030 SteerWheelAngleSensorType 1812;
BA_ "SigType" SG_ 2565868030 SteerWheelAngleSensorType 4;
BA_ "SPN" SG_ 2565868030 SteerWheelTurnCounter 1811;
BA_ "SPN" SG_ 2566803454 YCBrakeCtrlActive 1819;
BA_ "SigType" SG_ 2566803454 YCBrakeCtrlActive 4;
BA_ "SPN" SG_ 2566803454 YCEngCtrlActive 1817;
BA_ "SigType" SG_ 2566803454 YCEngCtrlActive 4;
BA_ "SPN" SG_ 2566803454 ROPBrakeCtrlActive 1818;
BA_ "SigType" SG_ 2566803454 ROPBrakeCtrlActive 4;
BA_ "SPN" SG_ 2566803454 ROPEngCtrlActive 1816;
BA_ "SigType" SG_ 2566803454 ROPEngCtrlActive 4;
BA_ "SPN" SG_ 2566803454 VDCBrakeLightRq 1815;
BA_ "SigType" SG_ 2566803454 VDCBrakeLightRq 4;
BA_ "SPN" SG_ 2566803454 VDCFullyOperational 1814;
BA_ "SigType" SG_ 2566803454 VDCFullyOperational 4;
BA_ "SPN" SG_ 2566803454 VDCInformationSignal 1813;
BA_ "SigType" SG_ 2566803454 VDCInformationSignal 4;
BA_ "SPN" SG_ 2566840574 TotalVehicleDistance 245;
BA_ "SigType" SG_ 2566840574 TotalVehicleDistance 1;
BA_ "SPN" SG_ 2566840574 TripDistance 244;
BA_ "SigType" SG_ 2566840574 TripDistance 1;
BA_ "SPN" SG_ 2633938686 TripCruiseDistance 1019;
BA_ "SigType" SG_ 2633938686 TripCruiseDistance 1;
BA_ "SPN" SG_ 2633938686 TripMaxVehicleSpeed 1018;
BA_ "SigType" SG_ 2633938686 TripMaxVehicleSpeed 1;
BA_ "SPN" SG_ 2633937150 TripAirCompressorOnTime 1038;
BA_ "SigType" SG_ 2633937150 TripAirCompressorOnTime 1;
BA_ "SPN" SG_ 2633937150 TripIdleTime 1037;
BA_ "SigType" SG_ 2633937150 TripIdleTime 1;
BA_ "SPN" SG_ 2633937150 TripEngRunningTime 1036;
BA_ "SigType" SG_ 2633937150 TripEngRunningTime 1;
BA_ "SPN" SG_ 2633937150 TripCruiseTime 1034;
BA_ "SigType" SG_ 2633937150 TripCruiseTime 1;
BA_ "SPN" SG_ 2633937150 TripPTOGovernorTime 1035;
BA_ "SigType" SG_ 2633937150 TripPTOGovernorTime 1;
BA_ "SPN" SG_ 2633938174 TripTimeInDerateByEng 1027;
BA_ "SigType" SG_ 2633938174 TripTimeInDerateByEng 1;
BA_ "SPN" SG_ 2633938174 TripTimeInGearDown 1026;
BA_ "SigType" SG_ 2633938174 TripTimeInGearDown 1;
BA_ "SPN" SG_ 2633938174 TripTimeInTopGear 1025;
BA_ "SigType" SG_ 2633938174 TripTimeInTopGear 1;
BA_ "SPN" SG_ 2633938174 TripTimeInVSL 1024;
BA_ "SigType" SG_ 2633938174 TripTimeInVSL 1;
BA_ "SPN" SG_ 2633938430 TripSuddenDecelerations 1023;
BA_ "SigType" SG_ 2633938430 TripSuddenDecelerations 1;
BA_ "SPN" SG_ 2633938430 TrpNmberOfIdleShutdownOverrides 1022;
BA_ "SigType" SG_ 2633938430 TrpNmberOfIdleShutdownOverrides 1;
BA_ "SPN" SG_ 2633938430 TripNumberOfIdleShutdowns 1021;
BA_ "SigType" SG_ 2633938430 TripNumberOfIdleShutdowns 1;
BA_ "SPN" SG_ 2633938430 TripNumberOfHotShutdowns 1020;
BA_ "SigType" SG_ 2633938430 TripNumberOfHotShutdowns 1;
BA_ "SPN" SG_ 2348875518 MessageCounter 4206;
BA_ "SPN" SG_ 2348875518 ControlPurpose 3350;
BA_ "SPN" SG_ 2348875518 TransmissionRate 3349;
BA_ "SPN" SG_ 2348875518 EngRqedTorque_TorqueLimit 518;
BA_ "SigType" SG_ 2348875518 EngRqedTorque_TorqueLimit 1;
BA_ "SPN" SG_ 2348875518 EngRqedSpeed_SpeedLimit 898;
BA_ "SigType" SG_ 2348875518 EngRqedSpeed_SpeedLimit 1;
BA_ "SPN" SG_ 2348875518 OverrideCtrlModePriority 897;
BA_ "SPN" SG_ 2348875518 EngRqedSpeedCtrlConditions 696;
BA_ "SPN" SG_ 2348875518 EngOverrideCtrlMode 695;
BA_ "SPN" SG_ 2348875518 MessageChecksum 4207;
BA_ "SPN" SG_ 2348875518 EngineRequestedTorqueHiRes 4191;
BA_ "SPN" SG_ 2566766846 TransitRunStatus 3046;
BA_ "SigType" SG_ 2566766846 TransitRunStatus 4;
BA_ "SPN" SG_ 2566766846 VehicleUseStatus 3045;
BA_ "SigType" SG_ 2566766846 VehicleUseStatus 4;
BA_ "SPN" SG_ 2566766846 SilentAlarmStatus 3044;
BA_ "SigType" SG_ 2566766846 SilentAlarmStatus 4;
BA_ "SPN" SG_ 2566766846 PatronCount 3047;
BA_ "SigType" SG_ 2566766846 PatronCount 1;
BA_ "SPN" SG_ 2566766846 TypeOfPassengerCount 3043;
BA_ "SigType" SG_ 2566766846 TypeOfPassengerCount 1;
BA_ "SPN" SG_ 2566765310 FareboxAlarmIdentifier 3181;
BA_ "SPN" SG_ 2566765310 FareboxEmergencyStatus 3179;
BA_ "SigType" SG_ 2566765310 FareboxEmergencyStatus 4;
BA_ "SPN" SG_ 2566765566 TransferSold 3168;
BA_ "SigType" SG_ 2566765566 TransferSold 1;
BA_ "SPN" SG_ 2566765566 RouteNumber 3169;
BA_ "SigType" SG_ 2566765566 RouteNumber 1;
BA_ "SPN" SG_ 2566765566 TransferType 3173;
BA_ "SPN" SG_ 2566765566 TypeOfService 3172;
BA_ "SPN" SG_ 2566765566 InitialFareAgency 3167;
BA_ "SPN" SG_ 2566765566 PassCategory 3166;
BA_ "SigType" SG_ 2566765566 PassCategory 4;
BA_ "SPN" SG_ 2566765566 FareValidity 3165;
BA_ "SigType" SG_ 2566765566 FareValidity 4;
BA_ "SPN" SG_ 2566765566 PaymentDetails 3177;
BA_ "SigType" SG_ 2566765566 PaymentDetails 4;
BA_ "SPN" SG_ 2566765566 TypeOfFare 3176;
BA_ "SigType" SG_ 2566765566 TypeOfFare 4;
BA_ "SPN" SG_ 2566765566 PassengerType 3171;
BA_ "SigType" SG_ 2566765566 PassengerType 4;
BA_ "SPN" SG_ 2566765566 TransactionType 3170;
BA_ "SigType" SG_ 2566765566 TransactionType 4;
BA_ "SPN" SG_ 2566765822 DriversFareboxSecurityCode 3164;
BA_ "SigType" SG_ 2566765822 DriversFareboxSecurityCode 1;
BA_ "SPN" SG_ 2566765822 AssignedBlock 3163;
BA_ "SigType" SG_ 2566765822 AssignedBlock 1;
BA_ "SPN" SG_ 2566765822 AssignedRun 3162;
BA_ "SigType" SG_ 2566765822 AssignedRun 1;
BA_ "SPN" SG_ 2566765822 AssignedRoute 3160;
BA_ "SigType" SG_ 2566765822 AssignedRoute 1;
BA_ "SPN" SG_ 2566765822 PatternNumber 3161;
BA_ "SigType" SG_ 2566765822 PatternNumber 1;
BA_ "SPN" SG_ 2566765822 TripNumber 3159;
BA_ "SigType" SG_ 2566765822 TripNumber 1;
BA_ "SPN" SG_ 2566765822 FarePresets 3175;
BA_ "SigType" SG_ 2566765822 FarePresets 1;
BA_ "SPN" SG_ 2566765822 TripDirection 3174;
BA_ "SigType" SG_ 2566765822 TripDirection 4;
BA_ "SPN" SG_ 2566765822 TripStatus 3180;
BA_ "SPN" SG_ 2566765822 FareboxServiceStatus 3178;
BA_ "SigType" SG_ 2566765822 FareboxServiceStatus 4;
BA_ "SPN" SG_ 2566766078 VehicleID 3085;
BA_ "SigType" SG_ 2566766078 VehicleID 1;
BA_ "SPN" SG_ 2566766078 StrobeActivationCtrlStatus 3082;
BA_ "SigType" SG_ 2566766078 StrobeActivationCtrlStatus 4;
BA_ "SPN" SG_ 2566766078 TransitDoorEnable 3083;
BA_ "SigType" SG_ 2566766078 TransitDoorEnable 4;
BA_ "SPN" SG_ 2566766078 PriorityOfRespSentByEmitter 3084;
BA_ "SigType" SG_ 2566766078 PriorityOfRespSentByEmitter 4;
BA_ "SPN" SG_ 2566766078 IntersectionPreemptionRq_Resp 3079;
BA_ "SigType" SG_ 2566766078 IntersectionPreemptionRq_Resp 4;
BA_ "SPN" SG_ 2566766078 TransitRouteIDUsage 3080;
BA_ "SigType" SG_ 2566766078 TransitRouteIDUsage 4;
BA_ "SPN" SG_ 2566766078 RangeCodeEnable 3081;
BA_ "SigType" SG_ 2566766078 RangeCodeEnable 4;
BA_ "SPN" SG_ 2566766590 NmbrOfBytsInMlpstIdentification 3070;
BA_ "SigType" SG_ 2566766590 NmbrOfBytsInMlpstIdentification 1;
BA_ "SPN" SG_ 2566766334 Agency 3078;
BA_ "SigType" SG_ 2566766334 Agency 1;
BA_ "SPN" SG_ 2566766334 NmbrOfBytsInTrnstAssgndBlckIdntt 3073;
BA_ "SigType" SG_ 2566766334 NmbrOfBytsInTrnstAssgndBlckIdntt 1;
BA_ "SystemSignalLongSymbol" SG_ 2566766334 NmbrOfBytsInTrnstAssgndBlckIdntt "NmbrOfBytsInTrnstAssgndBlckIdntty";
BA_ "SPN" SG_ 2566766334 NmbrOfBytsInTrnstAssgndRnIdntty 3072;
BA_ "SigType" SG_ 2566766334 NmbrOfBytsInTrnstAssgndRnIdntty 1;
BA_ "SPN" SG_ 2566766334 NmbrOfBytsInTrnstAssgndRtIdntty 3071;
BA_ "SigType" SG_ 2566766334 NmbrOfBytsInTrnstAssgndRtIdntty 1;
BA_ "SPN" SG_ 2561605374 ReferenceTirePressSetting_33 521833;
BA_ "SigType" SG_ 2561605374 ReferenceTirePressSetting_33 1;
BA_ "SPN" SG_ 2561605374 ReferenceTirePressSetting_32 521832;
BA_ "SigType" SG_ 2561605374 ReferenceTirePressSetting_32 1;
BA_ "SPN" SG_ 2561605374 ReferenceTirePressSetting_31 521831;
BA_ "SigType" SG_ 2561605374 ReferenceTirePressSetting_31 1;
BA_ "SPN" SG_ 2561605374 ReferenceTirePressSetting_30 521830;
BA_ "SigType" SG_ 2561605374 ReferenceTirePressSetting_30 1;
BA_ "SPN" SG_ 2561605374 ReferenceTirePressSetting_23 521823;
BA_ "SigType" SG_ 2561605374 ReferenceTirePressSetting_23 1;
BA_ "SPN" SG_ 2561605374 ReferenceTirePressSetting_22 521822;
BA_ "SigType" SG_ 2561605374 ReferenceTirePressSetting_22 1;
BA_ "SPN" SG_ 2561605374 ReferenceTirePressSetting_21 521821;
BA_ "SigType" SG_ 2561605374 ReferenceTirePressSetting_21 1;
BA_ "SPN" SG_ 2561605374 ReferenceTirePressSetting_20 521820;
BA_ "SigType" SG_ 2561605374 ReferenceTirePressSetting_20 1;
BA_ "SPN" SG_ 2561605374 ReferenceTirePressSetting_13 521813;
BA_ "SigType" SG_ 2561605374 ReferenceTirePressSetting_13 1;
BA_ "SPN" SG_ 2561605374 ReferenceTirePressSetting_12 521812;
BA_ "SigType" SG_ 2561605374 ReferenceTirePressSetting_12 1;
BA_ "SPN" SG_ 2561605374 ReferenceTirePressSetting_11 521811;
BA_ "SigType" SG_ 2561605374 ReferenceTirePressSetting_11 1;
BA_ "SPN" SG_ 2561605374 ReferenceTirePressSetting_10 521810;
BA_ "SigType" SG_ 2561605374 ReferenceTirePressSetting_10 1;
BA_ "SPN" SG_ 2561605374 ReferenceTirePressSetting_01 521801;
BA_ "SigType" SG_ 2561605374 ReferenceTirePressSetting_01 1;
BA_ "SPN" SG_ 2561605374 ReferenceTirePressSetting_00 521800;
BA_ "SigType" SG_ 2561605374 ReferenceTirePressSetting_00 1;
BA_ "SPN" SG_ 2561605374 TireLocation 3190;
BA_ "SigType" SG_ 2561605374 TireLocation 1;
BA_ "SPN" SG_ 2566765054 ReferenceTirePress_33 521933;
BA_ "SigType" SG_ 2566765054 ReferenceTirePress_33 1;
BA_ "SPN" SG_ 2566765054 ReferenceTirePress_32 521932;
BA_ "SigType" SG_ 2566765054 ReferenceTirePress_32 1;
BA_ "SPN" SG_ 2566765054 ReferenceTirePress_31 521931;
BA_ "SigType" SG_ 2566765054 ReferenceTirePress_31 1;
BA_ "SPN" SG_ 2566765054 ReferenceTirePress_30 521930;
BA_ "SigType" SG_ 2566765054 ReferenceTirePress_30 1;
BA_ "SPN" SG_ 2566765054 ReferenceTirePress_23 521923;
BA_ "SigType" SG_ 2566765054 ReferenceTirePress_23 1;
BA_ "SPN" SG_ 2566765054 ReferenceTirePress_22 521922;
BA_ "SigType" SG_ 2566765054 ReferenceTirePress_22 1;
BA_ "SPN" SG_ 2566765054 ReferenceTirePress_21 521921;
BA_ "SigType" SG_ 2566765054 ReferenceTirePress_21 1;
BA_ "SPN" SG_ 2566765054 ReferenceTirePress_20 521920;
BA_ "SigType" SG_ 2566765054 ReferenceTirePress_20 1;
BA_ "SPN" SG_ 2566765054 ReferenceTirePress_13 521913;
BA_ "SigType" SG_ 2566765054 ReferenceTirePress_13 1;
BA_ "SPN" SG_ 2566765054 ReferenceTirePress_12 521912;
BA_ "SigType" SG_ 2566765054 ReferenceTirePress_12 1;
BA_ "SPN" SG_ 2566765054 ReferenceTirePress_11 521911;
BA_ "SigType" SG_ 2566765054 ReferenceTirePress_11 1;
BA_ "SPN" SG_ 2566765054 ReferenceTirePress_10 521910;
BA_ "SigType" SG_ 2566765054 ReferenceTirePress_10 1;
BA_ "SPN" SG_ 2566765054 ReferenceTirePress_01 521901;
BA_ "SigType" SG_ 2566765054 ReferenceTirePress_01 1;
BA_ "SPN" SG_ 2566765054 ReferenceTirePress_00 521900;
BA_ "SigType" SG_ 2566765054 ReferenceTirePress_00 1;
BA_ "SPN" SG_ 2566765054 TireLocation 3190;
BA_ "SigType" SG_ 2566765054 TireLocation 1;
BA_ "SPN" SG_ 2633923326 SteerChannelTirePress 146;
BA_ "SigType" SG_ 2633923326 SteerChannelTirePress 1;
BA_ "SPN" SG_ 2633923326 DriveChannelTirePress 145;
BA_ "SigType" SG_ 2633923326 DriveChannelTirePress 1;
BA_ "SPN" SG_ 2633923326 TrailerTagPushChannelTirePress 144;
BA_ "SigType" SG_ 2633923326 TrailerTagPushChannelTirePress 1;
BA_ "SPN" SG_ 2633923070 SteerChannelTirePressTarget 143;
BA_ "SigType" SG_ 2633923070 SteerChannelTirePressTarget 1;
BA_ "SPN" SG_ 2633923070 DriveChannelTirePressTarget 142;
BA_ "SigType" SG_ 2633923070 DriveChannelTirePressTarget 1;
BA_ "SPN" SG_ 2633923070 TrlrTgPshChannelTirePressTarget 141;
BA_ "SigType" SG_ 2633923070 TrlrTgPshChannelTirePressTarget 1;
BA_ "SPN" SG_ 2633922814 PCUSupplySolenoidStatus 1474;
BA_ "SigType" SG_ 2633922814 PCUSupplySolenoidStatus 4;
BA_ "SPN" SG_ 2633922814 PCUCtrlSolenoidStatus 1473;
BA_ "SigType" SG_ 2633922814 PCUCtrlSolenoidStatus 4;
BA_ "SPN" SG_ 2633922814 PCUDeflateSolenoidStatus 1472;
BA_ "SigType" SG_ 2633922814 PCUDeflateSolenoidStatus 4;
BA_ "SPN" SG_ 2633922814 TirePressSupplySwitchStatus 1471;
BA_ "SigType" SG_ 2633922814 TirePressSupplySwitchStatus 4;
BA_ "SPN" SG_ 2633922814 PCUSteerSolenoidStatus 1470;
BA_ "SigType" SG_ 2633922814 PCUSteerSolenoidStatus 4;
BA_ "SPN" SG_ 2633922814 PCUDriveSolenoidStatus 1469;
BA_ "SigType" SG_ 2633922814 PCUDriveSolenoidStatus 4;
BA_ "SPN" SG_ 2633922814 DriveChannelMode 1468;
BA_ "SigType" SG_ 2633922814 DriveChannelMode 4;
BA_ "SPN" SG_ 2633922814 Trailer_TagChannelMode 1467;
BA_ "SigType" SG_ 2633922814 Trailer_TagChannelMode 4;
BA_ "SPN" SG_ 2633922814 SteerChannelMode 1466;
BA_ "SigType" SG_ 2633922814 SteerChannelMode 4;
BA_ "SPN" SG_ 2633922814 TirePressCheckInterval 39;
BA_ "SigType" SG_ 2633922814 TirePressCheckInterval 1;
BA_ "SPN" SG_ 2633922814 PCUTrailerTagPushSolenoidStatus 1475;
BA_ "SigType" SG_ 2633922814 PCUTrailerTagPushSolenoidStatus 4;
BA_ "SPN" SG_ 2566845694 TirePressThresholdDetection_13 521613;
BA_ "SPN" SG_ 2566845694 TirePressThresholdDetection_12 521612;
BA_ "SPN" SG_ 2566845694 TirePressThresholdDetection_11 521611;
BA_ "SPN" SG_ 2566845694 TirePressThresholdDetection_10 521610;
BA_ "SPN" SG_ 2566845694 TirePressThresholdDetection_01 521601;
BA_ "SPN" SG_ 2566845694 TirePress_33 521033;
BA_ "SigType" SG_ 2566845694 TirePress_33 1;
BA_ "SPN" SG_ 2566845694 TirePress_32 521032;
BA_ "SigType" SG_ 2566845694 TirePress_32 1;
BA_ "SPN" SG_ 2566845694 TirePress_31 521031;
BA_ "SigType" SG_ 2566845694 TirePress_31 1;
BA_ "SPN" SG_ 2566845694 TirePress_30 521030;
BA_ "SigType" SG_ 2566845694 TirePress_30 1;
BA_ "SPN" SG_ 2566845694 TirePress_23 521023;
BA_ "SigType" SG_ 2566845694 TirePress_23 1;
BA_ "SPN" SG_ 2566845694 TirePress_22 521022;
BA_ "SigType" SG_ 2566845694 TirePress_22 1;
BA_ "SPN" SG_ 2566845694 TirePress_21 521021;
BA_ "SigType" SG_ 2566845694 TirePress_21 1;
BA_ "SPN" SG_ 2566845694 TirePress_20 521020;
BA_ "SigType" SG_ 2566845694 TirePress_20 1;
BA_ "SPN" SG_ 2566845694 TirePress_13 521013;
BA_ "SigType" SG_ 2566845694 TirePress_13 1;
BA_ "SPN" SG_ 2566845694 TirePress_12 521012;
BA_ "SigType" SG_ 2566845694 TirePress_12 1;
BA_ "SPN" SG_ 2566845694 TirePress_11 521011;
BA_ "SigType" SG_ 2566845694 TirePress_11 1;
BA_ "SPN" SG_ 2566845694 TirePress_10 521010;
BA_ "SigType" SG_ 2566845694 TirePress_10 1;
BA_ "SPN" SG_ 2566845694 TireAirLeakageRate_33 521533;
BA_ "SigType" SG_ 2566845694 TireAirLeakageRate_33 1;
BA_ "SPN" SG_ 2566845694 TireAirLeakageRate_32 521532;
BA_ "SigType" SG_ 2566845694 TireAirLeakageRate_32 1;
BA_ "SPN" SG_ 2566845694 TireAirLeakageRate_31 521531;
BA_ "SigType" SG_ 2566845694 TireAirLeakageRate_31 1;
BA_ "SPN" SG_ 2566845694 TireAirLeakageRate_30 521530;
BA_ "SigType" SG_ 2566845694 TireAirLeakageRate_30 1;
BA_ "SPN" SG_ 2566845694 TireAirLeakageRate_23 521523;
BA_ "SigType" SG_ 2566845694 TireAirLeakageRate_23 1;
BA_ "SPN" SG_ 2566845694 TireAirLeakageRate_22 521522;
BA_ "SigType" SG_ 2566845694 TireAirLeakageRate_22 1;
BA_ "SPN" SG_ 2566845694 TireAirLeakageRate_21 521521;
BA_ "SigType" SG_ 2566845694 TireAirLeakageRate_21 1;
BA_ "SPN" SG_ 2566845694 TireAirLeakageRate_20 521520;
BA_ "SigType" SG_ 2566845694 TireAirLeakageRate_20 1;
BA_ "SPN" SG_ 2566845694 TireAirLeakageRate_13 521513;
BA_ "SigType" SG_ 2566845694 TireAirLeakageRate_13 1;
BA_ "SPN" SG_ 2566845694 TireAirLeakageRate_12 521512;
BA_ "SigType" SG_ 2566845694 TireAirLeakageRate_12 1;
BA_ "SPN" SG_ 2566845694 TireAirLeakageRate_11 521511;
BA_ "SigType" SG_ 2566845694 TireAirLeakageRate_11 1;
BA_ "SPN" SG_ 2566845694 TireAirLeakageRate_10 521510;
BA_ "SigType" SG_ 2566845694 TireAirLeakageRate_10 1;
BA_ "SPN" SG_ 2566845694 TireAirLeakageRate_01 521501;
BA_ "SigType" SG_ 2566845694 TireAirLeakageRate_01 1;
BA_ "SPN" SG_ 2566845694 TireAirLeakageRate_00 521500;
BA_ "SigType" SG_ 2566845694 TireAirLeakageRate_00 1;
BA_ "SPN" SG_ 2566845694 CTIWheelSensorStatus_33 521433;
BA_ "SigType" SG_ 2566845694 CTIWheelSensorStatus_33 4;
BA_ "SPN" SG_ 2566845694 CTIWheelSensorStatus_32 521432;
BA_ "SigType" SG_ 2566845694 CTIWheelSensorStatus_32 4;
BA_ "SPN" SG_ 2566845694 CTIWheelSensorStatus_31 521431;
BA_ "SigType" SG_ 2566845694 CTIWheelSensorStatus_31 4;
BA_ "SPN" SG_ 2566845694 CTIWheelSensorStatus_30 521430;
BA_ "SigType" SG_ 2566845694 CTIWheelSensorStatus_30 4;
BA_ "SPN" SG_ 2566845694 CTIWheelSensorStatus_23 521423;
BA_ "SigType" SG_ 2566845694 CTIWheelSensorStatus_23 4;
BA_ "SPN" SG_ 2566845694 CTIWheelSensorStatus_22 521422;
BA_ "SigType" SG_ 2566845694 CTIWheelSensorStatus_22 4;
BA_ "SPN" SG_ 2566845694 CTIWheelSensorStatus_21 521421;
BA_ "SigType" SG_ 2566845694 CTIWheelSensorStatus_21 4;
BA_ "SPN" SG_ 2566845694 CTIWheelSensorStatus_20 521420;
BA_ "SigType" SG_ 2566845694 CTIWheelSensorStatus_20 4;
BA_ "SPN" SG_ 2566845694 CTIWheelSensorStatus_13 521413;
BA_ "SigType" SG_ 2566845694 CTIWheelSensorStatus_13 4;
BA_ "SPN" SG_ 2566845694 CTIWheelSensorStatus_12 521412;
BA_ "SigType" SG_ 2566845694 CTIWheelSensorStatus_12 4;
BA_ "SPN" SG_ 2566845694 CTIWheelSensorStatus_11 521411;
BA_ "SigType" SG_ 2566845694 CTIWheelSensorStatus_11 4;
BA_ "SPN" SG_ 2566845694 CTIWheelSensorStatus_10 521410;
BA_ "SigType" SG_ 2566845694 CTIWheelSensorStatus_10 4;
BA_ "SPN" SG_ 2566845694 CTIWheelSensorStatus_01 521401;
BA_ "SigType" SG_ 2566845694 CTIWheelSensorStatus_01 4;
BA_ "SPN" SG_ 2566845694 CTIWheelEndElectricalFault_33 521233;
BA_ "SigType" SG_ 2566845694 CTIWheelEndElectricalFault_33 4;
BA_ "SPN" SG_ 2566845694 CTIWheelEndElectricalFault_32 521232;
BA_ "SigType" SG_ 2566845694 CTIWheelEndElectricalFault_32 4;
BA_ "SPN" SG_ 2566845694 CTIWheelEndElectricalFault_31 521231;
BA_ "SigType" SG_ 2566845694 CTIWheelEndElectricalFault_31 4;
BA_ "SPN" SG_ 2566845694 CTIWheelEndElectricalFault_30 521230;
BA_ "SigType" SG_ 2566845694 CTIWheelEndElectricalFault_30 4;
BA_ "SPN" SG_ 2566845694 CTIWheelEndElectricalFault_23 521223;
BA_ "SigType" SG_ 2566845694 CTIWheelEndElectricalFault_23 4;
BA_ "SPN" SG_ 2566845694 CTIWheelEndElectricalFault_22 521222;
BA_ "SigType" SG_ 2566845694 CTIWheelEndElectricalFault_22 4;
BA_ "SPN" SG_ 2566845694 CTIWheelEndElectricalFault_21 521221;
BA_ "SigType" SG_ 2566845694 CTIWheelEndElectricalFault_21 4;
BA_ "SPN" SG_ 2566845694 CTIWheelEndElectricalFault_20 521220;
BA_ "SigType" SG_ 2566845694 CTIWheelEndElectricalFault_20 4;
BA_ "SPN" SG_ 2566845694 CTIWheelEndElectricalFault_13 521213;
BA_ "SigType" SG_ 2566845694 CTIWheelEndElectricalFault_13 4;
BA_ "SPN" SG_ 2566845694 CTIWheelEndElectricalFault_12 521212;
BA_ "SigType" SG_ 2566845694 CTIWheelEndElectricalFault_12 4;
BA_ "SPN" SG_ 2566845694 CTIWheelEndElectricalFault_11 521211;
BA_ "SigType" SG_ 2566845694 CTIWheelEndElectricalFault_11 4;
BA_ "SPN" SG_ 2566845694 CTIWheelEndElectricalFault_10 521210;
BA_ "SigType" SG_ 2566845694 CTIWheelEndElectricalFault_10 4;
BA_ "SPN" SG_ 2566845694 CTIWheelEndElectricalFault_01 521201;
BA_ "SigType" SG_ 2566845694 CTIWheelEndElectricalFault_01 4;
BA_ "SPN" SG_ 2566845694 CTITireStatus_33 521333;
BA_ "SigType" SG_ 2566845694 CTITireStatus_33 4;
BA_ "SPN" SG_ 2566845694 CTITireStatus_32 521332;
BA_ "SigType" SG_ 2566845694 CTITireStatus_32 4;
BA_ "SPN" SG_ 2566845694 CTITireStatus_31 521331;
BA_ "SigType" SG_ 2566845694 CTITireStatus_31 4;
BA_ "SPN" SG_ 2566845694 CTITireStatus_30 521330;
BA_ "SigType" SG_ 2566845694 CTITireStatus_30 4;
BA_ "SPN" SG_ 2566845694 CTITireStatus_23 521323;
BA_ "SigType" SG_ 2566845694 CTITireStatus_23 4;
BA_ "SPN" SG_ 2566845694 CTITireStatus_22 521322;
BA_ "SigType" SG_ 2566845694 CTITireStatus_22 4;
BA_ "SPN" SG_ 2566845694 CTITireStatus_21 521321;
BA_ "SigType" SG_ 2566845694 CTITireStatus_21 4;
BA_ "SPN" SG_ 2566845694 CTITireStatus_20 521320;
BA_ "SigType" SG_ 2566845694 CTITireStatus_20 4;
BA_ "SPN" SG_ 2566845694 CTITireStatus_13 521313;
BA_ "SigType" SG_ 2566845694 CTITireStatus_13 4;
BA_ "SPN" SG_ 2566845694 CTITireStatus_12 521312;
BA_ "SigType" SG_ 2566845694 CTITireStatus_12 4;
BA_ "SPN" SG_ 2566845694 CTITireStatus_11 521311;
BA_ "SigType" SG_ 2566845694 CTITireStatus_11 4;
BA_ "SPN" SG_ 2566845694 CTITireStatus_10 521310;
BA_ "SigType" SG_ 2566845694 CTITireStatus_10 4;
BA_ "SPN" SG_ 2566845694 CTITireStatus_01 521301;
BA_ "SigType" SG_ 2566845694 CTITireStatus_01 4;
BA_ "SPN" SG_ 2566845694 TireTemp_11 521111;
BA_ "SigType" SG_ 2566845694 TireTemp_11 1;
BA_ "SPN" SG_ 2566845694 TireTemp_33 521133;
BA_ "SigType" SG_ 2566845694 TireTemp_33 1;
BA_ "SPN" SG_ 2566845694 TireTemp_32 521132;
BA_ "SigType" SG_ 2566845694 TireTemp_32 1;
BA_ "SPN" SG_ 2566845694 TireTemp_31 521131;
BA_ "SigType" SG_ 2566845694 TireTemp_31 1;
BA_ "SPN" SG_ 2566845694 TireTemp_30 521130;
BA_ "SigType" SG_ 2566845694 TireTemp_30 1;
BA_ "SPN" SG_ 2566845694 TireTemp_23 521123;
BA_ "SigType" SG_ 2566845694 TireTemp_23 1;
BA_ "SPN" SG_ 2566845694 TireTemp_22 521122;
BA_ "SigType" SG_ 2566845694 TireTemp_22 1;
BA_ "SPN" SG_ 2566845694 TireTemp_21 521121;
BA_ "SigType" SG_ 2566845694 TireTemp_21 1;
BA_ "SPN" SG_ 2566845694 TireTemp_20 521120;
BA_ "SigType" SG_ 2566845694 TireTemp_20 1;
BA_ "SPN" SG_ 2566845694 TireTemp_13 521113;
BA_ "SigType" SG_ 2566845694 TireTemp_13 1;
BA_ "SPN" SG_ 2566845694 TireTemp_12 521112;
BA_ "SigType" SG_ 2566845694 TireTemp_12 1;
BA_ "SPN" SG_ 2566845694 TireTemp_10 521110;
BA_ "SigType" SG_ 2566845694 TireTemp_10 1;
BA_ "SPN" SG_ 2566845694 TireTemp_01 521101;
BA_ "SigType" SG_ 2566845694 TireTemp_01 1;
BA_ "SPN" SG_ 2566845694 TireTemp_00 521100;
BA_ "SigType" SG_ 2566845694 TireTemp_00 1;
BA_ "SPN" SG_ 2566845694 TirePressThresholdDetection_33 521633;
BA_ "SPN" SG_ 2566845694 TirePressThresholdDetection_32 521632;
BA_ "SPN" SG_ 2566845694 TirePressThresholdDetection_31 521631;
BA_ "SPN" SG_ 2566845694 TirePressThresholdDetection_30 521630;
BA_ "SPN" SG_ 2566845694 TirePressThresholdDetection_23 521623;
BA_ "SPN" SG_ 2566845694 TirePressThresholdDetection_22 521622;
BA_ "SPN" SG_ 2566845694 TirePressThresholdDetection_21 521621;
BA_ "SPN" SG_ 2566845694 TirePressThresholdDetection_20 521620;
BA_ "SPN" SG_ 2566845694 TirePressThresholdDetection_00 521600;
BA_ "SPN" SG_ 2566845694 TirePress_01 521001;
BA_ "SigType" SG_ 2566845694 TirePress_01 1;
BA_ "SPN" SG_ 2566845694 TirePress_00 521000;
BA_ "SigType" SG_ 2566845694 TirePress_00 1;
BA_ "SPN" SG_ 2566845694 CTIWheelSensorStatus_00 521400;
BA_ "SigType" SG_ 2566845694 CTIWheelSensorStatus_00 4;
BA_ "SPN" SG_ 2566845694 CTIWheelEndElectricalFault_00 521200;
BA_ "SigType" SG_ 2566845694 CTIWheelEndElectricalFault_00 4;
BA_ "SPN" SG_ 2566845694 CTITireStatus_00 521300;
BA_ "SigType" SG_ 2566845694 CTITireStatus_00 4;
BA_ "SPN" SG_ 2566845694 TireLocation 929;
BA_ "SigType" SG_ 2566845694 TireLocation 1;
BA_ "SPN" SG_ 2633939966 TripFanOnTimeDueToAManualSwitch 996;
BA_ "SigType" SG_ 2633939966 TripFanOnTimeDueToAManualSwitch 1;
BA_ "SPN" SG_ 2633939966 TripFanOnTime 994;
BA_ "SigType" SG_ 2633939966 TripFanOnTime 1;
BA_ "SPN" SG_ 2633939966 TripFanOnTimeDueToA_CSystem 997;
BA_ "SigType" SG_ 2633939966 TripFanOnTimeDueToA_CSystem 1;
BA_ "SPN" SG_ 2633939966 TripFanOnTimeDueToEngSystem 995;
BA_ "SigType" SG_ 2633939966 TripFanOnTimeDueToEngSystem 1;
BA_ "SPN" SG_ 2633939710 TripDistanceInTopGear 1000;
BA_ "SigType" SG_ 2633939710 TripDistanceInTopGear 1;
BA_ "SPN" SG_ 2633939710 TripGearDownDistance 999;
BA_ "SigType" SG_ 2633939710 TripGearDownDistance 1;
BA_ "SPN" SG_ 2633939710 TripDistanceOnVSL 998;
BA_ "SigType" SG_ 2633939710 TripDistanceOnVSL 1;
BA_ "SPN" SG_ 2564161278 AdjustLocalHourOffset 1610;
BA_ "SigType" SG_ 2564161278 AdjustLocalHourOffset 1;
BA_ "SPN" SG_ 2564161278 AdjustLocalMinuteOffset 1609;
BA_ "SigType" SG_ 2564161278 AdjustLocalMinuteOffset 1;
BA_ "SPN" SG_ 2564161278 AdjustYear 1608;
BA_ "SigType" SG_ 2564161278 AdjustYear 1;
BA_ "SPN" SG_ 2564161278 AdjustDay 1607;
BA_ "SigType" SG_ 2564161278 AdjustDay 1;
BA_ "SPN" SG_ 2564161278 AdjustMonth 1606;
BA_ "SigType" SG_ 2564161278 AdjustMonth 1;
BA_ "SPN" SG_ 2564161278 AdjustHours 1605;
BA_ "SigType" SG_ 2564161278 AdjustHours 1;
BA_ "SPN" SG_ 2564161278 AdjustMinutes 1604;
BA_ "SigType" SG_ 2564161278 AdjustMinutes 1;
BA_ "SPN" SG_ 2564161278 AdjustSeconds 1603;
BA_ "SigType" SG_ 2564161278 AdjustSeconds 1;
BA_ "SPN" SG_ 2566842110 LocalHourOffset 1602;
BA_ "SigType" SG_ 2566842110 LocalHourOffset 1;
BA_ "SPN" SG_ 2566842110 LocalMinuteOffset 1601;
BA_ "SigType" SG_ 2566842110 LocalMinuteOffset 1;
BA_ "SPN" SG_ 2566842110 Year 964;
BA_ "SigType" SG_ 2566842110 Year 1;
BA_ "SPN" SG_ 2566842110 Day 962;
BA_ "SigType" SG_ 2566842110 Day 1;
BA_ "SPN" SG_ 2566842110 Month 963;
BA_ "SigType" SG_ 2566842110 Month 1;
BA_ "SPN" SG_ 2566842110 Hours 961;
BA_ "SigType" SG_ 2566842110 Hours 1;
BA_ "SPN" SG_ 2566842110 Minutes 960;
BA_ "SigType" SG_ 2566842110 Minutes 1;
BA_ "SPN" SG_ 2566842110 Seconds 959;
BA_ "SigType" SG_ 2566842110 Seconds 1;
BA_ "SPN" SG_ 2566821630 EngTrbWstgteActuator1TempStatus 5372;
BA_ "SigType" SG_ 2566821630 EngTrbWstgteActuator1TempStatus 4;
BA_ "SPN" SG_ 2566821630 EngTrbWstgtActtr1PreliminaryFMI 5371;
BA_ "SigType" SG_ 2566821630 EngTrbWstgtActtr1PreliminaryFMI 1;
BA_ "SPN" SG_ 2566821630 EngDsrdTrbWastegateActuator2Pos 5373;
BA_ "SigType" SG_ 2566821630 EngDsrdTrbWastegateActuator2Pos 1;
BA_ "SPN" SG_ 2566821630 EngDsrdTrbWastegateActuator1Pos 5370;
BA_ "SigType" SG_ 2566821630 EngDsrdTrbWastegateActuator1Pos 1;
BA_ "SPN" SG_ 2566821630 EngTurboWastegateActuator4Pos 1191;
BA_ "SigType" SG_ 2566821630 EngTurboWastegateActuator4Pos 1;
BA_ "SPN" SG_ 2566821630 EngTurboWastegateActuator3Pos 1190;
BA_ "SigType" SG_ 2566821630 EngTurboWastegateActuator3Pos 1;
BA_ "SPN" SG_ 2566821630 EngTurboWastegateActuator2Pos 1189;
BA_ "SigType" SG_ 2566821630 EngTurboWastegateActuator2Pos 1;
BA_ "SPN" SG_ 2566821630 EngTurboWastegateActuator1Pos 1188;
BA_ "SigType" SG_ 2566821630 EngTurboWastegateActuator1Pos 1;
BA_ "SPN" SG_ 2566821630 EngTrbWstgtActuatorCtrlAirPress 1192;
BA_ "SigType" SG_ 2566821630 EngTrbWstgtActuatorCtrlAirPress 1;
BA_ "SPN" SG_ 2365484286 VehicleOverspeed 1614;
BA_ "SigType" SG_ 2365484286 VehicleOverspeed 4;
BA_ "SPN" SG_ 2365484286 VehicleMotion 1611;
BA_ "SigType" SG_ 2365484286 VehicleMotion 4;
BA_ "SPN" SG_ 2365484286 TachographVehicleSpeed 1624;
BA_ "SigType" SG_ 2365484286 TachographVehicleSpeed 1;
BA_ "SPN" SG_ 2365484286 TachographOutputShaftSpeed 1623;
BA_ "SigType" SG_ 2365484286 TachographOutputShaftSpeed 1;
BA_ "SPN" SG_ 2365484286 DirectionIndicator 1619;
BA_ "SigType" SG_ 2365484286 DirectionIndicator 4;
BA_ "SPN" SG_ 2365484286 TachographPerformance 1620;
BA_ "SigType" SG_ 2365484286 TachographPerformance 4;
BA_ "SPN" SG_ 2365484286 HandlingInformation 1621;
BA_ "SigType" SG_ 2365484286 HandlingInformation 4;
BA_ "SPN" SG_ 2365484286 SystemEvent 1622;
BA_ "SigType" SG_ 2365484286 SystemEvent 4;
BA_ "SPN" SG_ 2365484286 DriverCardDriver2 1616;
BA_ "SigType" SG_ 2365484286 DriverCardDriver2 4;
BA_ "SPN" SG_ 2365484286 Driver2TimeRelatedStates 1618;
BA_ "SigType" SG_ 2365484286 Driver2TimeRelatedStates 4;
BA_ "SPN" SG_ 2365484286 DriverCardDriver1 1615;
BA_ "SigType" SG_ 2365484286 DriverCardDriver1 4;
BA_ "SPN" SG_ 2365484286 Driver1TimeRelatedStates 1617;
BA_ "SigType" SG_ 2365484286 Driver1TimeRelatedStates 4;
BA_ "SPN" SG_ 2365484286 Driver2WorkingState 1613;
BA_ "SPN" SG_ 2365484286 Driver1WorkingState 1612;
BA_ "SPN" SG_ 2566771710 EngTurbo4CompressorOutletTemp 2801;
BA_ "SigType" SG_ 2566771710 EngTurbo4CompressorOutletTemp 1;
BA_ "SPN" SG_ 2566771710 EngTurbo3CompressorOutletTemp 2800;
BA_ "SigType" SG_ 2566771710 EngTurbo3CompressorOutletTemp 1;
BA_ "SPN" SG_ 2566771710 EngTurbo2CompressorOutletTemp 2799;
BA_ "SigType" SG_ 2566771710 EngTurbo2CompressorOutletTemp 1;
BA_ "SPN" SG_ 2566771710 EngTurbo1CompressorOutletTemp 2629;
BA_ "SigType" SG_ 2566771710 EngTurbo1CompressorOutletTemp 1;
BA_ "SPN" SG_ 2566821886 EngTurbo4TurbineOutletTemp 1187;
BA_ "SigType" SG_ 2566821886 EngTurbo4TurbineOutletTemp 1;
BA_ "SPN" SG_ 2566821886 EngTurbo3TurbineOutletTemp 1186;
BA_ "SigType" SG_ 2566821886 EngTurbo3TurbineOutletTemp 1;
BA_ "SPN" SG_ 2566821886 EngTurbo2TurbineOutletTemp 1185;
BA_ "SigType" SG_ 2566821886 EngTurbo2TurbineOutletTemp 1;
BA_ "SPN" SG_ 2566821886 EngTurbo1TurbineOutletTemp 1184;
BA_ "SigType" SG_ 2566821886 EngTurbo1TurbineOutletTemp 1;
BA_ "SPN" SG_ 2566822142 EngTurbo4TurbineIntakeTemp 1183;
BA_ "SigType" SG_ 2566822142 EngTurbo4TurbineIntakeTemp 1;
BA_ "SPN" SG_ 2566822142 EngTurbo3TurbineIntakeTemp 1182;
BA_ "SigType" SG_ 2566822142 EngTurbo3TurbineIntakeTemp 1;
BA_ "SPN" SG_ 2566822142 EngTurbo2TurbineIntakeTemp 1181;
BA_ "SigType" SG_ 2566822142 EngTurbo2TurbineIntakeTemp 1;
BA_ "SPN" SG_ 2566822142 EngTurbo1TurbineIntakeTemp 1180;
BA_ "SigType" SG_ 2566822142 EngTurbo1TurbineIntakeTemp 1;
BA_ "SPN" SG_ 2566822398 EngTurbo4CompressorIntakePress 1179;
BA_ "SigType" SG_ 2566822398 EngTurbo4CompressorIntakePress 1;
BA_ "SPN" SG_ 2566822398 EngTurbo3CompressorIntakePress 1178;
BA_ "SigType" SG_ 2566822398 EngTurbo3CompressorIntakePress 1;
BA_ "SPN" SG_ 2566822398 EngTurbo2CompressorIntakePress 1177;
BA_ "SigType" SG_ 2566822398 EngTurbo2CompressorIntakePress 1;
BA_ "SPN" SG_ 2566822398 EngTurbo1CompressorIntakePress 1176;
BA_ "SigType" SG_ 2566822398 EngTurbo1CompressorIntakePress 1;
BA_ "SPN" SG_ 2566822654 EngTurbo4CompressorIntakeTemp 1175;
BA_ "SigType" SG_ 2566822654 EngTurbo4CompressorIntakeTemp 1;
BA_ "SPN" SG_ 2566822654 EngTurbo3CompressorIntakeTemp 1174;
BA_ "SigType" SG_ 2566822654 EngTurbo3CompressorIntakeTemp 1;
BA_ "SPN" SG_ 2566822654 EngTurbo2CompressorIntakeTemp 1173;
BA_ "SigType" SG_ 2566822654 EngTurbo2CompressorIntakeTemp 1;
BA_ "SPN" SG_ 2566822654 EngTurbo1CompressorIntakeTemp 1172;
BA_ "SigType" SG_ 2566822654 EngTurbo1CompressorIntakeTemp 1;
BA_ "SPN" SG_ 2633931774 EngTurbo4Speed 1171;
BA_ "SigType" SG_ 2633931774 EngTurbo4Speed 1;
BA_ "SPN" SG_ 2633931774 EngTurbo3Speed 1170;
BA_ "SigType" SG_ 2633931774 EngTurbo3Speed 1;
BA_ "SPN" SG_ 2633931774 EngTurbo2Speed 1169;
BA_ "SigType" SG_ 2633931774 EngTurbo2Speed 1;
BA_ "SPN" SG_ 2633931774 EngTurboLubeOilPress2 1168;
BA_ "SigType" SG_ 2633931774 EngTurboLubeOilPress2 1;
BA_ "SPN" SG_ 2566802430 TransTorqueLimit 1845;
BA_ "SigType" SG_ 2566802430 TransTorqueLimit 1;
BA_ "SPN" SG_ 2566841086 TransGearRatio 581;
BA_ "SigType" SG_ 2566841086 TransGearRatio 1;
BA_ "SPN" SG_ 2566841086 NumberOfForwardGearRatios 957;
BA_ "SigType" SG_ 2566841086 NumberOfForwardGearRatios 1;
BA_ "SPN" SG_ 2566841086 NumberOfReverseGearRatios 958;
BA_ "SigType" SG_ 2566841086 NumberOfReverseGearRatios 1;
BA_ "SPN" SG_ 2348941054 TrnsShftSlctorDisplayModeSwitch 2985;
BA_ "SigType" SG_ 2348941054 TrnsShftSlctorDisplayModeSwitch 4;
BA_ "SPN" SG_ 2348941054 TransMode4 1855;
BA_ "SigType" SG_ 2348941054 TransMode4 4;
BA_ "SPN" SG_ 2348941054 TransMode3 1854;
BA_ "SigType" SG_ 2348941054 TransMode3 4;
BA_ "SPN" SG_ 2348941054 TransMode2 1853;
BA_ "SigType" SG_ 2348941054 TransMode2 4;
BA_ "SPN" SG_ 2348941054 TransMode1 1852;
BA_ "SigType" SG_ 2348941054 TransMode1 4;
BA_ "SPN" SG_ 2348941054 DisengageDiffLockRqCentralRear 691;
BA_ "SigType" SG_ 2348941054 DisengageDiffLockRqCentralRear 4;
BA_ "SPN" SG_ 2348941054 DisengageDiffLockRqCentralFront 690;
BA_ "SigType" SG_ 2348941054 DisengageDiffLockRqCentralFront 4;
BA_ "SPN" SG_ 2348941054 DisengageDiffLockRqCentral 689;
BA_ "SigType" SG_ 2348941054 DisengageDiffLockRqCentral 4;
BA_ "SPN" SG_ 2348941054 DisengageDiffLockRqRearAxle2 688;
BA_ "SigType" SG_ 2348941054 DisengageDiffLockRqRearAxle2 4;
BA_ "SPN" SG_ 2348941054 DisengageDiffLockRqRearAxle1 687;
BA_ "SigType" SG_ 2348941054 DisengageDiffLockRqRearAxle1 4;
BA_ "SPN" SG_ 2348941054 DisengageDiffLockRqFrontAxle2 686;
BA_ "SigType" SG_ 2348941054 DisengageDiffLockRqFrontAxle2 4;
BA_ "SPN" SG_ 2348941054 DisengageDiffLockRqFrontAxle1 685;
BA_ "SigType" SG_ 2348941054 DisengageDiffLockRqFrontAxle1 4;
BA_ "SPN" SG_ 2348941054 TransRqedGear 525;
BA_ "SigType" SG_ 2348941054 TransRqedGear 1;
BA_ "SPN" SG_ 2348941054 RqedPercentClutchSlip 684;
BA_ "SigType" SG_ 2348941054 RqedPercentClutchSlip 1;
BA_ "SPN" SG_ 2348941054 DisengageDrivelineRq 683;
BA_ "SigType" SG_ 2348941054 DisengageDrivelineRq 4;
BA_ "SPN" SG_ 2348941054 TransGearShiftInhibitRq 681;
BA_ "SigType" SG_ 2348941054 TransGearShiftInhibitRq 4;
BA_ "SPN" SG_ 2348941054 TrnsTrqConverterLockupDisableRq 682;
BA_ "SigType" SG_ 2348941054 TrnsTrqConverterLockupDisableRq 4;
BA_ "SPN" SG_ 2348941054 TransRqedLaunchGear 4255;
BA_ "SigType" SG_ 2348941054 TransRqedLaunchGear 4;
BA_ "SPN" SG_ 2348941054 TransReverseGearShiftInhibitRq 4242;
BA_ "SigType" SG_ 2348941054 TransReverseGearShiftInhibitRq 4;
BA_ "SPN" SG_ 2348941054 TransMode8 4249;
BA_ "SigType" SG_ 2348941054 TransMode8 4;
BA_ "SPN" SG_ 2348941054 TransMode7 4248;
BA_ "SigType" SG_ 2348941054 TransMode7 4;
BA_ "SPN" SG_ 2348941054 TransMode6 4247;
BA_ "SigType" SG_ 2348941054 TransMode6 4;
BA_ "SPN" SG_ 2348941054 TransMode5 4246;
BA_ "SigType" SG_ 2348941054 TransMode5 4;
BA_ "SPN" SG_ 2566839806 EngTurboOilLevelSwitch 1665;
BA_ "SigType" SG_ 2566839806 EngTurboOilLevelSwitch 4;
BA_ "SPN" SG_ 2566839806 EngTurbo1Speed 103;
BA_ "SigType" SG_ 2566839806 EngTurbo1Speed 1;
BA_ "SPN" SG_ 2566839806 EngTurboLubeOilPress1 104;
BA_ "SigType" SG_ 2566839806 EngTurboLubeOilPress1 1;
BA_ "SPN" SG_ 2633911806 EngTotalAverageFuelEconomy 1835;
BA_ "SigType" SG_ 2633911806 EngTotalAverageFuelEconomy 1;
BA_ "SPN" SG_ 2633911806 EngTotalAverageFuelRate 1834;
BA_ "SigType" SG_ 2633911806 EngTotalAverageFuelRate 1;
BA_ "SPN" SG_ 2566775550 AirSuspensionSupplyPressRq 2608;
BA_ "SigType" SG_ 2566775550 AirSuspensionSupplyPressRq 1;
BA_ "SPN" SG_ 2566775550 AuxEquipmentSupplyPressRq 2607;
BA_ "SigType" SG_ 2566775550 AuxEquipmentSupplyPressRq 1;
BA_ "SPN" SG_ 2566775550 ServiceBrakeAirPressRqCircuit2 2606;
BA_ "SigType" SG_ 2566775550 ServiceBrakeAirPressRqCircuit2 1;
BA_ "SPN" SG_ 2566775550 ServiceBrakeAirPressRqCircuit1 2605;
BA_ "SigType" SG_ 2566775550 ServiceBrakeAirPressRqCircuit1 1;
BA_ "SPN" SG_ 2566775550 ParkingAnd_OrTrailerAirPressRq 2604;
BA_ "SigType" SG_ 2566775550 ParkingAnd_OrTrailerAirPressRq 1;
BA_ "SPN" SG_ 2566775550 PneumaticSupplyPressRq 2603;
BA_ "SigType" SG_ 2566775550 PneumaticSupplyPressRq 1;
BA_ "SPN" SG_ 2566819838 EngExtlShutdownAirSupplyPress 1320;
BA_ "SigType" SG_ 2566819838 EngExtlShutdownAirSupplyPress 1;
BA_ "SPN" SG_ 2566839038 NmbrOfSftwrIdentificationFields 965;
BA_ "SigType" SG_ 2566839038 NmbrOfSftwrIdentificationFields 1;
BA_ "SPN" SG_ 2566839038 SoftwareID3 234;
BA_ "SigType" SG_ 2566839038 SoftwareID3 8;
BA_ "SPN" SG_ 2566839038 SoftwareID2 234;
BA_ "SigType" SG_ 2566839038 SoftwareID2 8;
BA_ "SPN" SG_ 2566839038 SoftwareID1 234;
BA_ "SigType" SG_ 2566839038 SoftwareID1 8;
BA_ "SPN" SG_ 2566841598 EngOverspeedTest 2812;
BA_ "SigType" SG_ 2566841598 EngOverspeedTest 4;
BA_ "SPN" SG_ 2566841598 EngAirShutoffCmdStatus 2813;
BA_ "SigType" SG_ 2566841598 EngAirShutoffCmdStatus 4;
BA_ "SPN" SG_ 2566841598 EngAlarmOutputCmdStatus 2814;
BA_ "SigType" SG_ 2566841598 EngAlarmOutputCmdStatus 4;
BA_ "SPN" SG_ 2566841598 EngAlarmAcknowledge 2815;
BA_ "SigType" SG_ 2566841598 EngAlarmAcknowledge 4;
BA_ "SPN" SG_ 2566841598 EngProtectionSystemConfig 1111;
BA_ "SigType" SG_ 2566841598 EngProtectionSystemConfig 4;
BA_ "SPN" SG_ 2566841598 EngProtectionSystemTimerState 1107;
BA_ "SigType" SG_ 2566841598 EngProtectionSystemTimerState 4;
BA_ "SPN" SG_ 2566841598 EngPrtectionSystemTimerOverride 1108;
BA_ "SigType" SG_ 2566841598 EngPrtectionSystemTimerOverride 4;
BA_ "SPN" SG_ 2566841598 EngPrtctnSystmApprchingShutdown 1109;
BA_ "SigType" SG_ 2566841598 EngPrtctnSystmApprchingShutdown 4;
BA_ "SPN" SG_ 2566841598 EngWaitToStartLamp 1081;
BA_ "SigType" SG_ 2566841598 EngWaitToStartLamp 4;
BA_ "SPN" SG_ 2566841598 RefrigerantHighPressSwitch 605;
BA_ "SigType" SG_ 2566841598 RefrigerantHighPressSwitch 4;
BA_ "SPN" SG_ 2566841598 RefrigerantLowPressSwitch 875;
BA_ "SigType" SG_ 2566841598 RefrigerantLowPressSwitch 4;
BA_ "SPN" SG_ 2566841598 A_CHighPressFanSwitch 985;
BA_ "SigType" SG_ 2566841598 A_CHighPressFanSwitch 4;
BA_ "SPN" SG_ 2566841598 EngIdleShutdownTimerFunction 591;
BA_ "SigType" SG_ 2566841598 EngIdleShutdownTimerFunction 4;
BA_ "SPN" SG_ 2566841598 EngIdleShutdownTimerState 590;
BA_ "SigType" SG_ 2566841598 EngIdleShutdownTimerState 4;
BA_ "SPN" SG_ 2566841598 EngIdleShutdownTimerOverride 592;
BA_ "SigType" SG_ 2566841598 EngIdleShutdownTimerOverride 4;
BA_ "SPN" SG_ 2566841598 EngIdleShutdownDriverAlertMode 594;
BA_ "SigType" SG_ 2566841598 EngIdleShutdownDriverAlertMode 4;
BA_ "SPN" SG_ 2566841598 PTOShutdownHasShutdownEng 5404;
BA_ "SigType" SG_ 2566841598 PTOShutdownHasShutdownEng 4;
BA_ "SPN" SG_ 2566841598 EngPrtctnSystmHasShutdownEngine 1110;
BA_ "SigType" SG_ 2566841598 EngPrtctnSystmHasShutdownEngine 4;
BA_ "SPN" SG_ 2566841598 EngIdlShutdownHasShutdownEngine 593;
BA_ "SigType" SG_ 2566841598 EngIdlShutdownHasShutdownEngine 4;
BA_ "SPN" SG_ 2566841598 EngAirShutoffStatus 3667;
BA_ "SigType" SG_ 2566841598 EngAirShutoffStatus 4;
BA_ "SPN" SG_ 2566832382 ServiceComponentIdentificationB 912;
BA_ "SigType" SG_ 2566832382 ServiceComponentIdentificationB 1;
BA_ "SPN" SG_ 2566832382 ServiceComponentIdentificationA 911;
BA_ "SigType" SG_ 2566832382 ServiceComponentIdentificationA 1;
BA_ "SPN" SG_ 2566832382 SrvceDelay_OperationalTimeBased 916;
BA_ "SigType" SG_ 2566832382 SrvceDelay_OperationalTimeBased 1;
BA_ "SPN" SG_ 2566832382 ServiceDelay_CalendarTimeBased 915;
BA_ "SigType" SG_ 2566832382 ServiceDelay_CalendarTimeBased 1;
BA_ "SPN" SG_ 2566832382 ServiceDistance 914;
BA_ "SigType" SG_ 2566832382 ServiceDistance 1;
BA_ "SPN" SG_ 2566832382 ServiceComponentIdentification 1584;
BA_ "SigType" SG_ 2566832382 ServiceComponentIdentification 1;
BA_ "SPN" SG_ 2633928446 TimeSinceLastService 1350;
BA_ "SigType" SG_ 2633928446 TimeSinceLastService 1;
BA_ "SPN" SG_ 2633928446 ServiceComponentIdentification 1584;
BA_ "SigType" SG_ 2633928446 ServiceComponentIdentification 1;
BA_ "SPN" SG_ 2566804478 MaxContinuousRetarderTorque 1782;
BA_ "SigType" SG_ 2566804478 MaxContinuousRetarderTorque 1;
BA_ "SPN" SG_ 2566804478 MinContinuousRetarderSpeed 1781;
BA_ "SigType" SG_ 2566804478 MinContinuousRetarderSpeed 1;
BA_ "SPN" SG_ 2566804478 MaxContinuousRetarderSpeed 1780;
BA_ "SigType" SG_ 2566804478 MaxContinuousRetarderSpeed 1;
BA_ "SPN" SG_ 2566804478 MinContinuousRetarderTorque 1783;
BA_ "SigType" SG_ 2566804478 MinContinuousRetarderTorque 1;
BA_ "SPN" SG_ 2566804478 LwLmtThrshldFrMxTrqFromRetarder 1778;
BA_ "SigType" SG_ 2566804478 LwLmtThrshldFrMxTrqFromRetarder 1;
BA_ "SPN" SG_ 2566804478 LwLmtThrshldFrMxRPMFromRetarder 1776;
BA_ "SigType" SG_ 2566804478 LwLmtThrshldFrMxRPMFromRetarder 1;
BA_ "SPN" SG_ 2566804478 HghLmtThrshldFrMnCntnsTrqFrmRtrd 1779;
BA_ "SigType" SG_ 2566804478 HghLmtThrshldFrMnCntnsTrqFrmRtrd 1;
BA_ "SystemSignalLongSymbol" SG_ 2566804478 HghLmtThrshldFrMnCntnsTrqFrmRtrd "HghLmtThrshldFrMnCntnsTrqFrmRtrdr";
BA_ "SPN" SG_ 2566804478 HghLmtThrshldFrMnCntnsRPMFrmRtrd 1777;
BA_ "SigType" SG_ 2566804478 HghLmtThrshldFrMnCntnsRPMFrmRtrd 1;
BA_ "SystemSignalLongSymbol" SG_ 2566804478 HghLmtThrshldFrMnCntnsRPMFrmRtrd "HghLmtThrshldFrMnCntnsRPMFrmRtrdr";
BA_ "SPN" SG_ 2566847486 DrvlneRetarderOverheatIndicator 5346;
BA_ "SigType" SG_ 2566847486 DrvlneRetarderOverheatIndicator 4;
BA_ "SPN" SG_ 2566847486 HydRetarderOilTemp 120;
BA_ "SigType" SG_ 2566847486 HydRetarderOilTemp 1;
BA_ "SPN" SG_ 2566847486 HydRetarderPress 119;
BA_ "SigType" SG_ 2566847486 HydRetarderPress 1;
BA_ "SPN" SG_ 2631859966 EngBuildHoursReset 1211;
BA_ "SigType" SG_ 2631859966 EngBuildHoursReset 4;
BA_ "SPN" SG_ 2631859966 TripGroup2Proprietary 989;
BA_ "SigType" SG_ 2631859966 TripGroup2Proprietary 4;
BA_ "SPN" SG_ 2631859966 TripGroup1 988;
BA_ "SigType" SG_ 2631859966 TripGroup1 4;
BA_ "SPN" SG_ 2631859966 SteerStraightAheadPosReset 3600;
BA_ "SigType" SG_ 2631859966 SteerStraightAheadPosReset 4;
BA_ "SPN" SG_ 2631859966 ServiceComponentIdentification 1584;
BA_ "SigType" SG_ 2631859966 ServiceComponentIdentification 1;
BA_ "SPN" SG_ 2631859966 ServiceComponentIdentificationC 1584;
BA_ "SigType" SG_ 2631859966 ServiceComponentIdentificationC 1;
VAL_ 2566808574 FuelLevelWarning 1 "Fuel level warning on" 0 "Fuel level warning off" ;
VAL_ 2566808574 EngineOilPressureWarning 1 "Warning" 0 "No warning" ;
VAL_ 2566808574 EngineCoolantTempWarning 2 "Warning" 1 "Prewarning" 0 "No warning" ;
VAL_ 2564947710 VehicleType 1 "Dolly axle" 0 "Towing or towed vehicle" ;
VAL_ 2566834430 AntiTheftDeviceStatus 1 "Anti-theft device on" 0 "Anti-theft device off" ;
VAL_ 2566834430 ODDStatus 1 "ODD active" 0 "ODD inactive" ;
VAL_ 2566808318 SecEngineMtdPTOSwitch 1 "Switched on" 0 "Switched off" ;
VAL_ 2566808318 SecClutchDpdtPTOSwitch 1 "Switched on" 0 "Switched off" ;
VAL_ 2566808318 FirstClutchDpdtPTOSwitch 1 "Switched on" 0 "Switched off" ;
VAL_ 2566808318 OperatingPanelActive 1 "Operating panel active" 0 "Operating panel not active" ;
VAL_ 2566808318 RefusePackerStepSwitch 1 "Switched on" 0 "Switched off" ;
VAL_ 2566808318 EngineStopSwitch 1 "Switched on" 0 "Switched off" ;
VAL_ 2566808318 EngineStartSwitch 1 "Switched on" 0 "Switched off" ;
VAL_ 2566808318 StarterLockoutSwitch 1 "Switched on" 0 "Switched off" ;
VAL_ 2566808318 FirstEngineMtdPTOSwitch 1 "Switched on" 0 "Switched off" ;
VAL_ 2566808318 ClutchIndpdtPTOSwitch 1 "Switched on" 0 "Switched off" ;
VAL_ 2566808830 TrailerLeftSideMarkerLight 1 "Lamp(s) lit" 0 "Lamp(s) not lit" ;
VAL_ 2566808830 TrailerLeftReversingLight 1 "Lamp(s) lit" 0 "Lamp(s) not lit" ;
VAL_ 2566808830 TrailerLeftRearWidIndLight 1 "Lamp(s) lit" 0 "Lamp(s) not lit" ;
VAL_ 2566808830 TrailerLeftRearRegPltLight 1 "Lamp(s) lit" 0 "Lamp(s) not lit" ;
VAL_ 2566808830 TrailerLeftRearLight 1 "Lamp(s) lit" 0 "Lamp(s) not lit" ;
VAL_ 2566808830 TrailerLeftRearFogLight 1 "Lamp(s) lit" 0 "Lamp(s) not lit" ;
VAL_ 2566808830 TrailerLeftDirIndLight 1 "Lamp(s) lit" 0 "Lamp(s) not lit" ;
VAL_ 2566808830 TrailerLeftCrnMarkerLight 1 "Lamp(s) lit" 0 "Lamp(s) not lit" ;
VAL_ 2566808830 TrailerInteriorLight 1 "Lamp(s) lit" 0 "Lamp(s) not lit" ;
VAL_ 2566808830 TrailerWorkLamp 1 "Lamp(s) lit" 0 "Lamp(s) not lit" ;
VAL_ 2566808830 TrailerRotatingIdentLight 1 "Lamp(s) lit" 0 "Lamp(s) not lit" ;
VAL_ 2566808830 TrailerRightStopLight 1 "Lamp(s) lit" 0 "Lamp(s) not lit" ;
VAL_ 2566808830 TrailerRightSideMrkLight 1 "Lamp(s) lit" 0 "Lamp(s) not lit" ;
VAL_ 2566808830 TrailerRightReversingLight 1 "Lamp(s) lit" 0 "Lamp(s) not lit" ;
VAL_ 2566808830 TrailRightRearWidIndLight 1 "Lamp(s) lit" 0 "Lamp(s) not lit" ;
VAL_ 2566808830 TrailerRightRearRegPltLight 1 "Lamp(s) lit" 0 "Lamp(s) not lit" ;
VAL_ 2566808830 TrailerRightRearLight 1 "Lamp(s) lit" 0 "Lamp(s) not lit" ;
VAL_ 2566808830 TrailerRightRearFogLight 1 "Lamp(s) lit" 0 "Lamp(s) not lit" ;
VAL_ 2566808830 TrailerRightDirIndLight 1 "Lamp(s) lit" 0 "Lamp(s) not lit" ;
VAL_ 2566808830 TrailerRightCrnMarkerLight 1 "Lamp(s) lit" 0 "Lamp(s) not lit" ;
VAL_ 2566808830 TrailerRearWarningLight 1 "Lamp(s) lit" 0 "Lamp(s) not lit" ;
VAL_ 2566808830 TrailerLeftStopLight 1 "Lamp(s) lit" 0 "Lamp(s) not lit" ;
VAL_ 2564554494 FlowStatus 2 "Overflow" 1 "Wait " 0 "Continue To Send" ;
VAL_ 2564554494 ProtocolCtrlInformation 3 "Flow control " 2 "Consecutive frame" 1 "First frame" 0 "Single frame" ;
VAL_ 2564488958 FlowStatus 2 "Overflow" 1 "Wait " 0 "Continue To Send" ;
VAL_ 2564488958 ProtocolCtrlInformation 3 "Flow control " 2 "Consecutive frame" 1 "First frame" 0 "Single frame" ;
VAL_ 2565734142 ControlByte 6 "MFDB_CreateEntry" 5 "MFDB_SetMode" 4 "MFDB_Clear" 3 "MFDB_Delete" 2 "MFDB_Add" 1 "MFDB_Response" 0 "MFDB_Request" ;
VAL_ 2565734142 FilterMode 1 "PassSpecificPGNs" 0 "BlockSpecificPGNs" ;
VAL_ 2565144318 StopLevelChangeReq 3 "Take no action" 1 "Stop request" 0 "No stop request" ;
VAL_ 2565144318 RampLevelStorageReq 3 "Take no action" 1 "Store ramp level 2" 0 "Store ramp level 1" ;
VAL_ 2565144318 LevelControlReq 3 "Take no action" 1 "Enable level control" 0 "Disable level control" ;
VAL_ 2565144318 RampLevelReq 3 "Take no action" 1 "Ramp level 2" 0 "Ramp level 1" ;
VAL_ 2565144318 SteeringAxleLockingReq 3 "Take no action" 1 "Lock steering axle" 0 "Unlock steering axle" ;
VAL_ 2565144318 LiftAxle2PositionReq 3 "Take no action" 1 "Position up / tag axle unladen" 0 "Position down / tag axle laden" ;
VAL_ 2565144318 LiftAxle1PositionReq 3 "Don't care/take no action" 2 "Reserved" 1 "Position up / tag axle unladen" 0 "Position down / tag axle laden" ;
VAL_ 2565144318 TractionHelpReq 3 "Take no action" 1 "Traction help request" 0 "No traction help request" ;
VAL_ 2565144318 LevelChangeReqRearAxle 2 "Take no action" 1 "Vehicle body down (lowering)" 0 "Vehicle body up (lifting)" ;
VAL_ 2565144318 LevelChangeReqFrontAxle 2 "Take no action" 1 "Vehicle body down (lowering)" 0 "Vehicle body up (lifting)" ;
VAL_ 2565144318 RideHeightRequest 2 "Take no action" 1 "Normal level 2" 0 "Normal level 1" ;
VAL_ 2565209854 LevelControl 1 "Level control enabled" 0 "Level control disabled" ;
VAL_ 2565209854 RampLevel 1 "Body at requested ramp level" 0 "Body not at requested ramp level" ;
VAL_ 2565209854 NormalLevel 3 "Not available" 1 "Normal level 2" 0 "Normal level 1" ;
VAL_ 2565209854 StopLevelChangeAcknowledge 1 "Level change stopped" 0 "No stop request" ;
VAL_ 2565209854 LevelChangeRearAxle 1 "Body lifting/lowering active" 0 "Body lifting/lowering not active" ;
VAL_ 2565209854 LevelChangeFrontAxle 1 "Body lifting/lowering active" 0 "Body lifting/lowering not active" ;
VAL_ 2565209854 RampLevelStorage 1 "New ramp level stored" 0 "No new storage request" ;
VAL_ 2565209854 SteeringAxleLocking 1 "Steering axle locked" 0 "Steering axle unlocked" ;
VAL_ 2565209854 LiftAxle2Pos 3 "NotAvailable" 2 "Error" 1 "LiftAxlePosUp_TagAxleUnladen" 0 "LiftAxlePosDown_TagAxleLaden" ;
VAL_ 2565209854 LiftAxle1Pos 3 "NotAvailable" 2 "Error" 1 "LiftAxlePosUp_TagAxleUnladen" 0 "LiftAxlePosDown_TagAxleLaden" ;
VAL_ 2565209854 RampLevelPosition 3 "Not available" 1 "Ramp level 2" 0 "Ramp level 1" ;
VAL_ 2565209854 TractionHelp 1 "Traction help active" 0 "Traction help inactive" ;
VAL_ 2565209854 LevelCtrlSysRideHeightLevel 1 "Vehicle body at requested level" 0 "Vehicle body not at req. level" ;
VAL_ 2566807294 TyrePressThresholdDetect 7 "Not available" 6 "Error indicator" 5 "Not defined" 4 "Extreme under pressure" 3 "Under pressure" 2 "No warning pressure" 1 "Over pressure" 0 "Extreme over pressure" ;
VAL_ 2566807294 TyreModulePowerSupply 1 "Sufficient power supply" 0 "Insufficient power supply" ;
VAL_ 2566807294 TyreWheelIdentification2 15 "Axle position 15" 14 "Axle position 14" 13 "Axle position 13" 12 "Axle position 12" 11 "Axle position 11" 10 "Axle position 10" 9 "Axle position 9" 8 "Axle position 8" 7 "Axle position 7" 6 "Axle position 6" 5 "Axle position 5" 4 "Axle position 4" 3 "Axle position 3" 2 "Axle position 2" 1 "Axle position 1" 0 "Axle position not identified" ;
VAL_ 2566807294 TyreWheelIdentification1 15 "Wheel position 15" 14 "Wheel position 14" 13 "Wheel position 13" 12 "Wheel position 12" 11 "Wheel position 11" 10 "Wheel position 10" 9 "Wheel position 9" 8 "Wheel position 8" 7 "Wheel position 7" 6 "Wheel position 6" 5 "Wheel position 5" 4 "Wheel position 4" 3 "Wheel position 3" 2 "Wheel position 2" 1 "Wheel position 1" 0 "Wheel position not identified" ;
VAL_ 2566764798 NMHCConvertingCatalystCompleted 1 "NotCompleteCycle" 0 "CompleteCycleOrNotSupported" ;
VAL_ 2566764798 NMHCConvertingCatalystEnabled 1 "EnabledForCycle" 0 "DisabledForRestOfCycle" ;
VAL_ 2566764798 NOxConvertingCatalystAdsorberCom 1 "NotCompleteCycle" 0 "CompleteCycleOrNotSupported" ;
VAL_ 2566764798 NOxConvertingCatalystAdsorberEna 1 "EnabledForCycle" 0 "DisabledForRestOfCycle" ;
VAL_ 2566764798 DieselParticulateFilterCompleted 1 "NotCompleteCycle" 0 "CompleteCycleOrNotSupported" ;
VAL_ 2566764798 DieselParticulateFilterEnabled 1 "EnabledForCycle" 0 "DisabledForRestOfCycle" ;
VAL_ 2566764798 BoostPressureControlSystemComple 1 "NotCompleteCycle" 0 "CompleteCycleOrNotSupported" ;
VAL_ 2566764798 BoostPressureCtrlSystemEnabled 1 "EnabledForCycle" 0 "DisabledForRestOfCycle" ;
VAL_ 2566764798 MisfireMonitoringComplete 1 "EnabledForCycle" 0 "DisabledForRestOfCycle" ;
VAL_ 2566764798 MisfireMonitoringEnabled 1 "EnabledForCycle" 0 "DisabledForRestOfCycle" ;
VAL_ 2566764798 FuelSystemMonitoringEnabled 1 "NotCompleteCycle" 0 "CompleteCycleOrNotSupported" ;
VAL_ 2566764798 ComprehensiveComptMonComplete 1 "NotCompleteCycle" 0 "CompleteCycleOrNotSupported" ;
VAL_ 2566764798 ComprehensiveCompMonEnabled 1 "NotCompleteCycle" 0 "CompleteCycleOrNotSupported" ;
VAL_ 2566764798 SecondAirSystemMonComplete 1 "EnabledForCycle" 0 "DisabledForRestOfCycle" ;
VAL_ 2566764798 SecondAirSystemMonEnabled 1 "EnabledForCycle" 0 "DisabledForRestOfCycle" ;
VAL_ 2566764798 OxygenSensorMonComplete 1 "EnabledForCycle" 0 "DisabledForRestOfCycle" ;
VAL_ 2566764798 OxygenSensorMonEnabled 1 "NotCompleteCycle" 0 "CompleteCycleOrNotSupported" ;
VAL_ 2566764798 OxygenSensorHeaterMonComplete 1 "EnabledForCycle" 0 "DisabledForRestOfCycle" ;
VAL_ 2566764798 OxygenSensorHeaterMonEnabled 1 "NotCompleteCycle" 0 "CompleteCycleOrNotSupported" ;
VAL_ 2566764798 HeatedCatalystMonComplete 1 "EnabledForCycle" 0 "DisabledForRestOfCycle" ;
VAL_ 2566764798 HeatedCatalystMonEnabled 1 "EnabledForCycle" 0 "DisabledForRestOfCycle" ;
VAL_ 2566764798 EvaporativeSystemMonComplete 1 "NotCompleteCycle" 0 "CompleteCycleOrNotSupported" ;
VAL_ 2566764798 EvaporativeSystemMonEnabled 1 "NotCompleteCycle" 0 "CompleteCycleOrNotSupported" ;
VAL_ 2566764798 EGRSystemMonitoringComplete 1 "NotCompleteCycle" 0 "CompleteCycleOrNotSupported" ;
VAL_ 2566764798 EGRSystemMonitoringEnabled 1 "EnabledForCycle" 0 "DisabledForRestOfCycle" ;
VAL_ 2566764798 ColdStartAidSystemMonComplete 1 "NotCompleteCycle" 0 "CompleteCycleOrNotSupported" ;
VAL_ 2566764798 ColdStartAidSystemMonEnabled 1 "EnabledForCycle" 0 "DisabledForRestOfCycle" ;
VAL_ 2566764798 CatalystMonComplete 1 "NotCompleteCycle" 0 "CompleteCycleOrNotSupported" ;
VAL_ 2566764798 CatalystMonEnabled 1 "NotCompleteCycle" 0 "CompleteCycleOrNotSupported" ;
VAL_ 2566764798 ACSystemRefrigerantMonComplete 1 "NotCompleteCycle" 0 "CompleteCycleOrNotSupported" ;
VAL_ 2566764798 ACSystemRefrigerantMonEnabled 1 "NotCompleteCycle" 0 "CompleteCycleOrNotSupported" ;
VAL_ 2566764798 FuelSystemMonitoringComplete 1 "NotCompleteCycle" 0 "CompleteCycleOrNotSupported" ;
VAL_ 2564095742 SecurityEntityType 3 "Data is Certificate" 2 "Data is Session Key" 1 "Data is Long Key" 0 "Data is Long Seed" ;
VAL_ 2349137662 XBRCtrlMode 3 "NotDefined" 2 "AccelerationControlWithMaxMode" 1 "AccelerationControlWithAddMode" 0 "OverrideDisabled" ;
VAL_ 2349137662 XBRPriority 3 "LwPrrtyUsdInOvrrdDsbldXBRCtrlMd" 2 "MdmPrrtyUsdFrACCSystmsThsMdDsNt" 1 "HighPriorityNotDefined" 0 "HghstPrrtyUsdFrEmrgncySttnsEgFr" ;
VAL_ 2349137662 XBREBIMode 3 "NotDefined" 2 "EndranceBrakeIntegrationAllowed" 1 "OnlyEnduranceBrakesAllowed" 0 "NEndrnceBrakeIntegrationAllowed" ;
VAL_ 2349137662 XBRUrgency 4 "LwRtrdrDynmcsShllBFllyCmpnstdBy" 0 "SttnNtCrtclLwRtrdrDynmcsArTlrtd" ;
VAL_ 2566848510 WaterInFuelIndicator 3 "NotAvailable" 2 "Error" 1 "Yes" 0 "No" ;
VAL_ 2566843134 AxleLocation 48 "Axle3_Position0" 32 "Axle2_Position0" 16 "Axle1_Position0" 0 "Axle0_Position0" ;
VAL_ 2566809854 WinchOilPressSwitch 3 "NotAvailable" 2 "ErrrSwtchStteCannotBeDetermined" 1 "OKOilPressIsAboveMin" 0 "NOTOKOilPressIsTooLow" ;
VAL_ 2566809854 HydOilFilterRestrictionSwitch 3 "NotAvailable" 2 "Error" 1 "RestrictionExistsOnOilFilter" 0 "NoRestriction" ;
VAL_ 2565868030 SteerWheelAngleSensorType 3 "NotAvailable" 2 "Reserved" 1 "AbsMeasuringPrinciple" 0 "RelativeMeasuringPrinciple" ;
VAL_ 2566803454 YCBrakeCtrlActive 3 "DontCare_TakeNoAction" 2 "Reserved" 1 "YCBrakeCtrlActive" 0 "YCBrakeCtrlPassiveButInstalled" ;
VAL_ 2566803454 YCEngCtrlActive 3 "DontCare_TakeNoAction" 2 "Reserved" 1 "YCEngCtrlActive" 0 "YCEngCtrlPassiveButInstalled" ;
VAL_ 2566803454 ROPBrakeCtrlActive 3 "DontCare_TakeNoAction" 2 "Reserved" 1 "ROPBrakeCtrlActive" 0 "ROPBrakeCtrlPassiveButInstalled" ;
VAL_ 2566803454 ROPEngCtrlActive 3 "DontCare_TakeNoAction" 2 "Reserved" 1 "ROPEngCtrlActive" 0 "ROPEngCtrlPassiveButInstalled" ;
VAL_ 2566803454 VDCBrakeLightRq 3 "DontCare_TakeNoAction" 2 "Reserved" 1 "TurnBrakeLightOn" 0 "TurnBrakeLightNotOn" ;
VAL_ 2566803454 VDCFullyOperational 3 "DontCare_TakeNoAction" 2 "Reserved" 1 "FullyOperational" 0 "NotFullyOperational" ;
VAL_ 2566803454 VDCInformationSignal 3 "DontCare_TakeNoAction" 2 "Reserved" 1 "On" 0 "Off" ;
VAL_ 2348875518 MessageCounter 14 "Reserved" 13 "Reserved" 12 "Reserved" 11 "Reserved" 10 "Reserved" 9 "Reserved" 8 "Reserved" 15 "Not Available" ;
VAL_ 2348875518 ControlPurpose 5 "TemporaryPowerTrainControl" 4 "EngineProtection" 3 "RoadSpeedGovernor" 2 "PTOGovernor" 1 "CruiseControl" 0 "AcceleratorPedal" ;
VAL_ 2348875518 TransmissionRate 7 "UseStandardRate" 6 "25ms" 5 "50ms" 4 "100ms" 3 "250ms" 2 "500ms" 1 "750ms" 0 "1000ms" ;
VAL_ 2348875518 OverrideCtrlModePriority 3 "LowPriority" 2 "MdmPrrtyUsdFrPwrtrnCtrlOprtnsWh" 1 "HighPriority" 0 "HghstPrrtyUsdFrSttnsThtRqrImmdt" ;
VAL_ 2348875518 EngRqedSpeedCtrlConditions 2 "ThsCtrlCndtnHsBnOptmzdTMnmzRpmO" 3 "StbltyOptmzdFrDrvlnEnggdAnd_OrI" 1 "StbltyOptmzdFrDrvlnDsnggdAndNnl" 0 "ThsSpdGvrnrGnSlctnIsAdjstdTPrvd" ;
VAL_ 2348875518 EngOverrideCtrlMode 3 "Spd_TrqLmtCtrlLmtSpdAnd_OrTrqBs" 2 "TrqCtrlCntrlTrqTInclddDsrdTrqVl" 1 "SpdCtrlGvrnSpdTInclddDsrdSpdVle" 0 "OvrrdDsbldDsblAnyExstngCtrlCmdd" ;
VAL_ 2348875518 MessageChecksum 15 "Not Available" ;
VAL_ 2348875518 EngineRequestedTorqueHiRes 15 "Not Available" 14 "Not Available" 13 "Not Available" 12 "Not Available" 11 "Not Available" 10 "Not Available" 9 "Not Available" 8 "Not Available" ;
VAL_ 2566766846 TransitRunStatus 3 "NotAvailable" 2 "ErrorCondition" 1 "On" 0 "Off" ;
VAL_ 2566766846 VehicleUseStatus 3 "NotAvailable" 2 "ErrorCondition" 1 "UnauthorizedUse" 0 "NormalUse" ;
VAL_ 2566766846 SilentAlarmStatus 3 "NotAvailable" 2 "ErrorCondition" 1 "On" 0 "Off" ;
VAL_ 2566766846 TypeOfPassengerCount 1 "BoardingPassenger" 0 "AbsPassengerCount" 4 "Exiting Passenger (second passenger stream)" 3 "Boarding Passenger (second passenger stream)" 2 "Exiting Passenger" ;
VAL_ 2566765310 FareboxAlarmIdentifier 97 "1111111AgencyDefined" 26 "1100000ReservedToBeAssigned" 25 "MaintenanceAccessOutOfService" 24 "MntnncAccssInSrvcCnsdrdAnAlrmCn" 23 "PaperCurrencyJamCleared" 22 "PaperCurrencyJam" 21 "Pass_TransferJamCleared" 20 "Pass_TransferJam" 19 "FareboxResetToAutomaticMode" 18 "FareboxSetInManualBypass" 17 "CoinDejamOperated" 16 "Card_PassBoxFull" 15 "Card_PassBoxLessThan75Full" 14 "Card_PassBox75Full" 13 "CurrencyBoxFull" 12 "CurrencyBoxLessThan75Full" 11 "CurrencyBox75Full" 10 "CoinboxFull" 9 "Coinbox75Full" 8 "InsufficientFareAccepted" 7 "CshbxOpndInSrvcCnsdrdAnAlrmCndt" 6 "CashboxDoorTimeout" 5 "CashboxRestored" 4 "CashboxRemoved" 3 "ProbeCompleted" 2 "ProbeStarted" 1 "VoltageRestored" 0 "VoltageDropout" ;
VAL_ 2566765310 FareboxEmergencyStatus 3 "NotAvailable" 2 "ErrorCondition" 1 "EmergencyCondition" 0 "NonemergencyCondition" ;
VAL_ 2566765566 TransferType 6 "11111AgencyDefined" 5 "Out" 4 "In" 3 "West" 2 "East" 1 "South" 0 "North" ;
VAL_ 2566765566 TypeOfService 2 "111AgencyDefined" 1 "ExpressService" 0 "LocalService" ;
VAL_ 2566765566 PaymentDetails 11 "1111AgencyDefined" 6 "1010ReservedForAssignment" 5 "Card" 4 "Pass" 3 "Ticket" 2 "Token" 1 "Cash" 0 "NotAnUpgrade" ;
VAL_ 2566765566 TypeOfFare 11 "1111AgencyDefined" 7 "1010ReservedForAssignment" 6 "PassB" 5 "PassA" 4 "TicketB" 3 "TicketA" 2 "TokenB" 1 "TokenA" 0 "Cash_NoDetail" ;
VAL_ 2566765566 TransactionType 12 "1111AgencyDefined" 8 "1011ReservedForAssignment" 7 "Free" 6 "Transfer" 5 "Permit" 4 "Card" 3 "Pass" 2 "Ticket" 1 "Token" 0 "Cash" ;
VAL_ 2566765822 DriversFareboxSecurityCode 1 "SecurityCode" 0 "Farebox is in reporting status" ;
VAL_ 2566765822 FarePresets 16 "to11111111ReservedForAssignment" 0 "to00001111AgencyDefined" ;
VAL_ 2566765822 TripDirection 6 "1111AgencyDefined" 5 "Out" 4 "In" 3 "West" 2 "East" 1 "South" 0 "North" ;
VAL_ 2566765822 TripStatus 6 "LayoverEnd" 5 "LayoverStart" 2 "TripEnd" 1 "TripStart" 7 "Undefined" ;
VAL_ 2566765822 FareboxServiceStatus 3 "NotAvailable" 2 "ErrorCondition" 1 "FareboxInService" 0 "FareboxOutOfService" ;
VAL_ 2566766078 StrobeActivationCtrlStatus 3 "NotAvailable" 2 "ErrorCondition" 1 "ActivateStrobe" 0 "DeactivateStrobe" ;
VAL_ 2566766078 TransitDoorEnable 3 "NotAvailable" 2 "ErrorCondition" 1 "TrnstDrSttsWllOvrrdStrbActvtion" 0 "IgnoreTransitDoorStatus" ;
VAL_ 2566766078 PriorityOfRespSentByEmitter 15 "NotAvailable" 14 "ErrorCondition" 12 "to1101Reserved" 11 "PrrtyStByHardwareToHighPriority" 10 "PrrtyStByHrdwareToProbePriority" 9 "PrrtySetByHardwareToLowPriority" 4 "to1000Reserved" 3 "HighPriority" 2 "ProbePriority" 1 "LowPriority" 0 "Reserved" ;
VAL_ 2566766078 IntersectionPreemptionRq_Resp 3 "NotAvailable" 2 "ErrorCondition" 1 "MessageIsARespFromEmitter" 0 "MessageIsARqDirectedToEmitter" ;
VAL_ 2566766078 TransitRouteIDUsage 3 "NotAvailable" 2 "ErrorCondition" 1 "TrnstRtIDUsedForInterleavedData" 0 "TrnstRtIDNtUsdFrInterleavedData" ;
VAL_ 2566766078 RangeCodeEnable 3 "NotAvailable" 2 "ErrorCondition" 1 "RangeCodeUsedForInterleavedData" 0 "RngCdeNotUsedForInterleavedData" ;
VAL_ 2561605374 TireLocation 51 "Axle3_Position3" 50 "Axle3_Position2" 49 "Axle3_Position1" 35 "Axle2_Position3" 34 "Axle2_Position2" 33 "Axle2_Position1" 19 "Axle1_Position3" 18 "Axle1_Position2" 17 "Axle1_Position1" 1 "Axle0_Position1" 48 "Axle3_Position0" 32 "Axle2_Position0" 16 "Axle1_Position0" 0 "Axle0_Position0" ;
VAL_ 2566765054 TireLocation 51 "Axle3_Position3" 50 "Axle3_Position2" 49 "Axle3_Position1" 35 "Axle2_Position3" 34 "Axle2_Position2" 33 "Axle2_Position1" 19 "Axle1_Position3" 18 "Axle1_Position2" 17 "Axle1_Position1" 1 "Axle0_Position1" 48 "Axle3_Position0" 32 "Axle2_Position0" 16 "Axle1_Position0" 0 "Axle0_Position0" ;
VAL_ 2566845694 TireLocation 51 "Axle3_Position3xx" 50 "Axle3_Position2" 49 "Axle3_Position1" 35 "Axle2_Position3" 34 "Axle2_Position2" 33 "Axle2_Position1" 19 "Axle1_Position3" 18 "Axle1_Position2" 17 "Axle1_Position1" 1 "Axle0_Position1" 48 "Axle3_Position0" 32 "Axle2_Position0" 16 "Axle1_Position0" 0 "Axle0_Position0" ;
VAL_ 2633922814 PCUSupplySolenoidStatus 3 "NotAvailable" 2 "Error" 1 "On" 0 "Off" ;
VAL_ 2633922814 PCUCtrlSolenoidStatus 3 "NotAvailable" 2 "Error" 1 "On" 0 "Off" ;
VAL_ 2633922814 PCUDeflateSolenoidStatus 3 "NotAvailable" 2 "Error" 1 "On" 0 "Off" ;
VAL_ 2633922814 TirePressSupplySwitchStatus 3 "NotAvailable" 2 "Error" 1 "On" 0 "Off" ;
VAL_ 2633922814 PCUSteerSolenoidStatus 3 "NotAvailable" 2 "Error" 1 "On" 0 "Off" ;
VAL_ 2633922814 PCUDriveSolenoidStatus 3 "NotAvailable" 2 "Error" 1 "On" 0 "Off" ;
VAL_ 2633922814 DriveChannelMode 15 "NotAvailable" 14 "ErrorCondition" 7 "1101Reserved" 6 "PressCheck" 5 "DfltWtSystmWllDfltWhnCndtnsAllw" 4 "InfltWtSystmWllInfltWhnCndtnsAl" 3 "Confirm" 2 "Deflate" 1 "Inflate" 0 "Maintain" ;
VAL_ 2633922814 Trailer_TagChannelMode 15 "NotAvailable" 14 "ErrorCondition" 7 "1101Reserved" 6 "PressCheck" 5 "DfltWtSystmWllDfltWhnCndtnsAllw" 4 "InfltWtSystmWllInfltWhnCndtnsAl" 3 "Confirm" 2 "Deflate" 1 "Inflate" 0 "Maintain" ;
VAL_ 2633922814 SteerChannelMode 15 "NotAvailable" 14 "ErrorCondition" 7 "1101Reserved" 6 "PressCheck" 5 "DfltWtSystmWllDfltWhnCndtnsAllw" 4 "InfltWtSystmWllInfltWhnCndtnsAl" 3 "Confirm" 2 "Deflate" 1 "Inflate" 0 "Maintain" ;
VAL_ 2633922814 PCUTrailerTagPushSolenoidStatus 3 "NotAvailable" 2 "Error" 1 "On" 0 "Off" ;
VAL_ 2566845694 TirePressThresholdDetection_13 7 "NotAvailable" 6 "ErrorIndicator" 5 "NotDefined" 4 "ExtrmUndrPrssTrPrssrIsAtALvlWhr" 3 "UndrPrssTrPrssrIsLwrThnThPrssrD" 2 "NWrnngPrssTrPrssrIsWthnThThrshl" 1 "OvrPrssTrPrssrIsHghrThnThPrssrD" 0 "ExtrmOvrPrssTrPrssrIsAtALvlWhrT" ;
VAL_ 2566845694 TirePressThresholdDetection_12 7 "NotAvailable" 6 "ErrorIndicator" 5 "NotDefined" 4 "ExtrmUndrPrssTrPrssrIsAtALvlWhr" 3 "UndrPrssTrPrssrIsLwrThnThPrssrD" 2 "NWrnngPrssTrPrssrIsWthnThThrshl" 1 "OvrPrssTrPrssrIsHghrThnThPrssrD" 0 "ExtrmOvrPrssTrPrssrIsAtALvlWhrT" ;
VAL_ 2566845694 TirePressThresholdDetection_11 7 "NotAvailable" 6 "ErrorIndicator" 5 "NotDefined" 4 "ExtrmUndrPrssTrPrssrIsAtALvlWhr" 3 "UndrPrssTrPrssrIsLwrThnThPrssrD" 2 "NWrnngPrssTrPrssrIsWthnThThrshl" 1 "OvrPrssTrPrssrIsHghrThnThPrssrD" 0 "ExtrmOvrPrssTrPrssrIsAtALvlWhrT" ;
VAL_ 2566845694 TirePressThresholdDetection_10 7 "NotAvailable" 6 "ErrorIndicator" 5 "NotDefined" 4 "ExtrmUndrPrssTrPrssrIsAtALvlWhr" 3 "UndrPrssTrPrssrIsLwrThnThPrssrD" 2 "NWrnngPrssTrPrssrIsWthnThThrshl" 1 "OvrPrssTrPrssrIsHghrThnThPrssrD" 0 "ExtrmOvrPrssTrPrssrIsAtALvlWhrT" ;
VAL_ 2566845694 TirePressThresholdDetection_01 7 "NotAvailable" 6 "ErrorIndicator" 5 "NotDefined" 4 "ExtrmUndrPrssTrPrssrIsAtALvlWhr" 3 "UndrPrssTrPrssrIsLwrThnThPrssrD" 2 "NWrnngPrssTrPrssrIsWthnThThrshl" 1 "OvrPrssTrPrssrIsHghrThnThPrssrD" 0 "ExtrmOvrPrssTrPrssrIsAtALvlWhrT" ;
VAL_ 2566845694 CTIWheelSensorStatus_33 3 "NotSupported" 2 "NotDefined" 1 "On" 0 "Off_IsolatedFromCTIPressCtrl" ;
VAL_ 2566845694 CTIWheelSensorStatus_32 3 "NotSupported" 2 "NotDefined" 1 "On" 0 "Off_IsolatedFromCTIPressCtrl" ;
VAL_ 2566845694 CTIWheelSensorStatus_31 3 "NotSupported" 2 "NotDefined" 1 "On" 0 "Off_IsolatedFromCTIPressCtrl" ;
VAL_ 2566845694 CTIWheelSensorStatus_30 3 "NotSupported" 2 "NotDefined" 1 "On" 0 "Off_IsolatedFromCTIPressCtrl" ;
VAL_ 2566845694 CTIWheelSensorStatus_23 3 "NotSupported" 2 "NotDefined" 1 "On" 0 "Off_IsolatedFromCTIPressCtrl" ;
VAL_ 2566845694 CTIWheelSensorStatus_22 3 "NotSupported" 2 "NotDefined" 1 "On" 0 "Off_IsolatedFromCTIPressCtrl" ;
VAL_ 2566845694 CTIWheelSensorStatus_21 3 "NotSupported" 2 "NotDefined" 1 "On" 0 "Off_IsolatedFromCTIPressCtrl" ;
VAL_ 2566845694 CTIWheelSensorStatus_20 3 "NotSupported" 2 "NotDefined" 1 "On" 0 "Off_IsolatedFromCTIPressCtrl" ;
VAL_ 2566845694 CTIWheelSensorStatus_13 3 "NotSupported" 2 "NotDefined" 1 "On" 0 "Off_IsolatedFromCTIPressCtrl" ;
VAL_ 2566845694 CTIWheelSensorStatus_12 3 "NotSupported" 2 "NotDefined" 1 "On" 0 "Off_IsolatedFromCTIPressCtrl" ;
VAL_ 2566845694 CTIWheelSensorStatus_11 3 "NotSupported" 2 "NotDefined" 1 "On" 0 "Off_IsolatedFromCTIPressCtrl" ;
VAL_ 2566845694 CTIWheelSensorStatus_10 3 "NotSupported" 2 "NotDefined" 1 "On" 0 "Off_IsolatedFromCTIPressCtrl" ;
VAL_ 2566845694 CTIWheelSensorStatus_01 3 "NotSupported" 2 "NotDefined" 1 "On" 0 "Off_IsolatedFromCTIPressCtrl" ;
VAL_ 2566845694 CTIWheelEndElectricalFault_33 3 "NotSupported" 2 "Error" 1 "NotDefined" 0 "Ok" ;
VAL_ 2566845694 CTIWheelEndElectricalFault_32 3 "NotSupported" 2 "Error" 1 "NotDefined" 0 "Ok" ;
VAL_ 2566845694 CTIWheelEndElectricalFault_31 3 "NotSupported" 2 "Error" 1 "NotDefined" 0 "Ok" ;
VAL_ 2566845694 CTIWheelEndElectricalFault_30 3 "NotSupported" 2 "Error" 1 "NotDefined" 0 "Ok" ;
VAL_ 2566845694 CTIWheelEndElectricalFault_23 3 "NotSupported" 2 "Error" 1 "NotDefined" 0 "Ok" ;
VAL_ 2566845694 CTIWheelEndElectricalFault_22 3 "NotSupported" 2 "Error" 1 "NotDefined" 0 "Ok" ;
VAL_ 2566845694 CTIWheelEndElectricalFault_21 3 "NotSupported" 2 "Error" 1 "NotDefined" 0 "Ok" ;
VAL_ 2566845694 CTIWheelEndElectricalFault_20 3 "NotSupported" 2 "Error" 1 "NotDefined" 0 "Ok" ;
VAL_ 2566845694 CTIWheelEndElectricalFault_13 3 "NotSupported" 2 "Error" 1 "NotDefined" 0 "Ok" ;
VAL_ 2566845694 CTIWheelEndElectricalFault_12 3 "NotSupported" 2 "Error" 1 "NotDefined" 0 "Ok" ;
VAL_ 2566845694 CTIWheelEndElectricalFault_11 3 "NotSupported" 2 "Error" 1 "NotDefined" 0 "Ok" ;
VAL_ 2566845694 CTIWheelEndElectricalFault_10 3 "NotSupported" 2 "Error" 1 "NotDefined" 0 "Ok" ;
VAL_ 2566845694 CTIWheelEndElectricalFault_01 3 "NotSupported" 2 "Error" 1 "NotDefined" 0 "Ok" ;
VAL_ 2566845694 CTITireStatus_33 3 "NotSupported" 2 "Error" 1 "TireLeakDetected" 0 "Ok" ;
VAL_ 2566845694 CTITireStatus_32 3 "NotSupported" 2 "Error" 1 "TireLeakDetected" 0 "Ok" ;
VAL_ 2566845694 CTITireStatus_31 3 "NotSupported" 2 "Error" 1 "TireLeakDetected" 0 "Ok" ;
VAL_ 2566845694 CTITireStatus_30 3 "NotSupported" 2 "Error" 1 "TireLeakDetected" 0 "Ok" ;
VAL_ 2566845694 CTITireStatus_23 3 "NotSupported" 2 "Error" 1 "TireLeakDetected" 0 "Ok" ;
VAL_ 2566845694 CTITireStatus_22 3 "NotSupported" 2 "Error" 1 "TireLeakDetected" 0 "Ok" ;
VAL_ 2566845694 CTITireStatus_21 3 "NotSupported" 2 "Error" 1 "TireLeakDetected" 0 "Ok" ;
VAL_ 2566845694 CTITireStatus_20 3 "NotSupported" 2 "Error" 1 "TireLeakDetected" 0 "Ok" ;
VAL_ 2566845694 CTITireStatus_13 3 "NotSupported" 2 "Error" 1 "TireLeakDetected" 0 "Ok" ;
VAL_ 2566845694 CTITireStatus_12 3 "NotSupported" 2 "Error" 1 "TireLeakDetected" 0 "Ok" ;
VAL_ 2566845694 CTITireStatus_11 3 "NotSupported" 2 "Error" 1 "TireLeakDetected" 0 "Ok" ;
VAL_ 2566845694 CTITireStatus_10 3 "NotSupported" 2 "Error" 1 "TireLeakDetected" 0 "Ok" ;
VAL_ 2566845694 CTITireStatus_01 3 "NotSupported" 2 "Error" 1 "TireLeakDetected" 0 "Ok" ;
VAL_ 2566845694 TirePressThresholdDetection_33 7 "NotAvailable" 6 "ErrorIndicator" 5 "NotDefined" 4 "ExtrmUndrPrssTrPrssrIsAtALvlWhr" 3 "UndrPrssTrPrssrIsLwrThnThPrssrD" 2 "NWrnngPrssTrPrssrIsWthnThThrshl" 1 "OvrPrssTrPrssrIsHghrThnThPrssrD" 0 "ExtrmOvrPrssTrPrssrIsAtALvlWhrT" ;
VAL_ 2566845694 TirePressThresholdDetection_32 7 "NotAvailable" 6 "ErrorIndicator" 5 "NotDefined" 4 "ExtrmUndrPrssTrPrssrIsAtALvlWhr" 3 "UndrPrssTrPrssrIsLwrThnThPrssrD" 2 "NWrnngPrssTrPrssrIsWthnThThrshl" 1 "OvrPrssTrPrssrIsHghrThnThPrssrD" 0 "ExtrmOvrPrssTrPrssrIsAtALvlWhrT" ;
VAL_ 2566845694 TirePressThresholdDetection_31 7 "NotAvailable" 6 "ErrorIndicator" 5 "NotDefined" 4 "ExtrmUndrPrssTrPrssrIsAtALvlWhr" 3 "UndrPrssTrPrssrIsLwrThnThPrssrD" 2 "NWrnngPrssTrPrssrIsWthnThThrshl" 1 "OvrPrssTrPrssrIsHghrThnThPrssrD" 0 "ExtrmOvrPrssTrPrssrIsAtALvlWhrT" ;
VAL_ 2566845694 TirePressThresholdDetection_30 7 "NotAvailable" 6 "ErrorIndicator" 5 "NotDefined" 4 "ExtrmUndrPrssTrPrssrIsAtALvlWhr" 3 "UndrPrssTrPrssrIsLwrThnThPrssrD" 2 "NWrnngPrssTrPrssrIsWthnThThrshl" 1 "OvrPrssTrPrssrIsHghrThnThPrssrD" 0 "ExtrmOvrPrssTrPrssrIsAtALvlWhrT" ;
VAL_ 2566845694 TirePressThresholdDetection_23 7 "NotAvailable" 6 "ErrorIndicator" 5 "NotDefined" 4 "ExtrmUndrPrssTrPrssrIsAtALvlWhr" 3 "UndrPrssTrPrssrIsLwrThnThPrssrD" 2 "NWrnngPrssTrPrssrIsWthnThThrshl" 1 "OvrPrssTrPrssrIsHghrThnThPrssrD" 0 "ExtrmOvrPrssTrPrssrIsAtALvlWhrT" ;
VAL_ 2566845694 TirePressThresholdDetection_22 7 "NotAvailable" 6 "ErrorIndicator" 5 "NotDefined" 4 "ExtrmUndrPrssTrPrssrIsAtALvlWhr" 3 "UndrPrssTrPrssrIsLwrThnThPrssrD" 2 "NWrnngPrssTrPrssrIsWthnThThrshl" 1 "OvrPrssTrPrssrIsHghrThnThPrssrD" 0 "ExtrmOvrPrssTrPrssrIsAtALvlWhrT" ;
VAL_ 2566845694 TirePressThresholdDetection_21 7 "NotAvailable" 6 "ErrorIndicator" 5 "NotDefined" 4 "ExtrmUndrPrssTrPrssrIsAtALvlWhr" 3 "UndrPrssTrPrssrIsLwrThnThPrssrD" 2 "NWrnngPrssTrPrssrIsWthnThThrshl" 1 "OvrPrssTrPrssrIsHghrThnThPrssrD" 0 "ExtrmOvrPrssTrPrssrIsAtALvlWhrT" ;
VAL_ 2566845694 TirePressThresholdDetection_20 7 "NotAvailable" 6 "ErrorIndicator" 5 "NotDefined" 4 "ExtrmUndrPrssTrPrssrIsAtALvlWhr" 3 "UndrPrssTrPrssrIsLwrThnThPrssrD" 2 "NWrnngPrssTrPrssrIsWthnThThrshl" 1 "OvrPrssTrPrssrIsHghrThnThPrssrD" 0 "ExtrmOvrPrssTrPrssrIsAtALvlWhrT" ;
VAL_ 2566845694 TirePressThresholdDetection_00 7 "NotAvailable" 6 "ErrorIndicator" 5 "NotDefined" 4 "ExtrmUndrPrssTrPrssrIsAtALvlWhr" 3 "UndrPrssTrPrssrIsLwrThnThPrssrD" 2 "NWrnngPrssTrPrssrIsWthnThThrshl" 1 "OvrPrssTrPrssrIsHghrThnThPrssrD" 0 "ExtrmOvrPrssTrPrssrIsAtALvlWhrT" ;
VAL_ 2566845694 CTIWheelSensorStatus_00 3 "NotSupported" 2 "NotDefined" 1 "On" 0 "Off_IsolatedFromCTIPressCtrl" ;
VAL_ 2566845694 CTIWheelEndElectricalFault_00 3 "NotSupported" 2 "Error" 1 "NotDefined" 0 "Ok" ;
VAL_ 2566845694 CTITireStatus_00 3 "NotSupported" 2 "Error" 1 "TireLeakDetected" 0 "Ok" ;
VAL_ 2566821630 EngTrbWstgteActuator1TempStatus 7 "NotAvailable" 6 "Error" 5 "NotDefined" 4 "LowMostSevere" 3 "LowLeastSevere" 2 "InRange" 1 "HighLeastSevere" 0 "HighMostSevere" ;
VAL_ 2365484286 VehicleOverspeed 3 "NotAvailable" 2 "Error" 1 "Overspeed" 0 "NoOverspeed" ;
VAL_ 2365484286 VehicleMotion 3 "NotAvailable" 2 "Error" 1 "VehicleMotionDetected" 0 "VehicleMotionNotDetected" ;
VAL_ 2365484286 DirectionIndicator 3 "NotAvailable" 2 "Error" 1 "Reverse" 0 "Forward" ;
VAL_ 2365484286 TachographPerformance 3 "NotAvailable" 2 "Error" 1 "PerformanceAnalysis" 0 "NormalPerformance" ;
VAL_ 2365484286 HandlingInformation 3 "NotAvailable" 2 "Error" 1 "HandlingInformation" 0 "NoHandlingInformation" ;
VAL_ 2365484286 SystemEvent 3 "NotAvailable" 2 "Error" 1 "TachographEvent" 0 "NoTachographEvent" ;
VAL_ 2365484286 DriverCardDriver2 3 "NotAvailable" 2 "Error" 1 "DriverCardPresent" 0 "DriverCardNotPresent" ;
VAL_ 2365484286 Driver2TimeRelatedStates 15 "NotAvailable" 14 "Error" 13 "Other" 7 "1100Reserved" 6 "Limit616HReached" 5 "Limit515MinBefore16H" 4 "Limit49HReached" 3 "Limit315MinBefore9H" 2 "Limit24HReached" 1 "Limit115MinBefore4H" 0 "Normal_NoLimitsReached" ;
VAL_ 2365484286 DriverCardDriver1 3 "NotAvailable" 2 "Error" 1 "DriverCardPresent" 0 "DriverCardNotPresent" ;
VAL_ 2365484286 Driver1TimeRelatedStates 15 "NotAvailable" 14 "Error" 13 "Other" 7 "1100Reserved" 6 "Limit616HReached" 5 "Limit515MinBefore16H" 4 "Limit49HReached" 3 "Limit315MinBefore9H" 2 "Limit24HReached" 1 "Limit115MinBefore4H" 0 "Normal_NoLimitsReached" ;
VAL_ 2365484286 Driver2WorkingState 7 "NotAvailable" 6 "Error" 4 "101Reserved" 3 "DriveBehindWheel" 2 "WrkLdngUnldingWorkingInAnOffice" 1 "DriverAvailableShortBreak" 0 "RestSleeping" ;
VAL_ 2365484286 Driver1WorkingState 7 "NotAvailable" 6 "Error" 4 "101Reserved" 3 "DriveBehindWheel" 2 "WrkLdngUnldingWorkingInAnOffice" 1 "DriverAvailableShortBreak" 0 "RestSleeping" ;
VAL_ 2348941054 TrnsShftSlctorDisplayModeSwitch 3 "NotAvailable" 2 "Error" 1 "On" 0 "Off" ;
VAL_ 2348941054 TransMode4 3 "TakeNoAction" 2 "Reserved" 1 "Enable" 0 "Disable" ;
VAL_ 2348941054 TransMode3 3 "TakeNoAction" 2 "Reserved" 1 "Enable" 0 "Disable" ;
VAL_ 2348941054 TransMode2 3 "TakeNoAction" 2 "Reserved" 1 "Enable" 0 "Disable" ;
VAL_ 2348941054 TransMode1 3 "TakeNoAction" 2 "Reserved" 1 "Enable" 0 "Disable" ;
VAL_ 2348941054 DisengageDiffLockRqCentralRear 3 "TakeNoAction" 2 "Reserved" 1 "DisengageDiffLock" 0 "EngageDiffLock" ;
VAL_ 2348941054 DisengageDiffLockRqCentralFront 3 "TakeNoAction" 2 "Reserved" 1 "DisengageDiffLock" 0 "EngageDiffLock" ;
VAL_ 2348941054 DisengageDiffLockRqCentral 3 "TakeNoAction" 2 "Reserved" 1 "DisengageDiffLock" 0 "EngageDiffLock" ;
VAL_ 2348941054 DisengageDiffLockRqRearAxle2 3 "TakeNoAction" 2 "Reserved" 1 "DisengageDiffLock" 0 "EngageDiffLock" ;
VAL_ 2348941054 DisengageDiffLockRqRearAxle1 3 "TakeNoAction" 2 "Reserved" 1 "DisengageDiffLock" 0 "EngageDiffLock" ;
VAL_ 2348941054 DisengageDiffLockRqFrontAxle2 3 "TakeNoAction" 2 "Reserved" 1 "DisengageDiffLock" 0 "EngageDiffLock" ;
VAL_ 2348941054 DisengageDiffLockRqFrontAxle1 3 "TakeNoAction" 2 "Reserved" 1 "DisengageDiffLock" 0 "EngageDiffLock" ;
VAL_ 2348941054 TransRqedGear 60 "Reserved" 61 "Reserved" 222 "NeutralSelectorPos" 223 "ReverseSelectorPos" 224 "PsUnknownAnd_OrNoButtonsPressed" 225 "PrssOfMmntryBttnTRslctCrrentPos" 226 "BtwnRvrsAndPrkShiftSelectorPoss" 227 "BtwnNtrlAndRvrsShftSelectorPoss" 228 "BtwnDrvAndNtrlShiftSelectorPoss" 229 "BtwnD1AndDriveShiftSelectorPoss" 230 "BetweenD2AndD1ShiftSelectorPoss" 231 "BetweenD3AndD2ShiftSelectorPoss" 232 "BetweenD4AndD3ShiftSelectorPoss" 233 "BetweenD5AndD4ShiftSelectorPoss" 234 "BetweenD6AndD5ShiftSelectorPoss" 235 "BetweenD7AndD6ShiftSelectorPoss" 236 "BtwnTwoForwardShiftSelectorPoss" 237 "BtwnTwoReverseShiftSelectorPoss" 238 "BetweenTwoShiftSelectorPoss" 239 "D77thFrwrdSlctrPsRfrncdFrmDrive" 240 "D66thFrwrdSlctrPsRfrncdFrmDrive" 241 "D55thFrwrdSlctrPsRfrncdFrmDrive" 242 "D44thFrwrdSlctrPsRfrncdFrmDrive" 243 "D33rdFrwrdSlctrPsRfrncdFrmDrive" 244 "D22ndFrwrdSlctrPsRfrncdFrmDrive" 245 "D11stFrwrdSlctrPsRfrncdFrmDrive" 246 "Downshift2GearsFromCurrentPos" 247 "Downshift1GearFromCurrentPos" 248 "Upshift2GearsFromCurrentPos" 249 "Upshift1GearFromCurrentPos" 250 "ForwardLowPos" 251 "ParkPos" 252 "ForwardDrivePos" 253 "HoldCurrentGear" ;
VAL_ 2348941054 DisengageDrivelineRq 2 "Reserved" 3 "TakeNoAction" 1 "DisengageDriveline" 0 "AllowDrivelineEngagement" ;
VAL_ 2348941054 TransGearShiftInhibitRq 2 "Reserved" 3 "TakeNoAction" 1 "GearShiftsAreInhibited" 0 "GearShiftsAreAllowed" ;
VAL_ 2348941054 TrnsTrqConverterLockupDisableRq 3 "TakeNoAction" 2 "Reserved" 1 "DisableTorqueConverterLockup" 0 "AllowTorqueConverterLockup" ;
VAL_ 2348941054 TransRqedLaunchGear 15 "NotAvailable" 14 "Error" 13 "Reserved" 12 "LaunchVehicleInReverse4" 11 "LaunchVehicleInReverse3" 10 "LaunchVehicleInReverse2" 9 "LaunchVehicleInReverse1" 8 "LaunchVehicleIn8thGear" 7 "LaunchVehicleIn7thGear" 6 "LaunchVehicleIn6thGear" 5 "LaunchVehicleIn5thGear" 4 "LaunchVehicleIn4thGear" 3 "LaunchVehicleIn3rdGear" 2 "LaunchVehicleIn2ndGear" 1 "LaunchVehicleIn1stGear" 0 "NSpcfcLnchGrRqdUsDfltLaunchGear" ;
VAL_ 2348941054 TransReverseGearShiftInhibitRq 3 "TakeNoAction" 2 "Reserved" 1 "InhbtShftsIntRvrsGrAndShftTrnsT" 0 "AllowShiftsIntoReverseGear" ;
VAL_ 2348941054 TransMode8 3 "TakeNoAction" 2 "Reserved" 1 "Enable" 0 "Disable" ;
VAL_ 2348941054 TransMode7 3 "TakeNoAction" 2 "Reserved" 1 "Enable" 0 "Disable" ;
VAL_ 2348941054 TransMode6 3 "TakeNoAction" 2 "Reserved" 1 "Enable" 0 "Disable" ;
VAL_ 2348941054 TransMode5 3 "TakeNoAction" 2 "Reserved" 1 "Enable" 0 "Disable" ;
VAL_ 2566839806 EngTurboOilLevelSwitch 3 "NotAvailable" 2 "Error" 1 "OilPresentAtTurbo" 0 "NoOilPresentAtTurbo" ;
VAL_ 2566841598 EngOverspeedTest 3 "NotAvailable" 2 "Reserved" 1 "EngOverspeedTestActive" 0 "EngOverspeedTestNotActive" ;
VAL_ 2566841598 EngAirShutoffCmdStatus 0 "ArShtffDsbldNtAttmptngTShtffEng" 3 "NotAvailable" 2 "Reserved" 1 "ArShtffEnbldAttmptngTShtffEngAr" ;
VAL_ 2566841598 EngAlarmOutputCmdStatus 3 "NotAvailable" 2 "Reserved" 1 "EngAlarmOutputCmdActive" 0 "EngAlarmOutputCmdNotActive" ;
VAL_ 2566841598 EngAlarmAcknowledge 3 "NotAvailable" 2 "Error" 1 "EngAlarmAcknowledgeActive" 0 "EngAlarmAcknowledgeNotActive" ;
VAL_ 2566841598 EngProtectionSystemConfig 3 "NotAvailable" 2 "Error" 1 "EnabledInCalib" 0 "DisabledInCalib" ;
VAL_ 2566841598 EngProtectionSystemTimerState 3 "NotAvailable" 2 "Error" 1 "Active" 0 "Inactive" ;
VAL_ 2566841598 EngPrtectionSystemTimerOverride 3 "NotAvailable" 2 "Error" 1 "Active" 0 "Inactive" ;
VAL_ 2566841598 EngPrtctnSystmApprchingShutdown 3 "NotAvailable" 2 "Error" 1 "Approaching" 0 "NotApproaching" ;
VAL_ 2566841598 EngWaitToStartLamp 3 "NotAvailable" 2 "Error" 1 "On" 0 "Off" ;
VAL_ 2566841598 RefrigerantHighPressSwitch 3 "NotAvailable" 2 "Error" 1 "PrssTHghCmprssrCltchMyBDsngaged" 0 "PressNormal" ;
VAL_ 2566841598 RefrigerantLowPressSwitch 3 "NotAvailable" 2 "Error" 1 "PrssTLwCmprssrCltchMyBDsengaged" 0 "PressNormal" ;
VAL_ 2566841598 A_CHighPressFanSwitch 3 "NotAvailable" 2 "Error" 1 "PressHighFanMayBeEngaged" 0 "PressNormal" ;
VAL_ 2566841598 EngIdleShutdownTimerFunction 3 "NotAvailable" 2 "Error" 1 "EnabledInCalib" 0 "DisabledInCalib" ;
VAL_ 2566841598 EngIdleShutdownTimerState 3 "NotAvailable" 2 "Error" 1 "Active" 0 "Inactive" ;
VAL_ 2566841598 EngIdleShutdownTimerOverride 3 "NotAvailable" 2 "Error" 1 "Active" 0 "Inactive" ;
VAL_ 2566841598 EngIdleShutdownDriverAlertMode 3 "NotAvailable" 2 "Error" 1 "Active" 0 "Inactive" ;
VAL_ 2566841598 PTOShutdownHasShutdownEng 3 "NotAvailable" 2 "Error" 1 "Yes" 0 "No" ;
VAL_ 2566841598 EngPrtctnSystmHasShutdownEngine 3 "NotAvailable" 2 "Error" 1 "Yes" 0 "No" ;
VAL_ 2566841598 EngIdlShutdownHasShutdownEngine 3 "NotAvailable" 2 "Error" 1 "Yes" 0 "No" ;
VAL_ 2566841598 EngAirShutoffStatus 3 "NotAvailable" 2 "Error" 1 "AirFlowRestricted" 0 "AirFlowAllowedToEng" ;
VAL_ 2566847486 DrvlneRetarderOverheatIndicator 3 "NotAvailable" 2 "DrvlnRtrdrOvrhtIndctrIsFlashing" 1 "DrvlnRtrdrOvrhtIndctrIsOnCntnsl" 0 "DrvlnRtrdrOvrheatIndicatorIsOff" ;
VAL_ 2631859966 EngBuildHoursReset 2 "Reserved" 3 "TakeNoAction" 1 "Reset" 0 "DoNotReset" ;
VAL_ 2631859966 TripGroup2Proprietary 2 "Reserved" 3 "NotApplicable" 1 "Reset" 0 "TakeNoAction" ;
VAL_ 2631859966 TripGroup1 2 "Reserved" 3 "NotApplicable" 1 "Reset" 0 "TakeNoAction" ;
VAL_ 2631859966 SteerStraightAheadPosReset 3 "NotApplicable" 2 "ReservedTakeNoAction" 1 "Reset" 0 "TakeNoActionDoNotReset" ;
